VERSION "HNNBNNNYNNNNNNNNNNNNNNNNNNNNNNNNNNNNNNNNNN/4/%%%/4/'%**4NNN///"

NS_ :

BS_:

BU_: BAP_Tester BCM Gateway_Max TSGGen3_BFS TSGGen3_FS TSGGen3_HBFS TSGGen3_HFS WLC_01_CFD

BO_ 2463978735 DoorFunctions_HBFS_01: 32 TSGGen3_BFS
 SG_ DoorFunctions_HBFS_01_CRC : 0|8@1+ (1,0) [0|255] ""  Gateway_Max,TSGGen3_BFS,TSGGen3_FS,TSGGen3_HFS
 SG_ DoorFunctions_HBFS_01_BZ : 8|4@1+ (1,0) [0|15] ""  Gateway_Max,TSGGen3_BFS,TSGGen3_FS,TSGGen3_HFS
 SG_ HBFS_FH_S_HFS_ManHoch : 12|1@1+ (1.0,0.0) [0.0|1] ""  Gateway_Max,TSGGen3_BFS,TSGGen3_FS,TSGGen3_HFS
 SG_ HBFS_FH_S_HFS_ManTief : 13|1@1+ (1.0,0.0) [0.0|1] ""  Gateway_Max,TSGGen3_BFS,TSGGen3_FS,TSGGen3_HFS
 SG_ HBFS_Tuer_Status : 14|2@1+ (1.0,0.0) [0.0|3] ""  Gateway_Max,TSGGen3_FS
 SG_ HBFS_SAD_Schalter : 16|4@1+ (1.0,0.0) [0.0|15] ""  Gateway_Max,TSGGen3_BFS
 SG_ HBFS_FH_S_ManHoch : 20|1@1+ (1.0,0.0) [0.0|1] ""  Gateway_Max
 SG_ HBFS_FH_S_AutoHoch : 21|1@1+ (1.0,0.0) [0.0|1] ""  Gateway_Max,TSGGen3_HFS
 SG_ HBFS_FH_S_ManTief : 22|1@1+ (1.0,0.0) [0.0|1] ""  Gateway_Max
 SG_ HBFS_FH_S_AutoTief : 23|1@1+ (1.0,0.0) [0.0|1] ""  Gateway_Max
 SG_ HBFS_FH_Oeffnung : 24|8@1+ (0.5,0) [0.0|100.0] "Unit_PerCent"  Gateway_Max
 SG_ HBFS_FH_Bew_hoch : 32|1@1+ (1.0,0.0) [0.0|1] ""  Gateway_Max,TSGGen3_BFS,TSGGen3_FS
 SG_ HBFS_FH_Bew_tief : 33|1@1+ (1.0,0.0) [0.0|1] ""  Gateway_Max,TSGGen3_BFS,TSGGen3_FS
 SG_ HBFS_FH_Fang : 34|1@1+ (1.0,0.0) [0.0|1] ""  Gateway_Max
 SG_ HBFS_FH_Block : 35|1@1+ (1.0,0.0) [0.0|1] ""  Gateway_Max
 SG_ HBFS_FH_Thermo : 36|1@1+ (1.0,0.0) [0.0|1] ""  Gateway_Max
 SG_ HBFS_UEKB_aktiviert : 37|1@1+ (1.0,0.0) [0.0|1] ""  Gateway_Max
 SG_ HBFS_Tueroeffnen_Warnung : 38|1@1+ (1.0,0.0) [0.0|1] ""  Gateway_Max
 SG_ HBFS_FH_normiert : 39|1@1+ (1.0,0.0) [0.0|1] ""  Gateway_Max,TSGGen3_FS
 SG_ ASW_Warnung_aktiv_HBFS : 40|1@1+ (1.0,0.0) [0.0|1] ""  Gateway_Max
 SG_ HBFS_Zuziehhilfe_aktiv : 41|1@1+ (1.0,0.0) [0.0|1] ""  Gateway_Max
 SG_ HBFS_Seitenrollo_hoch : 42|1@1+ (1.0,0.0) [0.0|1] ""  Gateway_Max
 SG_ HBFS_Seitenrollo_tief : 43|1@1+ (1.0,0.0) [0.0|1] ""  Gateway_Max
 SG_ HBFS_Status_KiSi : 44|1@1+ (1.0,0.0) [0.0|1] ""  Gateway_Max,TSGGen3_BFS,TSGGen3_FS
 SG_ SSR_HBFS_Pos_Unten : 45|1@1+ (1.0,0.0) [0.0|1] ""  Gateway_Max
 SG_ HBFS_Oben_Block_erw : 46|1@1+ (1.0,0.0) [0.0|1] ""  Gateway_Max,TSGGen3_BFS,TSGGen3_FS,TSGGen3_HFS
 SG_ HBFS_Unten_Block_erw : 47|1@1+ (1.0,0.0) [0.0|1] ""  Gateway_Max,TSGGen3_BFS,TSGGen3_FS,TSGGen3_HFS
 SG_ MTHBFS_M_Taste : 48|1@1+ (1.0,0.0) [0.0|1] ""  Gateway_Max
 SG_ MTHBFS_Pos1 : 49|1@1+ (1.0,0.0) [0.0|1] ""  Gateway_Max
 SG_ MTHBFS_Pos2 : 50|1@1+ (1.0,0.0) [0.0|1] ""  Gateway_Max
 SG_ MTHBFS_Pos3 : 51|1@1+ (1.0,0.0) [0.0|1] ""  Gateway_Max
 SG_ HBFS_MRollo_Schalter : 52|3@1+ (1.0,0.0) [0.0|7] ""  Gateway_Max,TSGGen3_BFS
 SG_ HBFS_Lock_Taster_inv : 55|1@1+ (1.0,0.0) [0.0|1] ""  Gateway_Max
 SG_ HBFS_Status_KiSi_inv : 56|1@1+ (1.0,0.0) [0.0|1] ""  Gateway_Max,TSGGen3_BFS,TSGGen3_FS
 SG_ HBFS_Status_eTAG : 57|2@1+ (1.0,0.0) [0.0|3] ""  Gateway_Max,TSGGen3_FS
 SG_ HBFS_Tuer_Status_QBit : 59|1@1+ (1.0,0.0) [0.0|1] ""  Gateway_Max,TSGGen3_FS
 SG_ HBFS_TIG_betaetigt_schliessen : 60|1@1+ (1.0,0.0) [0.0|1] ""  Gateway_Max
 SG_ HBFS_TIG_betaetigt_oeffnen : 61|1@1+ (1.0,0.0) [0.0|1] ""  Gateway_Max
 SG_ HBFS_Vorraste_betaetigt : 62|1@1+ (1.0,0.0) [0.0|1] ""  Gateway_Max
 SG_ HBFS_SK_betaetigt : 63|1@1+ (1.0,0.0) [0.0|1] ""  Gateway_Max
 SG_ HBFS_KiSi_Fehler : 64|1@1+ (1.0,0.0) [0.0|1] ""  Gateway_Max,TSGGen3_FS
 SG_ HBFS_TCR_Mode_aktiv : 65|1@1+ (1.0,0.0) [0.0|1] ""  Gateway_Max,TSGGen3_BFS,TSGGen3_FS,TSGGen3_HFS
 SG_ SSA_HBFT_FH_Thermoschutz : 66|1@1+ (1.0,0.0) [0.0|1] ""  Gateway_Max
 SG_ SSA_HBFT_ZZH_Status : 67|1@1+ (1.0,0.0) [0.0|1] ""  Gateway_Max
 SG_ SSA_HBFT_SSR_Status : 68|2@1+ (1.0,0.0) [0.0|3] ""  Gateway_Max
 SG_ SSA_HBFT_ASW_Status : 70|2@1+ (1.0,0.0) [0.0|3] ""  Gateway_Max,TSGGen3_BFS
 SG_ TSG_FlHz_HBFS_NTC_A : 72|7@1+ (1,-40) [-40|80] "Unit_DegreCelsi"  Gateway_Max
 SG_ TSG_FlHz_HBFS_FnAbbruchHzKreis_A : 79|1@1+ (1.0,0.0) [0.0|1] ""  Gateway_Max
 SG_ TSG_FlHz_HBFS_NTC_B : 80|7@1+ (1,-40) [-40|80] "Unit_DegreCelsi"  Gateway_Max
 SG_ TSG_FlHz_HBFS_FnAbbruchHzKreis_B : 87|1@1+ (1.0,0.0) [0.0|1] ""  Gateway_Max
 SG_ SSA_HBFT_Tuerverschluss_Status : 88|2@1+ (1.0,0.0) [0.0|3] ""  Gateway_Max
 SG_ SSA_HBFT_el_Tuerantrieb_Status : 90|2@1+ (1.0,0.0) [0.0|3] ""  Gateway_Max
 SG_ SSA_HBFT_Amb_Bel_Status : 92|2@1+ (1.0,0.0) [0.0|3] ""  Gateway_Max
 SG_ SSA_HBFT_FH_Bewegungsrichutng : 94|2@1+ (1.0,0.0) [0.0|3] ""  Gateway_Max
 SG_ BFS_Lehnenkopf_vor : 96|1@1+ (1.0,0.0) [0.0|1] ""  Gateway_Max
 SG_ BFS_Lehnenkopf_zurueck : 97|1@1+ (1.0,0.0) [0.0|1] ""  Gateway_Max
 SG_ BFS_Lehnenneigung_vor : 98|1@1+ (1.0,0.0) [0.0|1] ""  Gateway_Max
 SG_ BFS_Lehnenneigung_zurueck : 99|1@1+ (1.0,0.0) [0.0|1] ""  Gateway_Max
 SG_ BFS_Sitzhoehe_hoch : 100|1@1+ (1.0,0.0) [0.0|1] ""  Gateway_Max
 SG_ BFS_Sitzhoehe_runter : 101|1@1+ (1.0,0.0) [0.0|1] ""  Gateway_Max
 SG_ BFS_Kopfstuetzen_hoch : 102|1@1+ (1.0,0.0) [0.0|1] ""  Gateway_Max
 SG_ BFS_Kopfstuetzen_runter : 103|1@1+ (1.0,0.0) [0.0|1] ""  Gateway_Max
 SG_ BFS_Laengsverst_vor : 104|1@1+ (1.0,0.0) [0.0|1] ""  Gateway_Max
 SG_ BFS_Laengsverst_zurueck : 105|1@1+ (1.0,0.0) [0.0|1] ""  Gateway_Max
 SG_ MTHBF_ein : 106|1@1+ (1.0,0.0) [0.0|1] ""  Gateway_Max
 SG_ SSA_HBFS_eKisi_Status : 107|2@1+ (1.0,0.0) [0.0|3] ""  Gateway_Max
 SG_ SSA_HBFT_Tuerverschluss_Fehler : 109|3@1+ (1.0,0.0) [0.0|7] ""  Gateway_Max
 SG_ SSA_HBFT_FH_Fehler : 112|3@1+ (1.0,0.0) [0.0|7] ""  Gateway_Max
 SG_ SSA_HBFS_eKisi_Fehler : 115|3@1+ (1.0,0.0) [0.0|7] ""  Gateway_Max
 SG_ SSA_HBFT_Amb_Bel_Fehler : 118|3@1+ (1.0,0.0) [0.0|7] ""  Gateway_Max
 SG_ SSA_HBFT_FH_Normierung : 121|1@1+ (1.0,0.0) [0.0|1] ""  Gateway_Max
 SG_ SSA_HBFT_el_Tuerantrieb_Fehler : 122|3@1+ (1.0,0.0) [0.0|7] ""  Gateway_Max
 SG_ SSA_HBFT_ZZH_Fehler : 125|3@1+ (1.0,0.0) [0.0|7] ""  Gateway_Max
 SG_ SSA_HBFT_ZV_Fehler : 128|3@1+ (1.0,0.0) [0.0|7] ""  Gateway_Max
 SG_ SSA_HBFT_ASW_Fehler : 131|3@1+ (1.0,0.0) [0.0|7] ""  Gateway_Max
 SG_ SSA_HBFT_SSR_Fehler : 134|3@1+ (1.0,0.0) [0.0|7] ""  Gateway_Max
 SG_ eTAB_HBFS_Oeffnen_Annaeh : 137|1@1+ (1.0,0.0) [0.0|1] ""  Gateway_Max
 SG_ eTAB_HBFS_Oeffnen_Betaet : 138|1@1+ (1.0,0.0) [0.0|1] ""  Gateway_Max
 SG_ eTAB_HBFS_Schliessen_Annaeh : 139|1@1+ (1.0,0.0) [0.0|1] ""  Gateway_Max
 SG_ HBFS_ASW_Warnung_Aussenlicht : 140|2@1+ (1.0,0.0) [0.0|3] ""  Gateway_Max
 SG_ HBFS_ASW_Warnton : 142|2@1+ (1.0,0.0) [0.0|3] ""  Gateway_Max
 SG_ HBFS_Tuer_geoeffnet : 144|1@1+ (1.0,0.0) [0.0|1] ""  Gateway_Max,TSGGen3_BFS,TSGGen3_FS,TSGGen3_HFS
 SG_ HBFS_verriegelt : 145|1@1+ (1.0,0.0) [0.0|1] ""  Gateway_Max,TSGGen3_FS
 SG_ HBFS_gesafet : 146|1@1+ (1.0,0.0) [0.0|1] ""  Gateway_Max,TSGGen3_FS
 SG_ HBFS_Heckrollotaster_betaetigt : 147|1@1+ (1.0,0.0) [0.0|1] ""  Gateway_Max
 SG_ HBFS_Tuerschloss_defekt : 148|1@1+ (1.0,0.0) [0.0|1] ""  Gateway_Max,TSGGen3_BFS,TSGGen3_FS,TSGGen3_HFS
 SG_ HBFS_Unlock_Taster : 149|1@1+ (1.0,0.0) [0.0|1] ""  Gateway_Max
 SG_ HBFS_Lock_Taster : 150|1@1+ (1.0,0.0) [0.0|1] ""  Gateway_Max
 SG_ HBFS_Sperrklinke : 151|1@1+ (1.0,0.0) [0.0|1] ""  Gateway_Max
 SG_ HBFS_TAG_betaetigt : 152|1@1+ (1.0,0.0) [0.0|1] ""  Gateway_Max
 SG_ HBFS_TIG_betaetigt : 153|1@1+ (1.0,0.0) [0.0|1] ""  Gateway_Max
 SG_ HBFS_FH_S_HFS_AutoHoch : 154|1@1+ (1.0,0.0) [0.0|1] ""  Gateway_Max,TSGGen3_BFS,TSGGen3_FS,TSGGen3_HFS
 SG_ HBFS_FH_S_HFS_AutoTief : 155|1@1+ (1.0,0.0) [0.0|1] ""  Gateway_Max,TSGGen3_BFS,TSGGen3_FS,TSGGen3_HFS
 SG_ SSA_HBFT_FH_Oeffnungsweite : 156|8@1+ (0.5,0) [0.0|100.0] "Unit_PerCent"  Gateway_Max,TSGGen3_FS,TSGGen3_HFS
 SG_ TSG_FlHz_HBFS_Unterbrech_HzK_A : 164|1@1+ (1.0,0.0) [0.0|1] ""  Gateway_Max
 SG_ TSG_FlHz_HBFS_Unterbrech_HzK_B : 165|1@1+ (1.0,0.0) [0.0|1] ""  Gateway_Max
 SG_ HBFS_ASW_HMI_defekt : 176|1@1+ (1.0,0.0) [0.0|1] ""  Gateway_Max,TSGGen3_FS
 SG_ eTAB_HBFS_Schliessen_Betaet : 177|1@1+ (1.0,0.0) [0.0|1] ""  Gateway_Max
 SG_ HBFS_Push_Tuergriff : 179|1@1+ (1.0,0.0) [0.0|1] ""  Gateway_Max
 SG_ HBFS_Status_eTAG_ext : 180|3@1+ (1.0,0.0) [0.0|7] ""  Gateway_Max
 SG_ HBFS_Schloss_Status_OeH_Motor : 184|2@1+ (1.0,0.0) [0.0|3] ""  Gateway_Max
 SG_ HBFS_Schloss_oeffnen_Ansteuerung : 186|2@1+ (1.0,0.0) [0.0|3] ""  Gateway_Max
 SG_ SOK_Doorfunctions_HBFS_01_Sig001 : 224|32@1+ (1.0,0.0) [0.0|4294967295] ""  Gateway_Max

BO_ 2463978736 DoorFunctions_HFS_01: 32 TSGGen3_FS
 SG_ DoorFunctions_HFS_01_CRC : 0|8@1+ (1,0) [0|255] ""  Gateway_Max,TSGGen3_BFS,TSGGen3_FS,TSGGen3_HBFS
 SG_ DoorFunctions_HFS_01_BZ : 8|4@1+ (1,0) [0|15] ""  Gateway_Max,TSGGen3_BFS,TSGGen3_FS,TSGGen3_HBFS
 SG_ HFS_FH_S_HBFS_ManHoch : 12|1@1+ (1.0,0.0) [0.0|1] ""  Gateway_Max,TSGGen3_BFS,TSGGen3_FS,TSGGen3_HBFS
 SG_ HFS_FH_S_HBFS_ManTief : 13|1@1+ (1.0,0.0) [0.0|1] ""  Gateway_Max,TSGGen3_BFS,TSGGen3_FS,TSGGen3_HBFS
 SG_ HFS_Tuer_Status : 14|2@1+ (1.0,0.0) [0.0|3] ""  Gateway_Max,TSGGen3_FS
 SG_ HFS_SAD_Schalter : 16|4@1+ (1.0,0.0) [0.0|15] ""  Gateway_Max
 SG_ HFS_FH_S_ManHoch : 20|1@1+ (1.0,0.0) [0.0|1] ""  Gateway_Max
 SG_ HFS_FH_S_AutoHoch : 21|1@1+ (1.0,0.0) [0.0|1] ""  Gateway_Max
 SG_ HFS_FH_S_ManTief : 22|1@1+ (1.0,0.0) [0.0|1] ""  Gateway_Max
 SG_ HFS_FH_S_AutoTief : 23|1@1+ (1.0,0.0) [0.0|1] ""  Gateway_Max
 SG_ HFS_FH_Oeffnung : 24|8@1+ (0.5,0) [0.0|100.0] "Unit_PerCent"  Gateway_Max
 SG_ HFS_FH_Bew_hoch : 32|1@1+ (1.0,0.0) [0.0|1] ""  Gateway_Max,TSGGen3_BFS,TSGGen3_FS,TSGGen3_HBFS
 SG_ HFS_FH_Bew_tief : 33|1@1+ (1.0,0.0) [0.0|1] ""  Gateway_Max,TSGGen3_BFS,TSGGen3_FS,TSGGen3_HBFS
 SG_ HFS_FH_Fang : 34|1@1+ (1.0,0.0) [0.0|1] ""  Gateway_Max
 SG_ HFS_FH_Block : 35|1@1+ (1.0,0.0) [0.0|1] ""  Gateway_Max
 SG_ HFS_FH_Thermo : 36|1@1+ (1.0,0.0) [0.0|1] ""  Gateway_Max
 SG_ HFS_UEKB_aktiviert : 37|1@1+ (1.0,0.0) [0.0|1] ""  Gateway_Max
 SG_ HFS_Tueroeffnen_Warnung : 38|1@1+ (1.0,0.0) [0.0|1] ""  Gateway_Max
 SG_ HFS_FH_normiert : 39|1@1+ (1.0,0.0) [0.0|1] ""  Gateway_Max,TSGGen3_BFS,TSGGen3_FS,TSGGen3_HBFS
 SG_ ASW_Warnung_aktiv_HFS : 40|1@1+ (1.0,0.0) [0.0|1] ""  Gateway_Max
 SG_ HFS_Zuziehhilfe_aktiv : 41|1@1+ (1.0,0.0) [0.0|1] ""  Gateway_Max
 SG_ HFS_Seitenrollo_hoch : 42|1@1+ (1.0,0.0) [0.0|1] ""  Gateway_Max
 SG_ HFS_Seitenrollo_tief : 43|1@1+ (1.0,0.0) [0.0|1] ""  Gateway_Max
 SG_ HFS_Status_KiSi : 44|1@1+ (1.0,0.0) [0.0|1] ""  Gateway_Max,TSGGen3_BFS,TSGGen3_FS,TSGGen3_HBFS
 SG_ SSR_HFS_Pos_Unten : 45|1@1+ (1.0,0.0) [0.0|1] ""  Gateway_Max,TSGGen3_BFS,TSGGen3_HBFS
 SG_ HFS_Oben_Block_erw : 46|1@1+ (1.0,0.0) [0.0|1] ""  Gateway_Max,TSGGen3_BFS,TSGGen3_FS,TSGGen3_HBFS
 SG_ HFS_Unten_Block_erw : 47|1@1+ (1.0,0.0) [0.0|1] ""  Gateway_Max,TSGGen3_BFS,TSGGen3_FS,TSGGen3_HBFS
 SG_ MTHFS_M_Taste : 48|1@1+ (1.0,0.0) [0.0|1] ""  Gateway_Max
 SG_ MTHFS_Pos1 : 49|1@1+ (1.0,0.0) [0.0|1] ""  Gateway_Max
 SG_ MTHFS_Pos2 : 50|1@1+ (1.0,0.0) [0.0|1] ""  Gateway_Max
 SG_ MTHFS_Pos3 : 51|1@1+ (1.0,0.0) [0.0|1] ""  Gateway_Max
 SG_ HFS_MRollo_Schalter : 52|3@1+ (1.0,0.0) [0.0|7] ""  Gateway_Max
 SG_ HFS_Lock_Taster_inv : 55|1@1+ (1.0,0.0) [0.0|1] ""  Gateway_Max
 SG_ HFS_Status_eTAG : 56|2@1+ (1.0,0.0) [0.0|3] ""  Gateway_Max,TSGGen3_BFS,TSGGen3_HBFS
 SG_ HFS_Tuer_Status_QBit : 58|1@1+ (1.0,0.0) [0.0|1] ""  Gateway_Max,TSGGen3_FS
 SG_ HFS_TCR_Mode_aktiv : 59|1@1+ (1.0,0.0) [0.0|1] ""  Gateway_Max,TSGGen3_BFS,TSGGen3_FS,TSGGen3_HBFS
 SG_ HFS_TIG_betaetigt_schliessen : 60|1@1+ (1.0,0.0) [0.0|1] ""  Gateway_Max
 SG_ HFS_TIG_betaetigt_oeffnen : 61|1@1+ (1.0,0.0) [0.0|1] ""  Gateway_Max
 SG_ HFS_Vorraste_betaetigt : 62|1@1+ (1.0,0.0) [0.0|1] ""  Gateway_Max
 SG_ HFS_SK_betaetigt : 63|1@1+ (1.0,0.0) [0.0|1] ""  Gateway_Max
 SG_ TSG_FlHz_HFS_NTC_A : 64|7@1+ (1,-40) [-40|80] "Unit_DegreCelsi"  Gateway_Max
 SG_ TSG_FlHz_HFS_FnAbbruchHzKreis_A : 71|1@1+ (1.0,0.0) [0.0|1] ""  Gateway_Max
 SG_ TSG_FlHz_HFS_NTC_B : 72|7@1+ (1,-40) [-40|80] "Unit_DegreCelsi"  Gateway_Max
 SG_ TSG_FlHz_HFS_FnAbbruchHzKreis_B : 79|1@1+ (1.0,0.0) [0.0|1] ""  Gateway_Max
 SG_ SSA_HFT_Tuerverschluss_Status : 80|2@1+ (1.0,0.0) [0.0|3] ""  Gateway_Max
 SG_ SSA_HFT_el_Tuerantrieb_Status : 82|2@1+ (1.0,0.0) [0.0|3] ""  Gateway_Max
 SG_ SSA_HFT_ZV_Status : 84|4@1+ (1.0,0.0) [0.0|15] ""  Gateway_Max
 SG_ eTAB_HFS_Oeffnen_Annaeh : 88|1@1+ (1.0,0.0) [0.0|1] ""  Gateway_Max
 SG_ eTAB_HFS_Oeffnen_Betaet : 89|1@1+ (1.0,0.0) [0.0|1] ""  Gateway_Max
 SG_ eTAB_HFS_Schliessen_Annaeh : 90|1@1+ (1.0,0.0) [0.0|1] ""  Gateway_Max
 SG_ eTAB_HFS_Schliessen_Betaet : 91|1@1+ (1.0,0.0) [0.0|1] ""  Gateway_Max
 SG_ SSA_HFT_Amb_Bel_Status : 92|2@1+ (1.0,0.0) [0.0|3] ""  Gateway_Max
 SG_ SSA_HFT_FH_Bewegungsrichutng : 94|2@1+ (1.0,0.0) [0.0|3] ""  Gateway_Max
 SG_ SSA_HFT_SSR_Status : 96|2@1+ (1.0,0.0) [0.0|3] ""  Gateway_Max
 SG_ SSA_HFS_eKisi_Status : 98|2@1+ (1.0,0.0) [0.0|3] ""  Gateway_Max
 SG_ SSA_HFT_ZZH_Status : 100|1@1+ (1.0,0.0) [0.0|1] ""  Gateway_Max
 SG_ SSA_HFT_ASW_Status : 101|2@1+ (1.0,0.0) [0.0|3] ""  Gateway_Max,TSGGen3_FS
 SG_ SSA_HFT_ZV_Ansteuern : 103|8@1+ (1.0,0.0) [0.0|255] ""  Gateway_Max
 SG_ SSA_HFT_FH_Thermoschutz : 111|1@1+ (1.0,0.0) [0.0|1] ""  Gateway_Max
 SG_ SSA_HFT_Tuerverschluss_Fehler : 112|3@1+ (1.0,0.0) [0.0|7] ""  Gateway_Max
 SG_ SSA_HFT_SSR_Fehler : 115|3@1+ (1.0,0.0) [0.0|7] ""  Gateway_Max
 SG_ SSA_HFT_Amb_Bel_Fehler : 118|3@1+ (1.0,0.0) [0.0|7] ""  Gateway_Max
 SG_ SSA_HFT_FH_Fehler : 121|3@1+ (1.0,0.0) [0.0|7] ""  Gateway_Max
 SG_ SSA_HFS_eKisi_Fehler : 124|3@1+ (1.0,0.0) [0.0|7] ""  Gateway_Max
 SG_ SSA_HFT_ZZH_Fehler : 127|3@1+ (1.0,0.0) [0.0|7] ""  Gateway_Max
 SG_ SSA_HFT_ZV_Fehler : 130|3@1+ (1.0,0.0) [0.0|7] ""  Gateway_Max
 SG_ SSA_HFT_el_Tuerantrieb_Fehler : 133|3@1+ (1.0,0.0) [0.0|7] ""  Gateway_Max
 SG_ SSA_HFT_ASW_Fehler : 136|3@1+ (1.0,0.0) [0.0|7] ""  Gateway_Max
 SG_ SSA_HFT_FH_Normierung : 139|1@1+ (1.0,0.0) [0.0|1] ""  Gateway_Max
 SG_ HFS_Schloss_Status_OeH_Motor : 140|2@1+ (1.0,0.0) [0.0|3] ""  Gateway_Max
 SG_ HFS_Tuer_geoeffnet : 144|1@1+ (1.0,0.0) [0.0|1] ""  Gateway_Max,TSGGen3_BFS,TSGGen3_FS,TSGGen3_HBFS
 SG_ HFS_verriegelt : 145|1@1+ (1.0,0.0) [0.0|1] ""  Gateway_Max,TSGGen3_FS
 SG_ HFS_gesafet : 146|1@1+ (1.0,0.0) [0.0|1] ""  Gateway_Max,TSGGen3_BFS,TSGGen3_HBFS
 SG_ HFS_Heckrollotaster_betaetigt : 147|1@1+ (1.0,0.0) [0.0|1] ""  Gateway_Max
 SG_ HFS_Tuerschloss_defekt : 148|1@1+ (1.0,0.0) [0.0|1] ""  Gateway_Max,TSGGen3_BFS,TSGGen3_FS,TSGGen3_HBFS
 SG_ HFS_Unlock_Taster : 149|1@1+ (1.0,0.0) [0.0|1] ""  Gateway_Max
 SG_ HFS_Lock_Taster : 150|1@1+ (1.0,0.0) [0.0|1] ""  Gateway_Max
 SG_ HFS_Sperrklinke : 151|1@1+ (1.0,0.0) [0.0|1] ""  Gateway_Max
 SG_ HFS_TAG_betaetigt : 152|1@1+ (1.0,0.0) [0.0|1] ""  Gateway_Max
 SG_ HFS_TIG_betaetigt : 153|1@1+ (1.0,0.0) [0.0|1] ""  Gateway_Max
 SG_ HFS_FH_S_HBFS_AutoHoch : 154|1@1+ (1.0,0.0) [0.0|1] ""  Gateway_Max,TSGGen3_BFS,TSGGen3_FS,TSGGen3_HBFS
 SG_ HFS_FH_S_HBFS_AutoTief : 155|1@1+ (1.0,0.0) [0.0|1] ""  Gateway_Max,TSGGen3_BFS,TSGGen3_FS,TSGGen3_HBFS
 SG_ TSG_FlHz_HFS_Unterbrech_HzK_A : 156|1@1+ (1.0,0.0) [0.0|1] ""  Gateway_Max
 SG_ HFS_Push_Tuergriff : 159|1@1+ (1.0,0.0) [0.0|1] ""  Gateway_Max
 SG_ HFS_Status_eTAG_ext : 202|3@1+ (1.0,0.0) [0.0|7] ""  Gateway_Max
 SG_ HFS_KiSi_Fehler : 205|1@1+ (1.0,0.0) [0.0|1] ""  Gateway_Max,TSGGen3_FS
 SG_ HFS_ASW_Warnton : 206|2@1+ (1.0,0.0) [0.0|3] ""  Gateway_Max,TSGGen3_BFS,TSGGen3_FS
 SG_ HFS_Schloss_oeffnen_Ansteuerung : 208|2@1+ (1.0,0.0) [0.0|3] ""  Gateway_Max
 SG_ HFS_ASW_HMI_defekt : 212|1@1+ (1.0,0.0) [0.0|1] ""  Gateway_Max,TSGGen3_FS
 SG_ HFS_ASW_Warnung_Aussenlicht : 213|2@1+ (1.0,0.0) [0.0|3] ""  Gateway_Max
 SG_ SOK_Doorfunctions_HFS_01_Sign002 : 224|32@1+ (1.0,0.0) [0.0|4294967295] ""  Gateway_Max

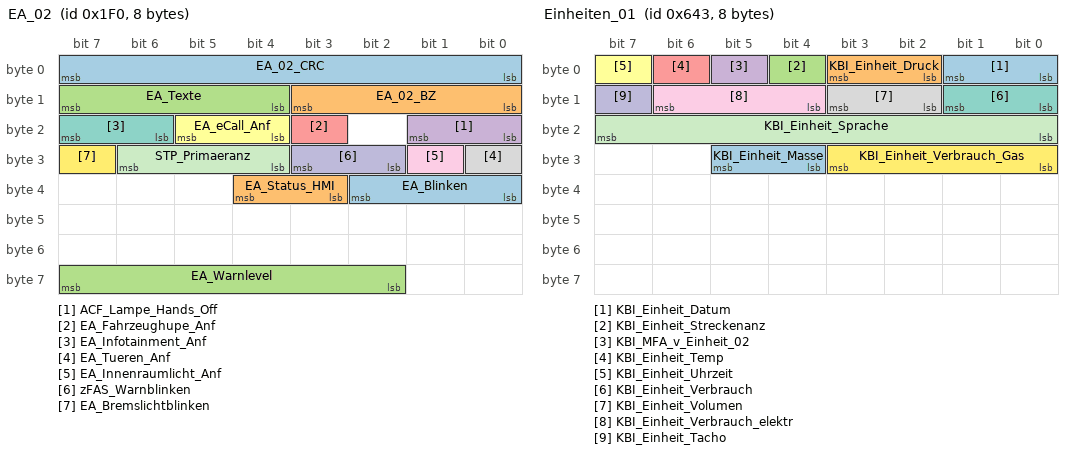
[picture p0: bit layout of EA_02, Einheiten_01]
BO_ 496 EA_02: 8 Gateway_Max
 SG_ EA_02_CRC : 0|8@1+ (1,0) [0|255] ""  BCM
 SG_ EA_02_BZ : 8|4@1+ (1,0) [0|15] ""  BCM
 SG_ EA_Texte : 12|4@1+ (1.0,0.0) [0.0|15] ""  Vector__XXX
 SG_ ACF_Lampe_Hands_Off : 16|2@1+ (1.0,0.0) [0.0|3] ""  Vector__XXX
 SG_ EA_Fahrzeughupe_Anf : 19|1@1+ (1.0,0.0) [0.0|1] ""  BCM
 SG_ EA_eCall_Anf : 20|2@1+ (1.0,0.0) [0.0|3] ""  Vector__XXX
 SG_ EA_Infotainment_Anf : 22|2@1+ (1.0,0.0) [0.0|3] ""  Vector__XXX
 SG_ EA_Tueren_Anf : 24|1@1+ (1.0,0.0) [0.0|1] ""  BCM
 SG_ EA_Innenraumlicht_Anf : 25|1@1+ (1.0,0.0) [0.0|1] ""  BCM
 SG_ zFAS_Warnblinken : 26|2@1+ (1.0,0.0) [0.0|3] ""  Vector__XXX
 SG_ STP_Primaeranz : 28|3@1+ (1.0,0.0) [0.0|7] ""  Vector__XXX
 SG_ EA_Bremslichtblinken : 31|1@1+ (1.0,0.0) [0.0|1] ""  BCM
 SG_ EA_Blinken : 32|3@1+ (1.0,0.0) [0.0|7] ""  BCM
 SG_ EA_Status_HMI : 35|2@1+ (1.0,0.0) [0.0|3] ""  Vector__XXX
 SG_ EA_Warnlevel : 58|6@1+ (1.0,0.0) [0.0|63] ""  Vector__XXX

BO_ 1603 Einheiten_01: 8 Gateway_Max
 SG_ KBI_Einheit_Datum : 0|2@1+ (1.0,0.0) [0.0|3] ""  BCM
 SG_ KBI_Einheit_Druck : 2|2@1+ (1.0,0.0) [0.0|3] ""  BCM
 SG_ KBI_Einheit_Streckenanz : 4|1@1+ (1.0,0.0) [0.0|1] ""  BCM
 SG_ KBI_MFA_v_Einheit_02 : 5|1@1+ (1.0,0.0) [0.0|1] ""  BCM
 SG_ KBI_Einheit_Temp : 6|1@1+ (1.0,0.0) [0.0|1] ""  BCM
 SG_ KBI_Einheit_Uhrzeit : 7|1@1+ (1.0,0.0) [0.0|1] ""  BCM
 SG_ KBI_Einheit_Verbrauch : 8|2@1+ (1.0,0.0) [0.0|3] ""  BCM
 SG_ KBI_Einheit_Volumen : 10|2@1+ (1.0,0.0) [0.0|3] ""  BCM
 SG_ KBI_Einheit_Verbrauch_elektr : 12|3@1+ (1.0,0.0) [0.0|7] ""  BCM
 SG_ KBI_Einheit_Tacho : 15|1@1+ (1.0,0.0) [0.0|1] ""  BCM
 SG_ KBI_Einheit_Sprache : 16|8@1+ (1,0) [0|255] ""  BCM
 SG_ KBI_Einheit_Verbrauch_Gas : 24|4@1+ (1.0,0.0) [0.0|15] ""  BCM
 SG_ KBI_Einheit_Masse : 28|2@1+ (1.0,0.0) [0.0|3] ""  BCM

BO_ 1622 ELV_01: 8 Gateway_Max
 SG_ ELV_01_CRC : 0|8@1+ (1,0) [0|255] ""  BCM
 SG_ ELV_01_BZ : 8|4@1+ (1,0) [0|15] ""  BCM
 SG_ ELV_Anf_Klemme_S : 12|1@1+ (1.0,0.0) [0.0|1] ""  BCM
 SG_ ELV_Anf_Klemme_15 : 13|1@1+ (1.0,0.0) [0.0|1] ""  BCM
 SG_ ELV_Anf_Klemme_50 : 14|1@1+ (1.0,0.0) [0.0|1] ""  BCM
 SG_ ELV_01_Sendestatus : 15|1@1+ (1.0,0.0) [0.0|1] ""  BCM
 SG_ ELV_Verriegelt : 16|1@1+ (1.0,0.0) [0.0|1] ""  BCM
 SG_ ELV_Entriegelt : 17|1@1+ (1.0,0.0) [0.0|1] ""  BCM
 SG_ ELV_ZAT_betaetigt : 18|1@1+ (1.0,0.0) [0.0|1] ""  BCM
 SG_ ELV_Lebenszustand : 19|1@1+ (1.0,0.0) [0.0|1] ""  BCM
 SG_ ELV_Anlernmodus : 20|1@1+ (1.0,0.0) [0.0|1] ""  BCM
 SG_ KST_aut_Abschaltung_Zuendung : 21|1@1+ (1.0,0.0) [0.0|1] ""  BCM
 SG_ ELV_Klemmenfreigabe : 22|1@1+ (1.0,0.0) [0.0|1] ""  BCM
 SG_ ELV_Abbruch_Anf_Klemmenfreigabe : 23|1@1+ (1.0,0.0) [0.0|1] ""  BCM
 SG_ ELV_LED_Rot : 24|1@1+ (1.0,0.0) [0.0|1] ""  BCM
 SG_ ELV_LED_Gelb : 25|1@1+ (1.0,0.0) [0.0|1] ""  BCM
 SG_ ELV_Txt_Panikabschaltung : 27|1@1+ (1.0,0.0) [0.0|1] ""  BCM
 SG_ ELV_Txt_Lkg_Bewegen : 28|1@1+ (1.0,0.0) [0.0|1] ""  BCM
 SG_ ELV_Txt_Werkstatt : 29|1@1+ (1.0,0.0) [0.0|1] ""  BCM
 SG_ ELV_Txt_Defekt : 30|1@1+ (1.0,0.0) [0.0|1] ""  BCM
 SG_ ELV_Txt_P_Gang : 31|1@1+ (1.0,0.0) [0.0|1] ""  BCM
 SG_ ELV_Txt_PN_Gang : 32|1@1+ (1.0,0.0) [0.0|1] ""  BCM
 SG_ ELV_Txt_Kupplung : 33|1@1+ (1.0,0.0) [0.0|1] ""  BCM
 SG_ ELV_Txt_Bremse : 34|1@1+ (1.0,0.0) [0.0|1] ""  BCM
 SG_ ELV_P_verriegelt : 35|1@1+ (1.0,0.0) [0.0|1] ""  BCM
 SG_ KST_Txt_Komfortabschaltung : 36|1@1+ (1.0,0.0) [0.0|1] ""  BCM
 SG_ KST_Anf_ZV_Verriegelung : 37|1@1+ (1.0,0.0) [0.0|1] ""  BCM

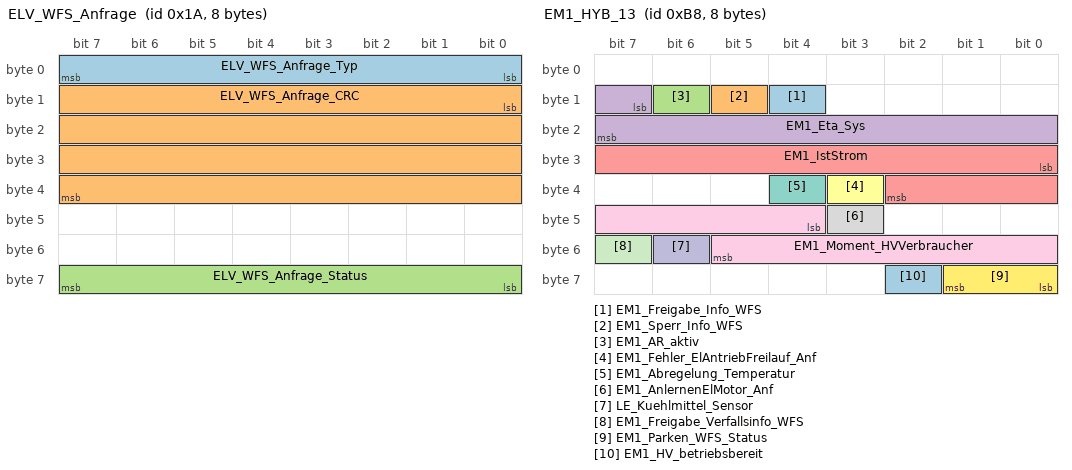
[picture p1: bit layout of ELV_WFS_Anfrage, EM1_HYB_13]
BO_ 26 ELV_WFS_Anfrage: 8 Gateway_Max
 SG_ ELV_WFS_Anfrage_Typ : 0|8@1+ (1.0,0.0) [0.0|255] ""  BCM
 SG_ ELV_WFS_Anfrage_CRC : 8|32@1+ (1.0,0.0) [0.0|4294967295] ""  BCM
 SG_ ELV_WFS_Anfrage_Status : 56|8@1+ (1.0,0.0) [0.0|255] ""  BCM

BO_ 184 EM1_HYB_13: 8 Gateway_Max
 SG_ EM1_Freigabe_Info_WFS : 12|1@1+ (1.0,0.0) [0.0|1] ""  Vector__XXX
 SG_ EM1_Sperr_Info_WFS : 13|1@1+ (1.0,0.0) [0.0|1] ""  BCM
 SG_ EM1_AR_aktiv : 14|1@1+ (1.0,0.0) [0.0|1] ""  Vector__XXX
 SG_ EM1_Eta_Sys : 15|9@1+ (0.2,0) [0.0|101.8] "Unit_PerCent"  Vector__XXX
 SG_ EM1_IstStrom : 24|11@1+ (1,-1023) [-1023|1022] "Unit_Amper"  Vector__XXX
 SG_ EM1_Fehler_ElAntriebFreilauf_Anf : 35|1@1+ (1.0,0.0) [0.0|1] ""  Vector__XXX
 SG_ EM1_Abregelung_Temperatur : 36|1@1+ (1.0,0.0) [0.0|1] ""  Vector__XXX
 SG_ EM1_AnlernenElMotor_Anf : 43|1@1+ (1.0,0.0) [0.0|1] ""  Vector__XXX
 SG_ EM1_Moment_HVVerbraucher : 44|10@1+ (1,-511) [-511|511] "Unit_NewtoMeter"  Vector__XXX
 SG_ LE_Kuehlmittel_Sensor : 54|1@1+ (1.0,0.0) [0.0|1] ""  Vector__XXX
 SG_ EM1_Freigabe_Verfallsinfo_WFS : 55|1@1+ (1.0,0.0) [0.0|1] ""  Vector__XXX
 SG_ EM1_Parken_WFS_Status : 56|2@1+ (1.0,0.0) [0.0|3] ""  Vector__XXX
 SG_ EM1_HV_betriebsbereit : 58|1@1+ (1.0,0.0) [0.0|1] ""  Vector__XXX

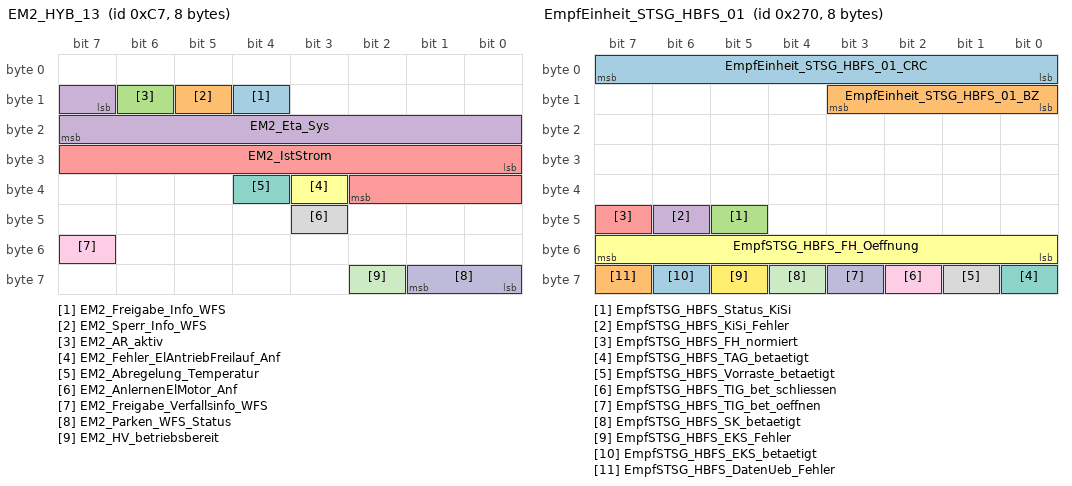
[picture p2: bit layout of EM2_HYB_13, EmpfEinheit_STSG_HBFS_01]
BO_ 199 EM2_HYB_13: 8 Gateway_Max
 SG_ EM2_Freigabe_Info_WFS : 12|1@1+ (1.0,0.0) [0.0|1] ""  Vector__XXX
 SG_ EM2_Sperr_Info_WFS : 13|1@1+ (1.0,0.0) [0.0|1] ""  BCM
 SG_ EM2_AR_aktiv : 14|1@1+ (1.0,0.0) [0.0|1] ""  Vector__XXX
 SG_ EM2_Eta_Sys : 15|9@1+ (0.2,0) [0.0|101.8] "Unit_PerCent"  Vector__XXX
 SG_ EM2_IstStrom : 24|11@1+ (1,-1023) [-1023|1022] "Unit_Amper"  Vector__XXX
 SG_ EM2_Fehler_ElAntriebFreilauf_Anf : 35|1@1+ (1.0,0.0) [0.0|1] ""  Vector__XXX
 SG_ EM2_Abregelung_Temperatur : 36|1@1+ (1.0,0.0) [0.0|1] ""  Vector__XXX
 SG_ EM2_AnlernenElMotor_Anf : 43|1@1+ (1.0,0.0) [0.0|1] ""  Vector__XXX
 SG_ EM2_Freigabe_Verfallsinfo_WFS : 55|1@1+ (1.0,0.0) [0.0|1] ""  Vector__XXX
 SG_ EM2_Parken_WFS_Status : 56|2@1+ (1.0,0.0) [0.0|3] ""  Vector__XXX
 SG_ EM2_HV_betriebsbereit : 58|1@1+ (1.0,0.0) [0.0|1] ""  Vector__XXX

BO_ 624 EmpfEinheit_STSG_HBFS_01: 8 TSGGen3_HBFS
 SG_ EmpfEinheit_STSG_HBFS_01_CRC : 0|8@1+ (1,0) [0|255] ""  Gateway_Max,TSGGen3_BFS,TSGGen3_FS
 SG_ EmpfEinheit_STSG_HBFS_01_BZ : 8|4@1+ (1,0) [0|15] ""  Gateway_Max,TSGGen3_BFS,TSGGen3_FS
 SG_ EmpfSTSG_HBFS_Status_KiSi : 45|1@1+ (1.0,0.0) [0.0|1] ""  Gateway_Max,TSGGen3_BFS,TSGGen3_FS
 SG_ EmpfSTSG_HBFS_KiSi_Fehler : 46|1@1+ (1.0,0.0) [0.0|1] ""  Gateway_Max,TSGGen3_BFS,TSGGen3_FS
 SG_ EmpfSTSG_HBFS_FH_normiert : 47|1@1+ (1.0,0.0) [0.0|1] ""  Gateway_Max
 SG_ EmpfSTSG_HBFS_FH_Oeffnung : 48|8@1+ (0.5,0) [0.0|100.0] "Unit_PerCent"  Gateway_Max
 SG_ EmpfSTSG_HBFS_TAG_betaetigt : 56|1@1+ (1.0,0.0) [0.0|1] ""  Gateway_Max
 SG_ EmpfSTSG_HBFS_Vorraste_betaetigt : 57|1@1+ (1.0,0.0) [0.0|1] ""  Gateway_Max
 SG_ EmpfSTSG_HBFS_TIG_bet_schliessen : 58|1@1+ (1.0,0.0) [0.0|1] ""  Gateway_Max
 SG_ EmpfSTSG_HBFS_TIG_bet_oeffnen : 59|1@1+ (1.0,0.0) [0.0|1] ""  BCM,Gateway_Max
 SG_ EmpfSTSG_HBFS_SK_betaetigt : 60|1@1+ (1.0,0.0) [0.0|1] ""  Gateway_Max
 SG_ EmpfSTSG_HBFS_EKS_Fehler : 61|1@1+ (1.0,0.0) [0.0|1] ""  Gateway_Max
 SG_ EmpfSTSG_HBFS_EKS_betaetigt : 62|1@1+ (1.0,0.0) [0.0|1] ""  Gateway_Max
 SG_ EmpfSTSG_HBFS_DatenUeb_Fehler : 63|1@1+ (1.0,0.0) [0.0|1] ""  Gateway_Max

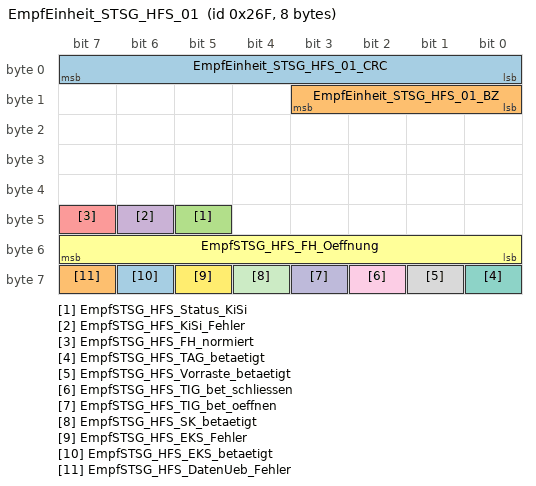
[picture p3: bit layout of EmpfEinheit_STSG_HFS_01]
BO_ 623 EmpfEinheit_STSG_HFS_01: 8 TSGGen3_HFS
 SG_ EmpfEinheit_STSG_HFS_01_CRC : 0|8@1+ (1,0) [0|255] ""  Gateway_Max,TSGGen3_BFS,TSGGen3_FS
 SG_ EmpfEinheit_STSG_HFS_01_BZ : 8|4@1+ (1,0) [0|15] ""  Gateway_Max,TSGGen3_BFS,TSGGen3_FS
 SG_ EmpfSTSG_HFS_Status_KiSi : 45|1@1+ (1.0,0.0) [0.0|1] ""  Gateway_Max,TSGGen3_BFS,TSGGen3_FS
 SG_ EmpfSTSG_HFS_KiSi_Fehler : 46|1@1+ (1.0,0.0) [0.0|1] ""  Gateway_Max,TSGGen3_BFS,TSGGen3_FS
 SG_ EmpfSTSG_HFS_FH_normiert : 47|1@1+ (1.0,0.0) [0.0|1] ""  Gateway_Max
 SG_ EmpfSTSG_HFS_FH_Oeffnung : 48|8@1+ (0.5,0) [0.0|100.0] "Unit_PerCent"  Gateway_Max
 SG_ EmpfSTSG_HFS_TAG_betaetigt : 56|1@1+ (1.0,0.0) [0.0|1] ""  Gateway_Max
 SG_ EmpfSTSG_HFS_Vorraste_betaetigt : 57|1@1+ (1.0,0.0) [0.0|1] ""  Gateway_Max
 SG_ EmpfSTSG_HFS_TIG_bet_schliessen : 58|1@1+ (1.0,0.0) [0.0|1] ""  Gateway_Max
 SG_ EmpfSTSG_HFS_TIG_bet_oeffnen : 59|1@1+ (1.0,0.0) [0.0|1] ""  BCM,Gateway_Max
 SG_ EmpfSTSG_HFS_SK_betaetigt : 60|1@1+ (1.0,0.0) [0.0|1] ""  Gateway_Max
 SG_ EmpfSTSG_HFS_EKS_Fehler : 61|1@1+ (1.0,0.0) [0.0|1] ""  Gateway_Max
 SG_ EmpfSTSG_HFS_EKS_betaetigt : 62|1@1+ (1.0,0.0) [0.0|1] ""  Gateway_Max
 SG_ EmpfSTSG_HFS_DatenUeb_Fehler : 63|1@1+ (1.0,0.0) [0.0|1] ""  Gateway_Max

BO_ 2589283970 Entfernung_02: 16 BCM
 SG_ DIST_DKmtg_Auth : 32|32@1+ (1,0) [0|4294967293] "Unit_Meter"  Gateway_Max
 SG_ SOK_Entfernung_02_Signatur : 64|64@1+ (1,0) [0|18446744073709551615] "Unit_None"  Gateway_Max

BO_ 2331595989 Entfernung_03: 8 BCM
 SG_ DIST_DKmtg : 32|32@1+ (1,0) [0|4294967293] "Unit_Meter"  Gateway_Max

BO_ 2589283751 Entfernungen_01: 8 BCM
 SG_ KBI_Kilometerstand_Extended : 6|24@1+ (1,0) [0|16777213] "Unit_KiloMeter"  Gateway_Max
 SG_ KBI_Kilometerstand_HiRes_meter : 30|34@1+ (1,0) [0|17179869183] "Unit_Meter"  Gateway_Max

BO_ 258 ESC_50: 48 Gateway_Max
 SG_ ESC_50_CRC : 0|8@1+ (1,0) [0|255] ""  BCM
 SG_ ESC_50_BZ : 8|4@1+ (1,0) [0|15] ""  BCM
 SG_ ESP_QBit_Gierrate : 12|1@1+ (1.0,0.0) [0.0|1] ""  Vector__XXX
 SG_ ESP_QBit_Laengsbeschl : 13|1@1+ (1.0,0.0) [0.0|1] ""  BCM
 SG_ ESP_QBit_Querb : 14|1@1+ (1.0,0.0) [0.0|1] ""  Vector__XXX
 SG_ ESP_Querbeschleunigung : 16|8@1+ (0.01,-1.27) [-1.27|1.27] "Unit_ForceOfGravi"  BCM,TSGGen3_BFS,TSGGen3_FS,TSGGen3_HBFS,TSGGen3_HFS
 SG_ ESP_Laengsbeschl : 24|10@1+ (0.03125,-16) [-16.00000|15.90625] "Unit_MeterPerSeconSquar"  BCM,TSGGen3_BFS,TSGGen3_FS,TSGGen3_HBFS,TSGGen3_HFS
 SG_ ESC_Motorstartverzoegerung : 34|1@1+ (1.0,0.0) [0.0|1] ""  Vector__XXX
 SG_ ESC_SeitenwindAssistent_Eingriff : 35|1@1+ (1.0,0.0) [0.0|1] ""  Vector__XXX
 SG_ ESP_Anschleppstart_Freigabe : 36|2@1+ (1.0,0.0) [0.0|3] ""  Vector__XXX
 SG_ ESC_Unterdruckmangel_erkannt : 38|1@1+ (1.0,0.0) [0.0|1] ""  Vector__XXX
 SG_ ESP_Gierrate : 40|14@1+ (0.01,0) [0.00|163.82] "Unit_DegreOfArcPerSecon"  TSGGen3_BFS,TSGGen3_FS,TSGGen3_HBFS,TSGGen3_HFS
 SG_ ESP_VZ_Gierrate : 54|1@1+ (1.0,0.0) [0.0|1] ""  Vector__XXX
 SG_ ESP_Notbremsanzeige : 55|1@1+ (1.0,0.0) [0.0|1] ""  BCM
 SG_ ESP_SpannungsAnf : 56|1@1+ (1.0,0.0) [0.0|1] ""  Vector__XXX
 SG_ ESP_PLA_Abbruch : 57|3@1+ (1.0,0.0) [0.0|7] ""  Vector__XXX
 SG_ ESP_Status_ESP_PLA : 60|4@1+ (1.0,0.0) [0.0|15] ""  Vector__XXX
 SG_ ESP_QBit_Bremsdruck : 76|1@1+ (1.0,0.0) [0.0|1] ""  Vector__XXX
 SG_ ESP_QBit_Fahrer_bremst : 77|1@1+ (1.0,0.0) [0.0|1] ""  BCM
 SG_ ESP_Schwelle_Unterdruck : 78|2@1+ (1.0,0.0) [0.0|3] ""  Vector__XXX
 SG_ ESP_Bremsdruck : 80|10@1+ (0.3,-30) [-30.0|276.6] "Unit_Bar"  Vector__XXX
 SG_ ESP_Fahrer_bremst : 90|1@1+ (1.0,0.0) [0.0|1] ""  BCM
 SG_ ESP_Verz_TSK_aktiv : 91|1@1+ (1.0,0.0) [0.0|1] ""  Vector__XXX
 SG_ ESP_Lenkeingriff_ADS : 92|1@1+ (1.0,0.0) [0.0|1] ""  Vector__XXX
 SG_ ESP_Konsistenz_TSK : 93|1@1+ (1.0,0.0) [0.0|1] ""  Vector__XXX
 SG_ ESP_Bremsruck_AWV2 : 94|1@1+ (1.0,0.0) [0.0|1] ""  Vector__XXX
 SG_ ESP_Konsistenz_AWV2 : 95|1@1+ (1.0,0.0) [0.0|1] ""  Vector__XXX
 SG_ ECD_Fehler : 96|1@1+ (1.0,0.0) [0.0|1] ""  Vector__XXX
 SG_ ECD_nicht_verfuegbar : 97|1@1+ (1.0,0.0) [0.0|1] ""  Vector__XXX
 SG_ ESP_Status_Bremsentemp : 98|1@1+ (1.0,0.0) [0.0|1] ""  Vector__XXX
 SG_ ESP_Autohold_Standby : 99|1@1+ (1.0,0.0) [0.0|1] ""  Vector__XXX
 SG_ ESP_HDC_Standby : 100|1@1+ (1.0,0.0) [0.0|1] ""  Vector__XXX
 SG_ ESP_HBA_aktiv : 101|1@1+ (1.0,0.0) [0.0|1] ""  Vector__XXX
 SG_ ESP_Prefill_ausgeloest : 102|1@1+ (1.0,0.0) [0.0|1] ""  Vector__XXX
 SG_ ESP_Rueckwaertsfahrt_erkannt : 103|1@1+ (1.0,0.0) [0.0|1] ""  Vector__XXX
 SG_ ESP_Status_Anfahrhilfe : 104|1@1+ (1.0,0.0) [0.0|1] ""  Vector__XXX
 SG_ ESP_HDC_aktiv : 105|1@1+ (1.0,0.0) [0.0|1] ""  Vector__XXX
 SG_ ESP_StartStopp_Info : 106|2@1+ (1.0,0.0) [0.0|3] ""  Vector__XXX
 SG_ ESP_Eingr_HL : 108|1@1+ (1.0,0.0) [0.0|1] ""  Vector__XXX
 SG_ ESP_Eingr_HR : 109|1@1+ (1.0,0.0) [0.0|1] ""  Vector__XXX
 SG_ ESP_Eingr_VL : 110|1@1+ (1.0,0.0) [0.0|1] ""  Vector__XXX
 SG_ ESP_Eingr_VR : 111|1@1+ (1.0,0.0) [0.0|1] ""  Vector__XXX
 SG_ ESP_BKV_Unterdruck : 112|8@1+ (4,0) [4|1012] "Unit_MilliBar"  Vector__XXX
 SG_ ESP_Autohold_aktiv : 120|1@1+ (1.0,0.0) [0.0|1] ""  Vector__XXX
 SG_ ESP_FStatus_Anfahrhilfe : 121|1@1+ (1.0,0.0) [0.0|1] ""  Vector__XXX
 SG_ ESP_Verz_EPB_aktiv : 122|1@1+ (1.0,0.0) [0.0|1] ""  Vector__XXX
 SG_ ECD_Bremslicht : 123|1@1+ (1.0,0.0) [0.0|1] ""  BCM
 SG_ ESP_Verzoeg_EPB_verf : 124|1@1+ (1.0,0.0) [0.0|1] ""  Vector__XXX
 SG_ ESP_Status_Bremsdruck : 125|1@1+ (1.0,0.0) [0.0|1] ""  Vector__XXX
 SG_ ESP_Anforderung_EPB : 126|2@1+ (1.0,0.0) [0.0|3] ""  Vector__XXX
 SG_ ESC_Fahrerradbremswunschmoment : 128|12@1+ (6,-2400) [-2400|22158] "Unit_NewtoMeter"  Vector__XXX
 SG_ ESP_ANB_CM_Rueckk_Umsetz : 140|1@1+ (1.0,0.0) [0.0|1] ""  Vector__XXX
 SG_ ESP_Konsistenz_ACC_Botschaft : 141|1@1+ (1.0,0.0) [0.0|1] ""  Vector__XXX
 SG_ ESP_Stillstandsphase_erschoepft : 142|1@1+ (1.0,0.0) [0.0|1] ""  Vector__XXX
 SG_ ESP_ZT_Rueckk_Umsetz : 143|1@1+ (1.0,0.0) [0.0|1] ""  Vector__XXX
 SG_ ESP_Tuerkontakt_Fahrertuer : 144|1@1+ (1.0,0.0) [0.0|1] ""  Vector__XXX
 SG_ ESP_Abrutschen_Stillstand : 146|1@1+ (1.0,0.0) [0.0|1] ""  Vector__XXX
 SG_ ESP_Fahrer_tritt_ZBR_Schw : 147|1@1+ (1.0,0.0) [0.0|1] ""  Vector__XXX
 SG_ ESP_Systemstatus_03 : 148|2@1+ (1.0,0.0) [0.0|3] ""  Vector__XXX
 SG_ ASR_Systemstatus : 150|2@1+ (1.0,0.0) [0.0|3] ""  Vector__XXX
 SG_ ESP_QBit_v_ref : 169|1@1+ (1.0,0.0) [0.0|1] ""  Vector__XXX
 SG_ ESP_v_ref_Fahrtrichtung : 170|2@1+ (1.0,0.0) [0.0|3] ""  Vector__XXX
 SG_ ESC_Bremsdruckgradient : 172|8@1+ (10,0) [0|2500] "Unit_BarPerSecon"  Vector__XXX
 SG_ ESP_v_ref : 180|12@1+ (0.125,0) [0.000|511.500] "Unit_KiloMeterPerHour"  Vector__XXX
 SG_ ESP_HBA_Empfindlichkeit : 220|3@1+ (1.0,0.0) [0.0|7] ""  Vector__XXX
 SG_ ESC_Hydr_Fkt_aktiv : 223|2@1+ (1.0,0.0) [0.0|3] ""  Vector__XXX
 SG_ ESC_QBit_Fahrerbremswunsch : 225|1@1+ (1.0,0.0) [0.0|1] ""  Vector__XXX
 SG_ ESC_Fahrerbremswunsch : 226|10@1+ (0.3,-30) [-30.0|276.6] "Unit_Bar"  Vector__XXX
 SG_ ESCGeneratorSollMoment : 236|12@1+ (3,-12279) [-12279|0] ""  Vector__XXX
 SG_ ESC_Raddruck_max : 248|8@1+ (1,0) [0|250] "Unit_Bar"  Vector__XXX
 SG_ EPB_QBit_Pedalweg_Kuppl : 269|1@1+ (1.0,0.0) [0.0|1] ""  Vector__XXX
 SG_ EPB_Freig_Verzoeg_Anf : 271|1@1+ (1.0,0.0) [0.0|1] ""  Vector__XXX
 SG_ EPB_Verzoeg_Anf : 272|8@1+ (0.048,-7.968) [-7.968|4.224] "Unit_MeterPerSeconSquar"  Vector__XXX
 SG_ EPB_Pedalweg_Kuppl : 288|8@1+ (0.4,0) [8.0|92.0] "Unit_PerCent"  Vector__XXX
 SG_ EPB_DAA_Randbed_erf : 305|1@1+ (1.0,0.0) [0.0|1] ""  Vector__XXX
 SG_ EPB_Fehlerstatus_02 : 306|2@1+ (1.0,0.0) [0.0|3] ""  Vector__XXX
 SG_ EPB_Schalterposition : 308|2@1+ (1.0,0.0) [0.0|3] ""  BCM
 SG_ EPB_QBit_Schalterpos : 310|1@1+ (1.0,0.0) [0.0|1] ""  BCM
 SG_ EPB_Spannkraft : 312|5@1+ (1,0) [0|29] "Unit_KiloNewto"  Vector__XXX
 SG_ EPB_Status_02 : 317|3@1+ (1.0,0.0) [0.0|7] ""  BCM
 SG_ EPB_Status : 320|2@1+ (1.0,0.0) [0.0|3] ""  BCM
 SG_ ESP_Status_Bremsentemp_02 : 322|2@1+ (1.0,0.0) [0.0|3] ""  Vector__XXX
 SG_ SOK_ESC_50_Signatur : 352|32@1+ (1,0) [0|4294967295] ""  Vector__XXX

BO_TX_BU_ 2463978735 :TSGGen3_BFS,TSGGen3_HBFS;
BO_TX_BU_ 2463978736 :TSGGen3_FS,TSGGen3_HFS;
CM_ BO_ 1603 "ab MQB mit 8 Byte";

CM_ SG_ 2463978735 ASW_Warnung_aktiv_HBFS "Abschaltung der Ambientefunktion Tür hinten der Beifahrerseite bei aktiver ASW Warnung an der Fahrertür";
CM_ SG_ 2463978735 BFS_Kopfstuetzen_hoch "Kopfstützen hoch (Wird bei Rechtslenker vom TSG HL gesendet)";
CM_ SG_ 2463978735 BFS_Kopfstuetzen_runter "Kopfstützen runter (Wird bei Rechtslenker vom TSG HL gesendet)";
CM_ SG_ 2463978735 BFS_Laengsverst_vor "Längsverstellung vor (Wird bei Rechtslenker vom TSG HL gesendet)";
CM_ SG_ 2463978735 BFS_Laengsverst_zurueck "Längsverstellung zurück (Wird bei Rechtslenker vom TSG HL gesendet)";
CM_ SG_ 2463978735 BFS_Lehnenkopf_vor "Lehnenkopf vor (Wird bei Rechtslenker vom TSG HL gesendet)";
CM_ SG_ 2463978735 BFS_Lehnenkopf_zurueck "Lehnenkopf zurück (Wird bei Rechtslenker vom TSG HL gesendet)";
CM_ SG_ 2463978735 BFS_Lehnenneigung_vor "Lehnenneigung vor (Wird bei Rechtslenker vom TSG HL gesendet)";
CM_ SG_ 2463978735 BFS_Lehnenneigung_zurueck "Lehnenneigung zurück (Wird bei Rechtslenker vom TSG HL gesendet)";
CM_ SG_ 2463978735 BFS_Sitzhoehe_hoch "Dient der Sitzhoehenverstellung des Beifahrersitzes aus dem Fond";
CM_ SG_ 2463978735 BFS_Sitzhoehe_runter "Dient der Sitzhoehenverstellung des Beifahrersitzes aus dem Fond";
CM_ SG_ 2463978735 DoorFunctions_HBFS_01_BZ "4bit Botschaftszähler, wird mit jeder Sendebotschaft inkrementiert";
CM_ SG_ 2463978735 DoorFunctions_HBFS_01_CRC "Für MLB:
Berechnung siehe Lastenheft 'Kommunikationsabsicherung für FlexRay und CAN'
Ab MQB und MLBevo:
Berechnung siehe Lastenheft 'End-to-End Kommunikationsabsicherung'

Endwerte siehe Begleitdokument 'S-PDU Kennungsfolgen'";
CM_ SG_ 2463978735 eTAB_HBFS_Oeffnen_Annaeh "Der Türgriffsensor hat eine Annaeherung zum Oeffnen erkannt.";
CM_ SG_ 2463978735 eTAB_HBFS_Oeffnen_Betaet "Der Türgriffsensor hat eine Betaetigung zum Oeffnen erkannt.";
CM_ SG_ 2463978735 eTAB_HBFS_Schliessen_Annaeh "Der Türgriffsensor hat eine Annaeherung zum Schliessen erkannt.";
CM_ SG_ 2463978735 eTAB_HBFS_Schliessen_Betaet "Der Türgriffsensor hat eine Betaetigung zum Schliessen erkannt.";
CM_ SG_ 2463978735 HBFS_ASW_HMI_defekt "HMI Status der Funktion AusstiegsWarnung (ASW), HMI wird durch das TSG angesteuert.";
CM_ SG_ 2463978735 HBFS_ASW_Warnton "erzeugt ein Warnton bei AS Warnung";
CM_ SG_ 2463978735 HBFS_ASW_Warnung_Aussenlicht "zeigt in den Heckleuchte ein Symbol an";
CM_ SG_ 2463978735 HBFS_FH_Bew_hoch "HBFS Fenster bewegt sich in Richtung hoch";
CM_ SG_ 2463978735 HBFS_FH_Bew_tief "HBFS Fenster bewegt sich in Richtung tief";
CM_ SG_ 2463978735 HBFS_FH_Block "Fensterscheibe befindet sich im mechanischen Block (oben oder unten)";
CM_ SG_ 2463978735 HBFS_FH_Fang "Fangbereich ist 4mm von oberer Lippendichtung";
CM_ SG_ 2463978735 HBFS_FH_normiert "Die Position der Fensterheberscheibe ist bekannt.";
CM_ SG_ 2463978735 HBFS_FH_Oeffnung "Gibt den Fensteröffnungswert in % an.";
CM_ SG_ 2463978735 HBFS_FH_S_AutoHoch "Betaetigung FH Schalter auto tief ";
CM_ SG_ 2463978735 HBFS_FH_S_AutoTief "Betaetigung FH Schalter auto hoch";
CM_ SG_ 2463978735 HBFS_FH_S_HFS_AutoHoch "Automatisches Hochfahren der Seitenscheibe HFS";
CM_ SG_ 2463978735 HBFS_FH_S_HFS_AutoTief "Automatisches Absenken der Seitenscheibe HFS";
CM_ SG_ 2463978735 HBFS_FH_S_HFS_ManHoch "Manuelles Hochfahren der Seitenscheibe HFS";
CM_ SG_ 2463978735 HBFS_FH_S_HFS_ManTief "Manuelles Absenken der Seitenscheibe HFS";
CM_ SG_ 2463978735 HBFS_FH_S_ManHoch "Betaetigung FH Schalter man hoch ";
CM_ SG_ 2463978735 HBFS_FH_S_ManTief "Betaetigung FH Schalter man tief";
CM_ SG_ 2463978735 HBFS_FH_Thermo "gibt an ob Fensterheber im Thermoschutz ist";
CM_ SG_ 2463978735 HBFS_gesafet "HBFS Tuer gesafet.
Im Zustand Safe wird auch das Signal HBFS_verriegelt = 1 gesendet.";
CM_ SG_ 2463978735 HBFS_Heckrollotaster_betaetigt "Verfahren des Heckrollos in Richtung Hoch

Bei Einfachtaster wird Bit als Togglebit verwendet (Heckrollo hoch, tief)";
CM_ SG_ 2463978735 HBFS_KiSi_Fehler "Status der Kindersicherung unplausibel";
CM_ SG_ 2463978735 HBFS_Lock_Taster "Betaetigung Lock-Taster";
CM_ SG_ 2463978735 HBFS_Lock_Taster_inv "Lock Taster nicht betätigt";
CM_ SG_ 2463978735 HBFS_MRollo_Schalter "  | MRollo2
-----------------------------
0 | nicht_betaetigt
1 | (m) Zu
2 | (a) Zu
3 | (m) Auf
4 | (a) Auf
5 | Schalter nicht verfuegbar
6 | Init
7 | Fehlerfall";
CM_ SG_ 2463978735 HBFS_Oben_Block_erw "Fensterheber in Blockerwartung oben";
CM_ SG_ 2463978735 HBFS_Push_Tuergriff "Push zum Ausfahren der Flush-Tuergriffe";
CM_ SG_ 2463978735 HBFS_SAD_Schalter "  |   Ausstelldach MD3
-----------------------------
0 | nicht_betaetigt
1 |
2 |
3 |
4 |
5 | (m) Auf
6 | (a) Auf
7 | (m) Zu
8 | (a) Zu
13| Schalter nicht verfuegbar
14| Init
15| Fehlerfall";
CM_ SG_ 2463978735 HBFS_Schloss_oeffnen_Ansteuerung "Hier wird die Ansteuerung der  Schlossoeffnung angezeigt. Bei mechanischen Schloessern wird Init gesendet.";
CM_ SG_ 2463978735 HBFS_Schloss_Status_OeH_Motor "Schossstatus 
Bei Schloss mit frueherem Stand als eSchloss2.0 wird init geschickt";
CM_ SG_ 2463978735 HBFS_Seitenrollo_tief "Seitenrollo in Bewegung Richtung tief";
CM_ SG_ 2463978735 HBFS_SK_betaetigt "Status der Sperrklinke";
CM_ SG_ 2463978735 HBFS_Sperrklinke "Vorraste für Schloß

zwischen Vor- und Hauptraste Signal kurz auf 1, danach wieder auf 0 wenn Tür in Hauptraste (Tür ist sicher zu wenn Sperrklinke und Türkontakt auf 0 sind)";
CM_ SG_ 2463978735 HBFS_Status_eTAG "Status des elektrischen Tueraussengriffes Tuer Beifahrerseite hinten";
CM_ SG_ 2463978735 HBFS_Status_eTAG_ext "HBFS Status eTAG erweitert um den Wert 'Griff verfaehrt'";
CM_ SG_ 2463978735 HBFS_Status_KiSi "Status Kindersicherung HBFS
";
CM_ SG_ 2463978735 HBFS_Status_KiSi_inv "Inverser Status der elektrischen Kindersicherung Beifahrerseite hinten";
CM_ SG_ 2463978735 HBFS_TAG_betaetigt "Betaetigung Türaussengriff";
CM_ SG_ 2463978735 HBFS_TCR_Mode_aktiv "Signal zeigt eine aktive mechanische Redundanz am Türschloss an.";
CM_ SG_ 2463978735 HBFS_TIG_betaetigt "Betaetigung Tuerinnengriff";
CM_ SG_ 2463978735 HBFS_TIG_betaetigt_oeffnen "Türinnenbetätigung, Taster Tür öffnen.";
CM_ SG_ 2463978735 HBFS_TIG_betaetigt_schliessen "Türinnenbetätigung, Taster Tür schließen.";
CM_ SG_ 2463978735 HBFS_Tuer_geoeffnet "HBFS Tuer geoeffnet";
CM_ SG_ 2463978735 HBFS_Tuer_Status "Türstatus mit Fehler und Initwert";
CM_ SG_ 2463978735 HBFS_Tuer_Status_QBit "Dieses Bit gibt die Zuverlässigkeit des Türkontakts an. Ein auf dieses Bit folgender Fehlereintrag ist mit dem Sender des Bits abzustimmen (gültig ab PPE).";
CM_ SG_ 2463978735 HBFS_Tueroeffnen_Warnung "Bit wird gesetzt, wenn Tür während der Fahrt geoeffnet werden soll.";
CM_ SG_ 2463978735 HBFS_Tuerschloss_defekt "Das hintere Tuerschloss auf der Beifahrerseite ist nicht mehr funktionsfähig.";
CM_ SG_ 2463978735 HBFS_UEKB_aktiviert "Überschutzbegrenzungskraft bei Reversieren";
CM_ SG_ 2463978735 HBFS_Unlock_Taster "Betaetigung Unlock Taster";
CM_ SG_ 2463978735 HBFS_Unten_Block_erw "Fensterheber in Blockerwartung unten";
CM_ SG_ 2463978735 HBFS_verriegelt "Verriegelungsstatus Tür";
CM_ SG_ 2463978735 HBFS_Vorraste_betaetigt "Status der Vorraste";
CM_ SG_ 2463978735 HBFS_Zuziehhilfe_aktiv "Zuziehhilfe aktiv";
CM_ SG_ 2463978735 MTHBF_ein "Wird bei Rechtslenker vom TSG HL gesendet";
CM_ SG_ 2463978735 MTHBFS_M_Taste "Betätigung M-Taste HBFS";
CM_ SG_ 2463978735 MTHBFS_Pos1 "Betätigung Postionstaste 1 HBFS";
CM_ SG_ 2463978735 MTHBFS_Pos2 "Betätigung Postionstaste 2 HBFS
";
CM_ SG_ 2463978735 MTHBFS_Pos3 "Betätigung Postionstaste 3 HBFS";
CM_ SG_ 2463978735 SOK_Doorfunctions_HBFS_01_Sig001 "Signatur im Rahmen des SOK.

Geschützte Funktion:	Türfunktionen Hinten Beifahrerseite
Geschützte Signale:  	";
CM_ SG_ 2463978735 SSA_HBFS_eKisi_Fehler "SmartSensorActor:
Rückmeldung des Fehlerzustandes der elektrischen Kindersicherung auf der Beifahrerseite hinten";
CM_ SG_ 2463978735 SSA_HBFS_eKisi_Status "SmartSensorActor:
Rückmeldung des Status der elektrischen Kindersicherung auf der Beifahrerseite hinten";
CM_ SG_ 2463978735 SSA_HBFT_Amb_Bel_Fehler "SmartSensorActor:
Rückmeldung des Fehlerzustand der Ambiente Beleuchtung";
CM_ SG_ 2463978735 SSA_HBFT_Amb_Bel_Status "SmartSensorActor:
Rückmeldung des Status der Ambiente Beleuchtung";
CM_ SG_ 2463978735 SSA_HBFT_ASW_Fehler "SmartSensorActor:
Rückmeldung des Fehlerzustand des Ausstiegswarners";
CM_ SG_ 2463978735 SSA_HBFT_ASW_Status "SmartSensorActor:
Rückmeldung des Status der ASW Anzyeige.";
CM_ SG_ 2463978735 SSA_HBFT_el_Tuerantrieb_Fehler "SmartSensorActor:
Rückmeldung des Fehlerzustand des el. Tuerantriebs";
CM_ SG_ 2463978735 SSA_HBFT_el_Tuerantrieb_Status "SmartSensorActor:
Rückmeldung des Status des el. Tuerantriebes";
CM_ SG_ 2463978735 SSA_HBFT_FH_Bewegungsrichutng "SmartSensorActor:
Rückmeldung der Bewegungsrichtung der Seitenscheibe";
CM_ SG_ 2463978735 SSA_HBFT_FH_Fehler "SmartSensorActor:
Rückmeldung des Fehlerzustandes der Fensterheberfunktion";
CM_ SG_ 2463978735 SSA_HBFT_FH_Normierung "SmartSensorActor:
Rückmeldung des Normierungszustandes des Fensterhebers";
CM_ SG_ 2463978735 SSA_HBFT_FH_Oeffnungsweite "SmartSensorActor:
Rückmeldung der Öffnungsweite des Fensterhebers (0% geschlossen, 100% geöffnet)
Angabe gilt nur bei normierten Fensterheber";
CM_ SG_ 2463978735 SSA_HBFT_FH_Thermoschutz "SmartSensorActor:
Rückmeldung Status Thermoschutz";
CM_ SG_ 2463978735 SSA_HBFT_SSR_Fehler "SmartSensorActor:
Rückmeldung des Fehlerzustand des Seitenscheibenrollos";
CM_ SG_ 2463978735 SSA_HBFT_SSR_Status "SmartSensorActor:
Rueckmeldung des Status des Seitenscheibenrollos";
CM_ SG_ 2463978735 SSA_HBFT_Tuerverschluss_Fehler "SmartSensorActor:
Fehlerzustand der hinteren Beifahrertür";
CM_ SG_ 2463978735 SSA_HBFT_Tuerverschluss_Status "SmartSensorActor:
Türstatus der hinteren Beifahrertür (geschlossen, geöffnet)";
CM_ SG_ 2463978735 SSA_HBFT_ZV_Fehler "SmartSensorActor:
Rückmeldung des Fehlerzustandes des Türschlosses der hinteren Beifahrertür";
CM_ SG_ 2463978735 SSA_HBFT_ZZH_Fehler "SmartSensorActor:
Rückmeldung des Fehlerzustandes des ZZH Systems";
CM_ SG_ 2463978735 SSA_HBFT_ZZH_Status "SmartSensorActor:
Status des ZZH Motors";
CM_ SG_ 2463978735 SSR_HBFS_Pos_Unten "Signal für die 'Global Close'. Über dieses Bit wissen die anderen TSGs, ob der SSR oder der FH verfahren werden darf.";
CM_ SG_ 2463978735 TSG_FlHz_HBFS_FnAbbruchHzKreis_A "Flächenheizung: Status";
CM_ SG_ 2463978735 TSG_FlHz_HBFS_FnAbbruchHzKreis_B "Flächenheizung: Status";
CM_ SG_ 2463978735 TSG_FlHz_HBFS_NTC_A "Flächenheizung: Temperatur und Fehlerwert des Heizaktors";
CM_ SG_ 2463978735 TSG_FlHz_HBFS_NTC_B "Flächenheizung: Temperatur und Fehlerwert des Heizaktors";
CM_ SG_ 2463978735 TSG_FlHz_HBFS_Unterbrech_HzK_A "Flächenheizung: Unterbrechungsstatus Heizkreis";
CM_ SG_ 2463978735 TSG_FlHz_HBFS_Unterbrech_HzK_B "Flächenheizung: Unterbrechungsstatus Heizkreis";

CM_ SG_ 2463978736 ASW_Warnung_aktiv_HFS "Abschaltung der Ambientefunktion Tür hinten der Fahrerseite bei aktiver ASW Warnung an der Fahrertür";
CM_ SG_ 2463978736 DoorFunctions_HFS_01_BZ "4bit Botschaftszähler, wird mit jeder Sendebotschaft inkrementiert";
CM_ SG_ 2463978736 DoorFunctions_HFS_01_CRC "Für MLB:
Berechnung siehe Lastenheft 'Kommunikationsabsicherung für FlexRay und CAN'
Ab MQB und MLBevo:
Berechnung siehe Lastenheft 'End-to-End Kommunikationsabsicherung'

Endwerte siehe Begleitdokument 'S-PDU Kennungsfolgen'";
CM_ SG_ 2463978736 eTAB_HFS_Oeffnen_Annaeh "Der Türgriffsensor hat eine Annaeherung zum Oeffnen erkannt.";
CM_ SG_ 2463978736 eTAB_HFS_Oeffnen_Betaet "Der Türgriffsensor hat eine Betaetigung zum Oeffnen erkannt.";
CM_ SG_ 2463978736 eTAB_HFS_Schliessen_Annaeh "Der Türgriffsensor hat eine Annaeherung zum Schliessen erkannt.";
CM_ SG_ 2463978736 eTAB_HFS_Schliessen_Betaet "Der Türgriffsensor hat eine Betaetigung zum Schliessen erkannt.";
CM_ SG_ 2463978736 HFS_ASW_HMI_defekt "HMI Status der Funktion AusstiegsWarnung (ASW), HMI wird durch das TSG angesteuert.";
CM_ SG_ 2463978736 HFS_ASW_Warnton "erzeugt ein Warnton bei AS Warnung";
CM_ SG_ 2463978736 HFS_ASW_Warnung_Aussenlicht "zeigt in den Heckleuchte ein Symbol an";
CM_ SG_ 2463978736 HFS_FH_Bew_hoch "HFS Fenster bewegt sich in Richtung hoch";
CM_ SG_ 2463978736 HFS_FH_Bew_tief "HFS Fenster bewegt sich in Richtung tief";
CM_ SG_ 2463978736 HFS_FH_Block "Fensterscheibe befindet sich im mechanischen Block (oben oder unten)";
CM_ SG_ 2463978736 HFS_FH_Fang "Fangbereich ist 4mm von oberer Lippendichtung";
CM_ SG_ 2463978736 HFS_FH_normiert "Die Position der Fensterheberscheibe ist bekannt.";
CM_ SG_ 2463978736 HFS_FH_Oeffnung "Gibt den Fensteröffnungswert in % an.";
CM_ SG_ 2463978736 HFS_FH_S_AutoHoch "Betaetigung FH Schalter auto hoch";
CM_ SG_ 2463978736 HFS_FH_S_AutoTief "Betaetigung FH Schalter auto tief ";
CM_ SG_ 2463978736 HFS_FH_S_HBFS_AutoHoch "Automatisches Hochfahren der Seitenscheibe HBFS";
CM_ SG_ 2463978736 HFS_FH_S_HBFS_AutoTief "Automatisches Absenken der Seitenscheibe HBFS";
CM_ SG_ 2463978736 HFS_FH_S_HBFS_ManHoch "Manuelles Hochfahren der Seitenscheibe HBFS";
CM_ SG_ 2463978736 HFS_FH_S_HBFS_ManTief "Manuelles Absenken der Seitenscheibe HBFS";
CM_ SG_ 2463978736 HFS_FH_S_ManHoch "Betaetigung FH Schalter man hoch ";
CM_ SG_ 2463978736 HFS_FH_S_ManTief "Betaetigung FH Schalter man tief";
CM_ SG_ 2463978736 HFS_FH_Thermo "gibt an ob Fensterheber im Thermoschutz ist";
CM_ SG_ 2463978736 HFS_gesafet "HFS Tuer gesafet.
Im Zustand Safe wird auch das Signal HFS_verriegelt = 1 gesendet.";
CM_ SG_ 2463978736 HFS_Heckrollotaster_betaetigt "Verfahren des Heckrollos in Richtung Hoch

Bei Einfachtaster wird Bit als Togglebit verwendet (Heckrollo hoch, tief)";
CM_ SG_ 2463978736 HFS_KiSi_Fehler "Status der Kindersicherung unplausibel";
CM_ SG_ 2463978736 HFS_Lock_Taster "Betätigung Lock-Taster";
CM_ SG_ 2463978736 HFS_Lock_Taster_inv "Lock Taster nicht betätigt";
CM_ SG_ 2463978736 HFS_MRollo_Schalter "  | MRollo2
-----------------------------
0 | nicht_betaetigt
1 | (m) Zu
2 | (a) Zu
3 | (m) Auf
4 | (a) Auf
5 | Schalter nicht verfuegbar
6 | Init
7 | Fehlerfall";
CM_ SG_ 2463978736 HFS_Oben_Block_erw "Fensterheber in Blockerwartung oben";
CM_ SG_ 2463978736 HFS_Push_Tuergriff "Push zum Ausfahren der Flush-Tuergriffe";
CM_ SG_ 2463978736 HFS_SAD_Schalter "  |   Ausstelldach MD3
-----------------------------
0 | nicht_betaetigt
1 |
2 |
3 |
4 |
5 | (m) Auf
6 | (a) Auf
7 | (m) Zu
8 | (a) Zu
13| Schalter nicht verfuegbar
14| Init
15| Fehlerfall";
CM_ SG_ 2463978736 HFS_Schloss_oeffnen_Ansteuerung "Hier wird die Ansteuerung der  Schlossoeffnung angezeigt. Bei mechanischen Schloessern wird Init gesendet.";
CM_ SG_ 2463978736 HFS_Schloss_Status_OeH_Motor "Schossstatus 
Bei Schloss mit frueherem Stand als eSchloss2.0 wird init geschickt";
CM_ SG_ 2463978736 HFS_Seitenrollo_hoch "Seitenrollo in Bewegung Richtung hoch";
CM_ SG_ 2463978736 HFS_Seitenrollo_tief "Seitenrollo in Bewegung Richtung tief";
CM_ SG_ 2463978736 HFS_SK_betaetigt "Status der Sperrklinke";
CM_ SG_ 2463978736 HFS_Sperrklinke "Vorraste für Schloß

zwischen Vor- und Hauptraste Signal kurz auf 1, danach wieder auf 0 wenn Tür in Hauptraste (Tür ist sicher zu wenn Sperrklinke und Türkontakt auf 0 sind)";
CM_ SG_ 2463978736 HFS_Status_eTAG "Status des elektrischen Tueraussengriffes Tuer Fahrerseite hinten";
CM_ SG_ 2463978736 HFS_Status_eTAG_ext "HFS Status eTAG erweitert um den Wert 'Griff verfaehrt'";
CM_ SG_ 2463978736 HFS_Status_KiSi "Status Kindersicherung hinten Fahrerseite";
CM_ SG_ 2463978736 HFS_TAG_betaetigt "Betaetigung Türaussengriff";
CM_ SG_ 2463978736 HFS_TCR_Mode_aktiv "Signal zeigt eine aktive mechanische Redundanz am Türschloss an.";
CM_ SG_ 2463978736 HFS_TIG_betaetigt "Betaetigung Türinnengriff";
CM_ SG_ 2463978736 HFS_TIG_betaetigt_oeffnen "Türinnenbetätigung, Taster Tür öffnen.";
CM_ SG_ 2463978736 HFS_TIG_betaetigt_schliessen "Türinnenbetätigung, Taster Tür schließen.";
CM_ SG_ 2463978736 HFS_Tuer_geoeffnet "HFS Tuer geoeffnet";
CM_ SG_ 2463978736 HFS_Tuer_Status "Türstatus mit Fehler und Initwert";
CM_ SG_ 2463978736 HFS_Tuer_Status_QBit "Dieses Bit gibt die Zuverlässigkeit des Türkontakts an. Ein auf dieses Bit folgender Fehlereintrag ist mit dem Sender des Bits abzustimmen (gültig ab PPE).";
CM_ SG_ 2463978736 HFS_Tueroeffnen_Warnung "Bit wird gesetzt, wenn Tür während der Fahrt geoeffnet werden soll.";
CM_ SG_ 2463978736 HFS_Tuerschloss_defekt "Das hintere Tuerschloss auf der Fahrerseite ist nicht mehr funktionsfähig.";
CM_ SG_ 2463978736 HFS_UEKB_aktiviert "Überschutzbegrenzungskraft bei Reversieren";
CM_ SG_ 2463978736 HFS_Unlock_Taster "Betaetigung Unlock Taster";
CM_ SG_ 2463978736 HFS_Unten_Block_erw "Fensterheber in Blockerwartung unten";
CM_ SG_ 2463978736 HFS_verriegelt "HFS Tuer verriegelt";
CM_ SG_ 2463978736 HFS_Vorraste_betaetigt "Status der Vorraste";
CM_ SG_ 2463978736 HFS_Zuziehhilfe_aktiv "Zuziehhilfe aktiv";
CM_ SG_ 2463978736 MTHFS_M_Taste "Betätigung M-Taste HFS";
CM_ SG_ 2463978736 MTHFS_Pos1 "Betätigung Postionstaste 1 HFS";
CM_ SG_ 2463978736 MTHFS_Pos2 "Betätigung Postionstaste 2 HFS
";
CM_ SG_ 2463978736 MTHFS_Pos3 "Betätigung Postionstaste 3 HFS";
CM_ SG_ 2463978736 SOK_Doorfunctions_HFS_01_Sign002 "Signatur im Rahmen des SOK.

Geschützte Funktion:	Türfunktionen Hinten Fahrerseite
Geschützte Signale:  	";
CM_ SG_ 2463978736 SSA_HFS_eKisi_Fehler "SmartSensorActor:
Rückmeldung des Fehlerzustandes der elektrischen Kindersicherung auf der Fahrerseite hinten";
CM_ SG_ 2463978736 SSA_HFS_eKisi_Status "SmartSensorActor:
Rückmeldung des Status der elektrischen Kindersicherung auf der Fahrerseite hinten";
CM_ SG_ 2463978736 SSA_HFT_Amb_Bel_Fehler "SmartSensorActor:
Rückmeldung des Fehlerzustand der Ambiente Beleuchtung";
CM_ SG_ 2463978736 SSA_HFT_Amb_Bel_Status "SmartSensorActor:
Rückmeldung des Status der Ambiente Beleuchtung";
CM_ SG_ 2463978736 SSA_HFT_ASW_Fehler "SmartSensorActor:
Rückmeldung des Fehlerzustand des Ausstiegswarners";
CM_ SG_ 2463978736 SSA_HFT_ASW_Status "SmartSensorActor:
Rückmeldung des Status der ASW Anzyeige.";
CM_ SG_ 2463978736 SSA_HFT_el_Tuerantrieb_Fehler "SmartSensorActor:
Rückmeldung des Fehlerzustand des el. Tuerantriebs";
CM_ SG_ 2463978736 SSA_HFT_el_Tuerantrieb_Status "SmartSensorActor:
Rückmeldung des Status des el. Tuerantriebes";
CM_ SG_ 2463978736 SSA_HFT_FH_Bewegungsrichutng "SmartSensorActor:
Rückmeldung der Bewegungsrichtung der Seitenscheibe";
CM_ SG_ 2463978736 SSA_HFT_FH_Fehler "SmartSensorActor:
Rückmeldung des Fehlerzustandes der Fensterheberfunktion";
CM_ SG_ 2463978736 SSA_HFT_FH_Normierung "SmartSensorActor:
Rückmeldung des Normierungszustandes des Fensterhebers";
CM_ SG_ 2463978736 SSA_HFT_FH_Thermoschutz "SmartSensorActor:
Rückmeldung Status Thermoschutz";
CM_ SG_ 2463978736 SSA_HFT_SSR_Fehler "SmartSensorActor:
Rückmeldung des Fehlerzustand des Seitenscheibenrollos";
CM_ SG_ 2463978736 SSA_HFT_SSR_Status "SmartSensorActor:
Rueckmeldung des Status des Seitenscheibenrollos";
CM_ SG_ 2463978736 SSA_HFT_Tuerverschluss_Fehler "SmartSensorActor:
Fehlerzustand der hinteren Fahrertür";
CM_ SG_ 2463978736 SSA_HFT_Tuerverschluss_Status "SmartSensorActor:
Türstatus der hinteren Fahrertür (geschlossen, geöffnet)";
CM_ SG_ 2463978736 SSA_HFT_ZV_Ansteuern "SmartSensorActor:
Kommando zur Ansteuerung des Türschlosses der hinteren Fahrertür";
CM_ SG_ 2463978736 SSA_HFT_ZV_Fehler "SmartSensorActor:
Rückmeldung des Fehlerzustandes des Türschlosses der hinteren Fahrertür";
CM_ SG_ 2463978736 SSA_HFT_ZV_Status "SmartSensorActor:
Zustand des Türschlosses der  hinteren Fahrertür";
CM_ SG_ 2463978736 SSA_HFT_ZZH_Fehler "SmartSensorActor:
Rückmeldung des Fehlerzustandes des ZZH Systems";
CM_ SG_ 2463978736 SSA_HFT_ZZH_Status "SmartSensorActor:
Status des ZZH Motors";
CM_ SG_ 2463978736 SSR_HFS_Pos_Unten "Signal für die 'Global Close'. Über dieses Bit wissen die anderen TSGs, ob der SSR oder der FH verfahren werden darf.";
CM_ SG_ 2463978736 TSG_FlHz_HFS_FnAbbruchHzKreis_A "Flächenheizung: Status";
CM_ SG_ 2463978736 TSG_FlHz_HFS_FnAbbruchHzKreis_B "Flächenheizung: Status";
CM_ SG_ 2463978736 TSG_FlHz_HFS_NTC_A "Flächenheizung: Temperatur und Fehlerwert des Heizaktors";
CM_ SG_ 2463978736 TSG_FlHz_HFS_NTC_B "Flächenheizung: Temperatur und Fehlerwert des Heizaktors";
CM_ SG_ 2463978736 TSG_FlHz_HFS_Unterbrech_HzK_A "Flächenheizung: Unterbrechungsstatus Heizkreis";

CM_ SG_ 496 ACF_Lampe_Hands_Off "Anzeige, ob der Fahrer die Hände am Lenkrad hat.";
CM_ SG_ 496 EA_02_BZ "Botschaftszähler";
CM_ SG_ 496 EA_02_CRC "Für MLB:
'Berechnung siehe Lastenheft 'Kommunikationsabsicherung für Flexray und CAN''

Ab MQB und MLBevo:
'Berechnung siehe Lastenheft 'End-to-End Kommunikationsabsicherung'

Endwerte siehe Begleitdokument 'S-PDU Kennungsfolge'";
CM_ SG_ 496 EA_Blinken "Emergency Assist Anforderung Blinker";
CM_ SG_ 496 EA_Bremslichtblinken "Die Funktion Emergency Alert fordert ein Blinken der Bremsleuchten an.";
CM_ SG_ 496 EA_eCall_Anf "Emergency Assist Anforderung eCall";
CM_ SG_ 496 EA_Fahrzeughupe_Anf "Emergency Assist Anforderung Fahrzeughupe";
CM_ SG_ 496 EA_Infotainment_Anf "Emergency Assist Anforderung Absenkung Infotainment-Funktionen";
CM_ SG_ 496 EA_Innenraumlicht_Anf "Anforderung Innenraumbeleuchtung durch den Emergency Assist";
CM_ SG_ 496 EA_Status_HMI "Anzeige Emergency Assist-Statusleuchte im Fahrerinformationsdisplay";
CM_ SG_ 496 EA_Texte "Anzeige der EA Texte";
CM_ SG_ 496 EA_Tueren_Anf "Emergency Assist Anforderung Türen entriegeln";
CM_ SG_ 496 EA_Warnlevel "Kritikalität der Funktion Emergency Assist";
CM_ SG_ 496 STP_Primaeranz "Primäranzeige des Staupiloten";
CM_ SG_ 496 zFAS_Warnblinken "Anforderung Warnblinken durch zFAS Funktionen.";

CM_ SG_ 1603 KBI_Einheit_Datum "Anzeigevariante des Datums";
CM_ SG_ 1603 KBI_Einheit_Druck "Einheit des Druckes";
CM_ SG_ 1603 KBI_Einheit_Masse "Einheit der Masse (Verwendung z.B. ASTA)";
CM_ SG_ 1603 KBI_Einheit_Sprache "Siehe BAP-Datenfestlegung UnitMaster";
CM_ SG_ 1603 KBI_Einheit_Streckenanz "Einheit der Streckenanzeige";
CM_ SG_ 1603 KBI_Einheit_Tacho "Information, ob es sich um Meilen- oder Kmh-Kombi handelt, Einheit des Tachos entspricht dem Zifferblatt, Grösse ist nicht veränderlich";
CM_ SG_ 1603 KBI_Einheit_Temp "Einheit der Temperatur";
CM_ SG_ 1603 KBI_Einheit_Uhrzeit "Anzeigevariante der Uhrzeit";
CM_ SG_ 1603 KBI_Einheit_Verbrauch "Einheit der Verbrauchs";
CM_ SG_ 1603 KBI_Einheit_Verbrauch_elektr "Einheit elektrischer Verbrauch";
CM_ SG_ 1603 KBI_Einheit_Verbrauch_Gas "Unterscheidung zwischen M3/h und kg/h für Komfortverbrauchsberechnung.";
CM_ SG_ 1603 KBI_Einheit_Volumen "Einheit des Volumens";
CM_ SG_ 1603 KBI_MFA_v_Einheit_02 "Einheit der Geschwindigkeit, die vom Fahrer im Car-Menü gewählt wurde. Veränderliche Grösse, im Gegensatz zur Einheit des Tachokranzes.

Redundant in der Einheiten_01 Botschaft definiert, um Konsistenz zur BAP-Festlegung zu haben.";

CM_ SG_ 1622 ELV_01_BZ "4bit Botschaftszaehler, wird mit jeder Sendebotschaft inkrementiert";
CM_ SG_ 1622 ELV_01_CRC "Ab MQB und MLBevo:
'Berechnung siehe Lastenheft 'End-to-End Kommunikationsabsicherung''

Endwerte siehe Begleitdokument 'S-PDU Kennungsfolgen'";
CM_ SG_ 1622 ELV_01_Sendestatus "Zeigt an, ob die ELV für einen begrenzten Zeitraum mit verkürzter Zykluszeit (50ms) sendet. Das ist bis zur KL15ein notwendig, um eine Motorstartverzögerung zu vermeiden.";
CM_ SG_ 1622 ELV_Abbruch_Anf_Klemmenfreigabe "Klemmenanforderung des Kessy-SG wird von der ELV verworfen und muss vom Kessy zurückgenommen werden.";
CM_ SG_ 1622 ELV_Anf_Klemme_15 "Signal wird zur Plausibilisierung parrallel zum Klemmensignal auf dem CAN übertragen
Anforderung Klemme_15";
CM_ SG_ 1622 ELV_Anf_Klemme_50 "Signal wird zur Plausibilisierung parrallel zum Klemmensignal auf dem CAN übertragen
Anforderung Klemme_50";
CM_ SG_ 1622 ELV_Anf_Klemme_S "Signal wird zur Plausibilisierung parallel zum Klemmensignal auf dem CAN übertragen
Anforderung Klemme_S";
CM_ SG_ 1622 ELV_Anlernmodus "Im Anlernmodus (1) ist zum Einschalten der KLS u.KL15 keine Authentifizierung der WFS notwendig. KL50 ist nicht einschaltbar.
Auslieferungszustand ist (1)";
CM_ SG_ 1622 ELV_Entriegelt "ELV im Zustand entriegelt
";
CM_ SG_ 1622 ELV_Klemmenfreigabe "Freigabe/Quittierung der ELV für das Einschalten der Klemme 15 und Klemme S";
CM_ SG_ 1622 ELV_Lebenszustand "Auslieferungszustand ist (0)
Lebenszustand";
CM_ SG_ 1622 ELV_LED_Gelb "Warnlampe Gelb";
CM_ SG_ 1622 ELV_LED_Rot "Warnlampe Rot";
CM_ SG_ 1622 ELV_P_verriegelt "Position P-verriegelt vom Gangwahlhebel";
CM_ SG_ 1622 ELV_Txt_Bremse "Text: 'Bremspedal betätigen!'";
CM_ SG_ 1622 ELV_Txt_Defekt "Text: 'Lenkungsverriegelung defekt!'";
CM_ SG_ 1622 ELV_Txt_Kupplung "Text: 'Kupplungspedal betätigen!'";
CM_ SG_ 1622 ELV_Txt_Lkg_Bewegen "Text: 'Lenkrad bewegen!'";
CM_ SG_ 1622 ELV_Txt_P_Gang "Text: 'Wählhebel in Position P bringen!'";
CM_ SG_ 1622 ELV_Txt_Panikabschaltung "Text: 'Notabschaltung''";
CM_ SG_ 1622 ELV_Txt_PN_Gang "Text: 'Wählhebel in Position P/N bringen!'";
CM_ SG_ 1622 ELV_Txt_Werkstatt "Text: 'Lenkungsverriegelung! Werkstatt!'";
CM_ SG_ 1622 ELV_Verriegelt "ELV im Zustand verriegelt
";
CM_ SG_ 1622 ELV_ZAT_betaetigt "Zündanlass-Taster (ZAT) betätigt";
CM_ SG_ 1622 KST_Anf_ZV_Verriegelung "Neuer Verriegelungstrigger für die ZV nach der automatischen Klemmenabschaltung.

Wird bei Kessyfahrzeugen mit StartStop ein aktiver Stop-Mode und Fahrerverlassen erkannt, startet ein 30 Sekunden-Timer. Innerhalb dieser 30 Sekunden hat der Fahrer die Mö";
CM_ SG_ 1622 KST_aut_Abschaltung_Zuendung "Falls bei eingeschalteter Zündung das Abblendlicht aktiv war, muss nach der automatischen Abschaltung der Kl_15 & Kl_S, dass Standlicht aktiv bleiben. Das Signal sendet die Information, dass eine automatische Abschaltung der Kl_15 und Kl_S erfogt.";
CM_ SG_ 1622 KST_Txt_Komfortabschaltung "Dieses Signal fordert im Kombi die Meldung an, die den Fahrer über die ausgeführte automatische Zündungsabschaltung informiert. Signal wird für10s gesendet.";

CM_ SG_ 26 ELV_WFS_Anfrage_CRC "ELV_WFS_Anfrage_CRC";
CM_ SG_ 26 ELV_WFS_Anfrage_Status "ELV_WFS_Anfrage_Status";
CM_ SG_ 26 ELV_WFS_Anfrage_Typ "ELV_WFS_Anfrage_Typ";

CM_ SG_ 184 EM1_Abregelung_Temperatur "Leistungsbegrenzung aufgrund Übertemperatur der E-Maschine / des PWR";
CM_ SG_ 184 EM1_AnlernenElMotor_Anf "Diagnoseanforderung von E-Maschine/PWR: Hybrid-Controller schaltet über MO_EM_Sollmodus=6 bzw. MY3_EM_modeReq=6 E-Maschine/PWR aktiv in den Kalibriermodus (Strategie muss sicherstellen, dass kein Moment bei der EM angefordert wird.)";
CM_ SG_ 184 EM1_AR_aktiv "Ruckeldämpfer aktiv";
CM_ SG_ 184 EM1_Eta_Sys "Instantaneous efficiency of electrical drive EM1 / Momentaner Wirkungsgrad elektrischer Antrieb EM1";
CM_ SG_ 184 EM1_Fehler_ElAntriebFreilauf_Anf "Wird gesetzt um den zwingenden Bedarf einer Umschaltung in den Freilauf anzuzeigen. Vergleiche Signal EM1_MaxZul_Drehzahl.";
CM_ SG_ 184 EM1_Freigabe_Info_WFS "WFS-Freigabeinformation";
CM_ SG_ 184 EM1_Freigabe_Verfallsinfo_WFS "WFS";
CM_ SG_ 184 EM1_HV_betriebsbereit "1: Ready_HV / 1: HV-Netz Spannung im Betriebsbereich";
CM_ SG_ 184 EM1_IstStrom "Momentanwert: Strom über PWR";
CM_ SG_ 184 EM1_Moment_HVVerbraucher "rechnerisch benötigtes Generator-Moment, um den Bedarf der el. Nebenverbraucher incl. Batterieladung abzudecken";
CM_ SG_ 184 EM1_Parken_WFS_Status "Status der Limitierung";
CM_ SG_ 184 EM1_Sperr_Info_WFS "WFS-Sperrinformation
";
CM_ SG_ 184 LE_Kuehlmittel_Sensor "Signal der Sensorelektroden für den Kühlmittelfüllstand aktuell, entstört, bewertet (OK/Mangel)";

CM_ SG_ 199 EM2_Abregelung_Temperatur "Leistungsbegrenzung aufgrund Übertemperatur der E-Maschine / des PWR";
CM_ SG_ 199 EM2_AnlernenElMotor_Anf "Diagnoseanforderung von E-Maschine/PWR: Hybrid-Controller schaltet über MO_EM_Sollmodus=6 bzw. MY3_EM_modeReq=6 E-Maschine/PWR aktiv in den Kalibriermodus (Strategie muss sicherstellen, dass kein Moment bei der EM angefordert wird.)";
CM_ SG_ 199 EM2_AR_aktiv "Ruckeldämpfer aktiv";
CM_ SG_ 199 EM2_Eta_Sys "Instantaneous efficiency of electrical drive EM2 / Momentaner Wirkungsgrad elektrischer Antrieb EM2";
CM_ SG_ 199 EM2_Fehler_ElAntriebFreilauf_Anf "Wird gesetzt um den zwingenden Bedarf einer Umschaltung in den Freilauf anzuzeigen. Vergleiche Signal EM1_MaxZul_Drehzahl.";
CM_ SG_ 199 EM2_Freigabe_Info_WFS "WFS-Freigabeinformation

";
CM_ SG_ 199 EM2_Freigabe_Verfallsinfo_WFS "WFS";
CM_ SG_ 199 EM2_HV_betriebsbereit "1: Ready_HV / 1: HV-Netz Spannung im Betriebsbereich";
CM_ SG_ 199 EM2_IstStrom "Momentanwert: Strom über PWR";
CM_ SG_ 199 EM2_Parken_WFS_Status "Status der Limitierung";
CM_ SG_ 199 EM2_Sperr_Info_WFS "WFS-Sperrinformation
";

CM_ SG_ 624 EmpfEinheit_STSG_HBFS_01_BZ "4bit Botschaftszähler, wird mit jeder Sendebotschaft inkrementiert";
CM_ SG_ 624 EmpfEinheit_STSG_HBFS_01_CRC "Für MLB:
Berechnung siehe Lastenheft 'Kommunikationsabsicherung für FlexRay und CAN'
Ab MQB und MLBevo:
Berechnung siehe Lastenheft 'End-to-End Kommunikationsabsicherung'

Endwerte siehe Begleitdokument 'S-PDU Kennungsfolgen'";
CM_ SG_ 624 EmpfSTSG_HBFS_DatenUeb_Fehler "Fehler bei der Datenübertragung";
CM_ SG_ 624 EmpfSTSG_HBFS_EKS_betaetigt "Status Einklemmschutz";
CM_ SG_ 624 EmpfSTSG_HBFS_EKS_Fehler "Fehler im Einklemmschutz";
CM_ SG_ 624 EmpfSTSG_HBFS_FH_normiert "Fehlende Beschreibung (Import)";
CM_ SG_ 624 EmpfSTSG_HBFS_FH_Oeffnung "Gibt den Fensteröffnungswert in % an.";
CM_ SG_ 624 EmpfSTSG_HBFS_KiSi_Fehler "Status der Kindersicherung unplausibel.";
CM_ SG_ 624 EmpfSTSG_HBFS_SK_betaetigt "Status der Sperrklinke";
CM_ SG_ 624 EmpfSTSG_HBFS_Status_KiSi "Status der elektrischen Kindersicherung in abgesicherter Botschaft.";
CM_ SG_ 624 EmpfSTSG_HBFS_TAG_betaetigt "Betaetigung Türaussengriff";
CM_ SG_ 624 EmpfSTSG_HBFS_TIG_bet_oeffnen "Türinnenbetätigung, Taster Tür öffnen.";
CM_ SG_ 624 EmpfSTSG_HBFS_TIG_bet_schliessen "Türinnenbetätigung, Taster Tür schließen.";
CM_ SG_ 624 EmpfSTSG_HBFS_Vorraste_betaetigt "Status der Vorraste";

CM_ SG_ 623 EmpfEinheit_STSG_HFS_01_BZ "4bit Botschaftszähler, wird mit jeder Sendebotschaft inkrementiert";
CM_ SG_ 623 EmpfEinheit_STSG_HFS_01_CRC "Für MLB:
Berechnung siehe Lastenheft 'Kommunikationsabsicherung für FlexRay und CAN'
Ab MQB und MLBevo:
Berechnung siehe Lastenheft 'End-to-End Kommunikationsabsicherung'

Endwerte siehe Begleitdokument 'S-PDU Kennungsfolgen'";
CM_ SG_ 623 EmpfSTSG_HFS_DatenUeb_Fehler "Fehler bei der Datenübertragung";
CM_ SG_ 623 EmpfSTSG_HFS_EKS_betaetigt "Status Einklemmschutz";
CM_ SG_ 623 EmpfSTSG_HFS_EKS_Fehler "Fehler im Einklemmschutz";
CM_ SG_ 623 EmpfSTSG_HFS_FH_normiert "Fehlende Beschreibung (Import)";
CM_ SG_ 623 EmpfSTSG_HFS_FH_Oeffnung "Gibt den Fensteröffnungswert in % an.";
CM_ SG_ 623 EmpfSTSG_HFS_KiSi_Fehler "Status der Kindersicherung unplausibel.";
CM_ SG_ 623 EmpfSTSG_HFS_SK_betaetigt "Status der Sperrklinke";
CM_ SG_ 623 EmpfSTSG_HFS_Status_KiSi "Status der elektrischen Kindersicherung in abgesicherter Botschaft.";
CM_ SG_ 623 EmpfSTSG_HFS_TAG_betaetigt "Betaetigung Türaussengriff";
CM_ SG_ 623 EmpfSTSG_HFS_TIG_bet_oeffnen "Türinnenbetätigung, Taster Tür öffnen.";
CM_ SG_ 623 EmpfSTSG_HFS_TIG_bet_schliessen "Türinnenbetätigung, Taster Tür schließen.";
CM_ SG_ 623 EmpfSTSG_HFS_Vorraste_betaetigt "Status der Vorraste";

CM_ SG_ 2589283970 DIST_DKmtg_Auth "Vehicle lifetime traveled distance authentic";
CM_ SG_ 2589283970 SOK_Entfernung_02_Signatur "Signatur im Rahmen der durch SOK geschützten Broadcast-Kommunikation

Geschützte Funktion: Wegstreckensicherheit
Geschützte Signale: DIST_DKmtg_Auth";

CM_ SG_ 2331595989 DIST_DKmtg "Vehicle lifetime traveled distance";

CM_ SG_ 2589283751 KBI_Kilometerstand_Extended "Erweiterter Kilometerstand in km (über 999.999 km)";
CM_ SG_ 2589283751 KBI_Kilometerstand_HiRes_meter "Höchauflösenderes Signal als KBI_Kilometerstand_HiRes um Umrechnung zu vermindern und eine höhere Auflösung als 0,1km zu erhalten.
Auflösung 1m / Bit";

CM_ SG_ 258 ASR_Systemstatus "ASR-Systemstatus für Datenablage im EDR";
CM_ SG_ 258 ECD_Bremslicht "Bremslichtansteuerung durch ECD-Funktion";
CM_ SG_ 258 ECD_Fehler "ESP kann die Verzögerungsregelung/Bremsenregelung aufgrund eines internen Fehlers nicht ausführen, mit Fehlereintrag im ESP.
";
CM_ SG_ 258 ECD_nicht_verfuegbar "ESP kann die Verzögerungsregelung/Bremsenregelung temporär nicht ausführen (z.B. Netzwerkmanagement-Betriebe - KL15 Aus; v<18km/h; ESP in Diagnose, ...), ohne Fehlereintrag im ESP.

";
CM_ SG_ 258 EPB_DAA_Randbed_erf "Die Randbedingungen zum automatischen Öffnen der EPB (Funktion DAA) sind erfüllt und ein Betätigen des Fahrpedals führt zum Öffnen der EPB.";
CM_ SG_ 258 EPB_Fehlerstatus_02 "Anpassung der Texte an die  aktuellen Zustände für weitergehende Funktionen (Stillstandsmanager)";
CM_ SG_ 258 EPB_Freig_Verzoeg_Anf "Verzögerungsanforderung	";
CM_ SG_ 258 EPB_Pedalweg_Kuppl "Signal entspricht Tastverhältnis des PWM. Gesamtweg Kupplungspedal 10% bis 90%, damit zu erwartende Werte 25 bis 225. 25 bei Kupplungspedal nicht getreten, 225 bei Kupplungspedal voll durchgetreten.
2% Toleranz wird im Wertebereich ermöglicht (8%-92%).
";
CM_ SG_ 258 EPB_Schalterposition "Spiegelt die Schalterstellung wieder.

0x3 = Schalterfehler ";
CM_ SG_ 258 EPB_Spannkraft "Erzeugte Spannkraft. Bezieht sich auf die Aktuatoren.

MQB: Spannkraftwerte entsprechen nicht den tatsächlichen Spannkräften. Genauere Informationen bitte in der Fachabteilung erfragen! ";
CM_ SG_ 258 EPB_Status "Gibt den Zustand der EPB-Aktuatoren an.

Nur VW526/PAG E2: Wert 0x3 bedeutet 'unbekannt'

";
CM_ SG_ 258 EPB_Status_02 "Erweiterung der Zustände um ein genaueres Bild des aktuellen Zustandes zu erhalten für weitergehende Funktionen ( Stillstandsmanager)
";
CM_ SG_ 258 EPB_Verzoeg_Anf "Steuerungsanforderung an andere Systeme (z.B. ESP), um während der Fahrt, durch den Handbremsschalter ausgelöst, zu bremsen (ECD-Funktion)";
CM_ SG_ 258 ESC_50_BZ "4bit Botschaftszähler, wird mit jeder Sendebotschaft inkrementiert";
CM_ SG_ 258 ESC_50_CRC "Für MLB:
Berechnung siehe Lastenheft 'Kommunikationsabsicherung für FlexRay und CAN'
Ab MQB und MLBevo:
Berechnung siehe Lastenheft 'End-to-End Kommunikationsabsicherung'

Endwerte siehe Begleitdokument 'S-PDU Kennungsfolgen'";
CM_ SG_ 258 ESC_Bremsdruckgradient "Das Signal zeigt den vom Fahrer gedruckten Bremsdruckgradienten";
CM_ SG_ 258 ESC_Fahrerbremswunsch "PHEV: Berechneter Druck anhand des eBKV-Ausgangsstangenwegs sowie ESP-pMC. Reku nicht aktiv--> vergleichbar mit ESP_Bremsdruck; Reku aktiv --> virtueller Bremsdruck
Konv.: entspricht ESP_Bremsdruck";
CM_ SG_ 258 ESC_Fahrerradbremswunschmoment "Berechnetes Moment anhand des eBKV-Ausgangsstangenwegs, THZ-Druck, cp-Faktoren der Bremsen und Bremspedalbetätigung.
Reku nicht aktiv--> entspricht dem berechneten Moment auf Basis THZ-Druck; 
Reku aktiv --> entspricht dem berechneten Moment auf Basis v";
CM_ SG_ 258 ESC_Hydr_Fkt_aktiv "Info über die Aktivität von Druckaufbaufunktionen im ESC und Uebermittlung des Warnlevel an EBKV.";
CM_ SG_ 258 ESC_Motorstartverzoegerung "Mit dem Signal 'Motorstartverzögerung' wird den aktiven Teilnehmern ermöglicht, einen Motorstart durch die Start-Stop-Funktion zu verzögern.";
CM_ SG_ 258 ESC_QBit_Fahrerbremswunsch "Gesetzt bei Ersatzwert, Init oder Fehler.";
CM_ SG_ 258 ESC_Raddruck_max "Stellt den zahlenmäßig höchsten Druckwert der vier modellierten Raddrücke dar.";
CM_ SG_ 258 ESC_SeitenwindAssistent_Eingriff "Mit diesem Statusbit wird eine aktive Regelung durch den Seitenwindassistenten signalisiert.";
CM_ SG_ 258 ESC_Unterdruckmangel_erkannt "ESC hat einen Unterdruckmangel im Bremskraftverstärker festgestellt";
CM_ SG_ 258 ESCGeneratorSollMoment "In MLBevo Faktor in TS_Faktor_Radmomente beachten!

Verzögernd wirkender Antriebsstrangsollmomentenanteil aus Bremspedalbetätigung auf Summenradebene.";
CM_ SG_ 258 ESP_Abrutschen_Stillstand "Das ESP teilt über dieses Bit mit, dass ein Abrutschen im Stillstand erkannt wurde.

Im MQB wird das Signal nicht unterstützt!";
CM_ SG_ 258 ESP_ANB_CM_Rueckk_Umsetz "Das Signal dient als Rückmeldung zum ACC, dass eine angeforderte ANB-CM durchgeführt wird. Die positive Rückmeldung löst u.a. eine entsprechende Fahrerinformation im Kombiinstrument aus";
CM_ SG_ 258 ESP_Anforderung_EPB "ESP fordert von der EPB Öffnen bzw. Schliessen an. Notwendig wegen Autohold-Funktion.";
CM_ SG_ 258 ESP_Anschleppstart_Freigabe "Bilden einer Schleppstartfreigabe aus Fahrdynamiksicht. Schleppstartabbruch bei kritischer Fahrzeugstabilität";
CM_ SG_ 258 ESP_Autohold_aktiv "Rückmeldung an EPB, dass Autohold aktiv ist.";
CM_ SG_ 258 ESP_Autohold_Standby "Rückmeldung an EPB, dass der Fahrer die Funktion Autohold mindestens einmal angefordert hat. Im Fall eines ESP-Ausfalles oder einer Übernahmeaufforderung erfolgt die EPB-Zuschaltung nur nach Setzen dieses Bits. Bit wird gesetzt nach Betätigung des Autohol";
CM_ SG_ 258 ESP_BKV_Unterdruck "Der maximale Wert wird auf 1012 mbar begrenzt.
Dieses Signal wird im AU64x nicht unterstützt.

Hinweis: Auch bei nicht verbautem BKV-Unterdrucksensor könnte während der Initialisierung der Initialisierungswert gesendet werden.";
CM_ SG_ 258 ESP_Bremsdruck "Rohwert des Bremsdrucks
Für Fahrzeuge mit elektrischem Bremskraftverstärker gilt: Aus dem Signal ESP_Bremsdruck lässt sich kein Fahrerbremswunsch ableiten. Das Signal bildet lediglich den hydraulischen Anteil der Fahrzeugverzögerung ab. Der Rohwert des S";
CM_ SG_ 258 ESP_Bremsruck_AWV2 "Das Signal dient als Rückmeldung zum ACC, dass ein angeforderter AWV2-Bremsruck durchgeführt wird. Die positive Rückmeldung löst u.a. eine entsprechende Fahrerinformation im Kombiinstrument aus";
CM_ SG_ 258 ESP_Eingr_HL "wird von QSP und Neigungsanzeige verwendet

Flag wird vom ESP gesetzt, sobald aufgrund eines ESP-Eingriffs am Rad aktiv Druck aufgebaut wird.
Frühestens mit öffnen des Ventils und spätestens bei einem Bremsmoment von 100Nm. Flag bleibt solange gesetzt ";
CM_ SG_ 258 ESP_Eingr_HR "wird von QSP und Neigungsanzeige verwendet

Flag wird vom ESP gesetzt, sobald aufgrund eines ESP-Eingriffs am Rad aktiv Druck aufgebaut wird.
Frühestens mit öffnen des Ventils und spätestens bei einem Bremsmoment von 100Nm. Flag bleibt solange gesetzt ";
CM_ SG_ 258 ESP_Eingr_VL "wird von QSP und Neigungsanzeige verwendet

Flag wird vom ESP gesetzt, sobald aufgrund eines ESP-Eingriffs am Rad aktiv Druck aufgebaut wird.
Frühestens mit öffnen des Ventils und spätestens bei einem Bremsmoment von 100Nm. Flag bleibt solange gesetzt ";
CM_ SG_ 258 ESP_Eingr_VR "wird von QSP und Neigungsanzeige verwendet

Flag wird vom ESP gesetzt, sobald aufgrund eines ESP-Eingriffs am Rad aktiv Druck aufgebaut wird.
Frühestens mit öffnen des Ventils und spätestens bei einem Bremsmoment von 100Nm. Flag bleibt solange gesetzt ";
CM_ SG_ 258 ESP_Fahrer_bremst "Bit wird gesetzt beim Überschreiten der Bremsdruckschwelle

Weiterführende Informationen im Lastenheft spezifiziert und in der entsprechenden Fachabteilung zu erfragen.
";
CM_ SG_ 258 ESP_Fahrer_tritt_ZBR_Schw "Rückmeldung des ESP an AWV, ob der Fahrer die aktuell gültige ZBR-Schwelle übertritt";
CM_ SG_ 258 ESP_FStatus_Anfahrhilfe "Bei gesetztem Bit steht die Funktion Berganfahrassistent (Hillhold) nicht zur Verfügung";
CM_ SG_ 258 ESP_Gierrate "Winkelgeschwindigkeit um die z-Achse, ESP_VZ_Gierrate & ESP_QBit_Gierrate beachten !!!

MLB: gemessener Wert
tatsächliche Auflösung Bosch ESP: 0,27 Grad/s

Ab AU64x Auflösung wie die tatsächliche Skalierung 0,01. Im AU64x und AU57x wird bei ESP-Absch";
CM_ SG_ 258 ESP_HBA_aktiv "Verwendung/Bedienung ab D4
Signal gibt an, ob der hydraulische Bremsassistent im Regler aktiviert wurde

Im MQB wird das Signal nicht unterstützt!

";
CM_ SG_ 258 ESP_HBA_Empfindlichkeit "Signal gibt die aktuell gültige Auslöseempfindlichkeit des Hydraulischen Bremsassistenten an";
CM_ SG_ 258 ESP_HDC_aktiv "MQB und AU57x Allroad: Mit diesem Statusbit wird eine gerade aktive Regelung des Bergabfahrassistenten (Hill Descent Control) signalisiert.";
CM_ SG_ 258 ESP_HDC_Standby "Verwendung/Bedienung im MQB und AU57x Allroad:
Flag wird vom ESP gesetzt, wenn über den HDC-Taster die HDC-Funktion eingeschalten wurde";
CM_ SG_ 258 ESP_Konsistenz_ACC_Botschaft "Rückmeldung zum Sender der Verzögerungsanforderung ACC bezüglich Prüfung CHK/CRC, BZ und langer Timeout. Wird auch gesetzt bei einer Verzögerungsanforderung größer als eine applizierbare Schwelle.

Im D4/C7: Botschaft ACC_05
Im MQB: Botschaft ACC_07";
CM_ SG_ 258 ESP_Konsistenz_AWV2 "Rückmeldung zum Sender einer AWV-Anforderung (ACC-Steuergerät) bezüglich Prüfung der Checksumme, des Botschaftszählers, des langen Timeout und DLC.
";
CM_ SG_ 258 ESP_Konsistenz_TSK "Rückmeldung zum Sender einer Verzögerungsanforderung (Triebstrangskoordinator) bezüglich Prüfung der Checksumme, des Botschaftszählers, des langen Timeout und DLC. Wird auch gesetzt bei Verzögerungsanforderung größer einer applizierbaren Schwelle.
";
CM_ SG_ 258 ESP_Laengsbeschl "Beschleunigungswert in x-Achse

MLB: Im AU64x und AU57x erfolgt die Bereitstellung der Sensorwerte durch SARA-SG! Im AU64x und AU57x wird bei ESP-Abschaltung durch modellgestützte Überwachung das Signal weiterhin ausgegeben.

MQB: reines ABS schickt 0";
CM_ SG_ 258 ESP_Lenkeingriff_ADS "Im Falle eines fahrzeugstabilisierenden Lenkeingriffs des ADS-Systems soll ACC/GRA deaktiviert werden.

Im MQB wird dieses Signal nicht unterstützt!";
CM_ SG_ 258 ESP_Notbremsanzeige "ABS/ASR oder ESP hat Notbremssituation erkannt.
Weiterführende Informationen im Lastenheft spezifiziert und in der entsprechenden Fachabteilung zu erfragen.

";
CM_ SG_ 258 ESP_PLA_Abbruch "Wenn der Bremseingriff abgebrochen wurde, wird in diesem Signal der Grund des Abbruchs dargestellt.
Dies ist nur gültig, wenn der Status ESP_Status_ESP_PLA = '0xA' ist.";
CM_ SG_ 258 ESP_Prefill_ausgeloest "MLB: Verwendung/Bedienung ab D4
zeigt, ob die Funktion Prefill (aufgrund Fahrpedalgradient) ausgelöst wird; zeigt keinen Funktionszustand bezüglich Fehlerstilllegung

MQB: Wird gesetzt bei jeder Art von aktivem Prefill";
CM_ SG_ 258 ESP_QBit_Bremsdruck "QBit des Bremsdrucks. Gesetzt bei Ersatzwert, Init oder Fehler.";
CM_ SG_ 258 ESP_QBit_Fahrer_bremst "Gültigkeit der Bremsdruckschwelleninformation des Signals ESP_Fahrer_bremst vom ESP SG
0x1 = Druckschwelleninformation kann noch nicht oder aufgrund eines Fehlers nicht ausgegeben werden
";
CM_ SG_ 258 ESP_QBit_Gierrate "QBit der Gierrate. Gesetzt bei Ersatzwert, Init oder Fehler. 
";
CM_ SG_ 258 ESP_QBit_Laengsbeschl "QBit der Längsbeschleunigung. Gesetzt bei Ersatzwert, Init oder Fehler. 
";
CM_ SG_ 258 ESP_QBit_Querb "QBit der Querbeschleunigung. Gesetzt bei Ersatzwert, Init oder Fehler. ";
CM_ SG_ 258 ESP_QBit_v_ref "QBit der Referenzgeschwindigkeit ESP_v_ref. Gesetzt bei Ersatzwert, Init oder Fehler.
Detailinformationen zu dem Signal sind dem Lastenheft 'Signalexport - Funktionale Anforderungen an ESP' zu entnehmen - Signal ESP_St_v_fzg_ref";
CM_ SG_ 258 ESP_Querbeschleunigung "Beschleunigungswert in y-Achse

MLB: Gemessener Wert
0xFF = Fehler (wie bereits im Wertebereich spezifizert)
Bei ESP-Abschaltung durch modellgestützte Überwachung wird das Signal weiterhin ausgegeben.
Im AU64x und AU57x erfolgt die Bereitstellung der";
CM_ SG_ 258 ESP_Rueckwaertsfahrt_erkannt "nur bei AU57x und AU416 sowie Audi B8PA
Info, ob Rückwärtsfahrt über internen Algorithmus sicher erkannt

Im MQB wird das Signal nicht unterstützt!";
CM_ SG_ 258 ESP_Schwelle_Unterdruck "Verwendung im MQB für HBV-Projekte oder wenn für St/St ein Unterdrucksensor verbaut ist";
CM_ SG_ 258 ESP_SpannungsAnf "Die Rekuperation kann mit der Anforderung einer höheren Spannung eingeschränkt werden.";
CM_ SG_ 258 ESP_StartStopp_Info "Stopp-Freigabe und Start-Anforderung an den Start-Stopp-Koordinator";
CM_ SG_ 258 ESP_Status_Anfahrhilfe "Funktionsstatus des Berganfahrassistenten
MQB: Auswertung im Getriebe zwecks Standabkopplung";
CM_ SG_ 258 ESP_Status_Bremsdruck "MLB: Bei gesetztem Bit liegt p > ca. 2 bar an, hervorgerufen durch Fahrer, ASR, FZR, ECD, Bremsregler ... bei Abfall des Bits ist p < X bar, bei aktivem ECD-Eingriff Ende des Eingriffs 

Weiterführende Informationen im Lastenheft spezifiziert und in der";
CM_ SG_ 258 ESP_Status_Bremsentemp "ECD-Bremsscheibentemperaturmodell. Rückmeldung für Sender einer ECD Verzögerungsanforderung, ohne Fehlereintrag im ESP";
CM_ SG_ 258 ESP_Status_Bremsentemp_02 "Bremsscheibentemperaturmodell. Rückmeldung für Sender einer Verzögerungsanforderung";
CM_ SG_ 258 ESP_Status_ESP_PLA "Zustand der Statusmaschine der Bremse für die korrespondierende Statusmaschine in dem PLA-SG";
CM_ SG_ 258 ESP_Stillstandsphase_erschoepft "Rückmeldung vom ESP, dass eine angefordertes sicheres Halten im Stillstand nicht mehr länger möglich ist.";
CM_ SG_ 258 ESP_Systemstatus_03 "ESC-Status für Datenablage im EDR";
CM_ SG_ 258 ESP_Tuerkontakt_Fahrertuer "Logischer Pegel der HW-Leitung zum Türkontaktschalter im ESP-SG.
0 > Schalter geschlossen
1 > Schalter offen

Ungefilterter und unplausibilisierter Status der HW-Leitung vom Fahrertür-Türkontaktschalter zum ESP.
Redundanz für Systemsicherheit notwend";
CM_ SG_ 258 ESP_v_ref "MLBevo:
Signal wird nur von einem BOSCH ESP System zur Verfügung gestellt. Exklusives Signal vom BOSCH ESP zum BOSCH Airbag für ROSEII Funktion und für Fahrwerkregelsysteme. 
Verwendung nur nach vorheriger Abstimmung mit den verantwortlichen EF Fachbere";
CM_ SG_ 258 ESP_v_ref_Fahrtrichtung "Signal stellt die Informationen über die Fahrtrichtung des Fahrzeuges dar. Sie wird als Vorzeichen der Referenzgeschwindigkeit ESP_v_ref interpretiert und basiert auf den Drehrichtungen der Räder.
Detailinformationen zu dem Signal sind dem Lastenheft 'Si";
CM_ SG_ 258 ESP_Verz_EPB_aktiv "Bei gesetztem Bit wird die Verzögerungsanforderung von EPB umgesetzt.";
CM_ SG_ 258 ESP_Verz_TSK_aktiv "Rückmeldeinformation an den Triebsstrangkoordinator/ACC, dass die ECD-Verzögerungsanforderung aktuell umgesetzt wird";
CM_ SG_ 258 ESP_Verzoeg_EPB_verf "Bei gesetztem Bit ist der Verzögerungsregeler für EPB verfügbar.";
CM_ SG_ 258 ESP_VZ_Gierrate "Vorzeichen der Gierrate";
CM_ SG_ 258 ESP_ZT_Rueckk_Umsetz "Das Signal dient als Rückmeldung zum ACC, dass eine angeforderte Zielbremsung/Teilbremsung durchgeführt wird. Die positive Rückmeldung löst u.a. eine entsprechende Fahrerinformation im Kombiinstrument aus";
CM_ SG_ 258 SOK_ESC_50_Signatur "Signatur im Rahmen der durch SOK geschützten Broadcast-Kommunikation
Geschützte Funktionen: Airbag-Funktionen, EML, versch. Bremsfunktionen
Geschützte Botschaft: ESC_50";
BA_DEF_REL_ BU_SG_REL_  "GenSigTimeoutTime" INT 0 65535;
BA_DEF_ BO_  "DiagRequest" ENUM "No", "Yes";
BA_DEF_ BO_  "DiagResponse" ENUM "No", "Yes";
BA_DEF_ BO_  "DiagState" ENUM "No", "Yes";
BA_DEF_ BO_  "GenMsgChkConstant" HEX 0 4095;
BA_DEF_ BO_  "GenMsgCycleTime" INT 0 65535;
BA_DEF_ BO_  "GenMsgCycleTimeFast" INT 0 65535;
BA_DEF_ BO_  "GenMsgDelayTime" INT 0 100000;
BA_DEF_ BO_  "GenMsgILSupport" ENUM "No", "Yes";
BA_DEF_ BO_  "GenMsgNrOfRepetition" INT 0 100;
BA_DEF_ BO_  "GenMsgPDUConstants" STRING;
BA_DEF_ BO_  "GenMsgSendType" ENUM "Cyclic", "not_used", "not_used", "not_used", "not_used", "not_used", "not_used", "IfActive", "NoMsgSendType";
BA_DEF_ BO_  "GenMsgStartDelayTime" INT 0 100000;
BA_DEF_ BO_  "NmMessage" ENUM "No", "Yes";
BA_DEF_ BO_  "NmhMessage" ENUM "No", "Yes";
BA_DEF_ BO_  "MsgType" ENUM "Application", "NM ", "NMH", "TP2.0", "ISO-TP ", "BAP", "EID", "KS", "XCP_PRE_CONFIGURED", "XCP_RUNTIME_CONFIGURED";
BA_DEF_ BO_  "VAGTP20_API" HEX 0 255;
BA_DEF_ BO_  "VAGTP20_DynConnection" ENUM "No", "Yes";
BA_DEF_ BO_  "VAGTP20_DynSetup" ENUM "No", "Yes";
BA_DEF_ BO_  "VAGTP20_StatConnection" ENUM "No", "Yes";
BA_DEF_ BO_  "CANFD_BRS" ENUM "0", "1";
BA_DEF_ BO_  "VFrameFormat" ENUM "StandardCAN", "ExtendedCAN", "reserved", "reserved", "reserved", "reserved", "reserved", "reserved", "reserved", "reserved", "reserved", "reserved", "reserved", "reserved", "StandardCAN_FD", "ExtendedCAN_FD";
BA_DEF_ SG_  "GenSigActiveRepetitions" INT -2147483648 2147483647;
BA_DEF_ SG_  "GenSigInactiveValue" INT -2147483648 2147483647;
BA_DEF_ SG_  "GenSigSendType" ENUM "Cyclic", "OnWrite", "OnWriteWithRepetition", "OnChange", "OnChangeWithRepetition", "IfActive", "IfActiveWithRepetition", "NoSigSendType", "OnChangeAndIfActive", "OnChangeAndIfActiveWithRepetition";
BA_DEF_ SG_  "GenSigStartValue" INT -2147483648 2147483647;
BA_DEF_ SG_  "NWM-WakeupAllowed" ENUM "No", "Yes";
BA_DEF_ SG_  "GenSigFuncType" ENUM "NoFunction", "MsgCounter", "CRC-8", "XOR", "XOR-2", "DatedBit", "SW-Kl15", "CHK", "Constant", "Protocol", "CRC-8-SAE_J1850", "CRC-32", "DataLength", "DataID", "MsgCounter16", "SOK-Signatur", "Cluster";
BA_DEF_ SG_  "GenSigSwitchedByIgnition" ENUM "No", "Yes";
BA_DEF_ SG_  "Fehlerwert" HEX 0 2147483647;
BA_DEF_ SG_  "GenSigMissingSourceValue" HEX 0 2147483647;
BA_DEF_DEF_REL_  "GenSigTimeoutTime" 0;
BA_DEF_DEF_  "DiagRequest" "No";
BA_DEF_DEF_  "DiagResponse" "No";
BA_DEF_DEF_  "DiagState" "No";
BA_DEF_DEF_  "GenMsgChkConstant" 0;
BA_DEF_DEF_  "GenMsgCycleTime" 0;
BA_DEF_DEF_  "GenMsgCycleTimeFast" 0;
BA_DEF_DEF_  "GenMsgDelayTime" 0;
BA_DEF_DEF_  "GenMsgILSupport" "No";
BA_DEF_DEF_  "GenMsgNrOfRepetition" 0;
BA_DEF_DEF_  "GenMsgPDUConstants" "";
BA_DEF_DEF_  "GenMsgSendType" "NoMsgSendType";
BA_DEF_DEF_  "GenMsgStartDelayTime" 0;
BA_DEF_DEF_  "NmMessage" "No";
BA_DEF_DEF_  "NmhMessage" "No";
BA_DEF_DEF_  "MsgType" "Application";
BA_DEF_DEF_  "VAGTP20_API" 0;
BA_DEF_DEF_  "VAGTP20_DynConnection" "No";
BA_DEF_DEF_  "VAGTP20_DynSetup" "No";
BA_DEF_DEF_  "VAGTP20_StatConnection" "No";
BA_DEF_DEF_  "CANFD_BRS" "1";
BA_DEF_DEF_  "VFrameFormat" "StandardCAN";
BA_DEF_DEF_  "GenSigActiveRepetitions" 0;
BA_DEF_DEF_  "GenSigInactiveValue" 0;
BA_DEF_DEF_  "GenSigSendType" "NoSigSendType";
BA_DEF_DEF_  "GenSigStartValue" 0;
BA_DEF_DEF_  "NWM-WakeupAllowed" "No";
BA_DEF_DEF_  "GenSigFuncType" "NoFunction";
BA_DEF_DEF_  "GenSigSwitchedByIgnition" "Yes";
BA_DEF_DEF_  "Fehlerwert" 0;
BA_DEF_DEF_  "GenSigMissingSourceValue" 0;
BA_ "GenMsgCycleTime" BO_ 2463978735 100;
BA_ "GenMsgCycleTimeFast" BO_ 2463978735 20;
BA_ "GenMsgDelayTime" BO_ 2463978735 20;
BA_ "GenMsgILSupport" BO_ 2463978735 1;
BA_ "GenMsgNrOfRepetition" BO_ 2463978735 10;
BA_ "GenMsgPDUConstants" BO_ 2463978735 "0x10,0xaa,0xac,0x0c,0x85,0xb3,0xe8,0x3a,0xab,0x34,0x5c,0xeb,0x70,0xa1,0x7a,0x08";
BA_ "GenMsgSendType" BO_ 2463978735 0;
BA_ "CANFD_BRS" BO_ 2463978735 0;
BA_ "VFrameFormat" BO_ 2463978735 15;
BA_ "GenMsgCycleTime" BO_ 2463978736 100;
BA_ "GenMsgCycleTimeFast" BO_ 2463978736 20;
BA_ "GenMsgDelayTime" BO_ 2463978736 20;
BA_ "GenMsgILSupport" BO_ 2463978736 1;
BA_ "GenMsgNrOfRepetition" BO_ 2463978736 10;
BA_ "GenMsgPDUConstants" BO_ 2463978736 "0x41,0x87,0x40,0x5d,0x39,0xbe,0x1b,0x88,0x76,0xf9,0xb3,0x17,0xb6,0x0a,0xd8,0x84";
BA_ "GenMsgSendType" BO_ 2463978736 0;
BA_ "CANFD_BRS" BO_ 2463978736 0;
BA_ "VFrameFormat" BO_ 2463978736 15;
BA_ "GenMsgCycleTime" BO_ 496 500;
BA_ "GenMsgDelayTime" BO_ 496 20;
BA_ "GenMsgILSupport" BO_ 496 1;
BA_ "GenMsgPDUConstants" BO_ 496 "0x2f,0x3c,0x22,0x60,0x18,0xeb,0x63,0x76,0xc5,0x91,0x0f,0x27,0x34,0x04,0x7f,0x02";
BA_ "GenMsgSendType" BO_ 496 0;
BA_ "CANFD_BRS" BO_ 496 0;
BA_ "VFrameFormat" BO_ 496 14;
BA_ "GenMsgCycleTime" BO_ 1603 1000;
BA_ "GenMsgDelayTime" BO_ 1603 100;
BA_ "GenMsgILSupport" BO_ 1603 1;
BA_ "GenMsgSendType" BO_ 1603 0;
BA_ "CANFD_BRS" BO_ 1603 0;
BA_ "VFrameFormat" BO_ 1603 14;
BA_ "GenMsgCycleTime" BO_ 1622 1000;
BA_ "GenMsgCycleTimeFast" BO_ 1622 50;
BA_ "GenMsgDelayTime" BO_ 1622 50;
BA_ "GenMsgILSupport" BO_ 1622 1;
BA_ "GenMsgNrOfRepetition" BO_ 1622 5;
BA_ "GenMsgPDUConstants" BO_ 1622 "0xab,0x2f,0xd3,0x39,0x6f,0x37,0xfa,0x59,0xa4,0x70,0xce,0x11,0x54,0x82,0x62,0x56";
BA_ "GenMsgSendType" BO_ 1622 0;
BA_ "CANFD_BRS" BO_ 1622 0;
BA_ "VFrameFormat" BO_ 1622 14;
BA_ "CANFD_BRS" BO_ 26 0;
BA_ "VFrameFormat" BO_ 26 14;
BA_ "GenMsgCycleTime" BO_ 184 500;
BA_ "GenMsgDelayTime" BO_ 184 20;
BA_ "GenMsgILSupport" BO_ 184 1;
BA_ "GenMsgSendType" BO_ 184 0;
BA_ "CANFD_BRS" BO_ 184 0;
BA_ "VFrameFormat" BO_ 184 14;
BA_ "GenMsgCycleTime" BO_ 199 500;
BA_ "GenMsgDelayTime" BO_ 199 20;
BA_ "GenMsgILSupport" BO_ 199 1;
BA_ "GenMsgSendType" BO_ 199 0;
BA_ "CANFD_BRS" BO_ 199 0;
BA_ "VFrameFormat" BO_ 199 14;
BA_ "GenMsgCycleTime" BO_ 624 100;
BA_ "GenMsgCycleTimeFast" BO_ 624 10;
BA_ "GenMsgDelayTime" BO_ 624 10;
BA_ "GenMsgILSupport" BO_ 624 1;
BA_ "GenMsgNrOfRepetition" BO_ 624 5;
BA_ "GenMsgPDUConstants" BO_ 624 "0x12,0xcd,0x45,0xcb,0x39,0x7c,0x29,0x47,0x3d,0x59,0x69,0xd7,0x98,0xc5,0x11,0xd2";
BA_ "GenMsgSendType" BO_ 624 0;
BA_ "CANFD_BRS" BO_ 624 0;
BA_ "VFrameFormat" BO_ 624 14;
BA_ "GenMsgCycleTime" BO_ 623 100;
BA_ "GenMsgCycleTimeFast" BO_ 623 10;
BA_ "GenMsgDelayTime" BO_ 623 10;
BA_ "GenMsgILSupport" BO_ 623 1;
BA_ "GenMsgNrOfRepetition" BO_ 623 5;
BA_ "GenMsgPDUConstants" BO_ 623 "0x11,0xba,0x23,0xe5,0x47,0x6f,0xd1,0x93,0x12,0x77,0x1f,0xb5,0xeb,0x9f,0x84,0xb6";
BA_ "GenMsgSendType" BO_ 623 0;
BA_ "CANFD_BRS" BO_ 623 0;
BA_ "VFrameFormat" BO_ 623 14;
BA_ "GenMsgCycleTime" BO_ 2589283970 1000;
BA_ "GenMsgILSupport" BO_ 2589283970 1;
BA_ "GenMsgSendType" BO_ 2589283970 0;
BA_ "CANFD_BRS" BO_ 2589283970 0;
BA_ "VFrameFormat" BO_ 2589283970 15;
BA_ "GenMsgCycleTime" BO_ 2331595989 50;
BA_ "GenMsgILSupport" BO_ 2331595989 1;
BA_ "GenMsgSendType" BO_ 2331595989 0;
BA_ "CANFD_BRS" BO_ 2331595989 0;
BA_ "VFrameFormat" BO_ 2331595989 15;
BA_ "GenMsgCycleTime" BO_ 2589283751 500;
BA_ "GenMsgILSupport" BO_ 2589283751 1;
BA_ "GenMsgSendType" BO_ 2589283751 0;
BA_ "CANFD_BRS" BO_ 2589283751 0;
BA_ "VFrameFormat" BO_ 2589283751 15;
BA_ "GenMsgCycleTime" BO_ 258 20;
BA_ "GenMsgILSupport" BO_ 258 1;
BA_ "GenMsgPDUConstants" BO_ 258 "0xd7,0x12,0x85,0x7e,0x0b,0x34,0xfa,0x16,0x7a,0x25,0x2d,0x8f,0x04,0x8e,0x5d,0x35";
BA_ "GenMsgSendType" BO_ 258 0;
BA_ "CANFD_BRS" BO_ 258 0;
BA_ "VFrameFormat" BO_ 258 14;
BA_ "GenSigSendType" SG_ 2463978735 ASW_Warnung_aktiv_HBFS 3;
BA_ "GenSigSwitchedByIgnition" SG_ 2463978735 ASW_Warnung_aktiv_HBFS 0;
BA_ "GenSigSendType" SG_ 2463978735 BFS_Kopfstuetzen_hoch 3;
BA_ "GenSigSwitchedByIgnition" SG_ 2463978735 BFS_Kopfstuetzen_hoch 0;
BA_ "GenSigSendType" SG_ 2463978735 BFS_Kopfstuetzen_runter 3;
BA_ "GenSigSwitchedByIgnition" SG_ 2463978735 BFS_Kopfstuetzen_runter 0;
BA_ "GenSigSendType" SG_ 2463978735 BFS_Laengsverst_vor 3;
BA_ "GenSigSwitchedByIgnition" SG_ 2463978735 BFS_Laengsverst_vor 0;
BA_ "GenSigSendType" SG_ 2463978735 BFS_Laengsverst_zurueck 3;
BA_ "GenSigSwitchedByIgnition" SG_ 2463978735 BFS_Laengsverst_zurueck 0;
BA_ "GenSigSendType" SG_ 2463978735 BFS_Lehnenkopf_vor 3;
BA_ "GenSigSwitchedByIgnition" SG_ 2463978735 BFS_Lehnenkopf_vor 0;
BA_ "GenSigSendType" SG_ 2463978735 BFS_Lehnenkopf_zurueck 3;
BA_ "GenSigSwitchedByIgnition" SG_ 2463978735 BFS_Lehnenkopf_zurueck 0;
BA_ "GenSigSendType" SG_ 2463978735 BFS_Lehnenneigung_vor 3;
BA_ "GenSigSwitchedByIgnition" SG_ 2463978735 BFS_Lehnenneigung_vor 0;
BA_ "GenSigSendType" SG_ 2463978735 BFS_Lehnenneigung_zurueck 3;
BA_ "GenSigSwitchedByIgnition" SG_ 2463978735 BFS_Lehnenneigung_zurueck 0;
BA_ "GenSigSendType" SG_ 2463978735 BFS_Sitzhoehe_hoch 3;
BA_ "GenSigSwitchedByIgnition" SG_ 2463978735 BFS_Sitzhoehe_hoch 0;
BA_ "GenSigSendType" SG_ 2463978735 BFS_Sitzhoehe_runter 3;
BA_ "GenSigSwitchedByIgnition" SG_ 2463978735 BFS_Sitzhoehe_runter 0;
BA_ "GenSigSendType" SG_ 2463978735 DoorFunctions_HBFS_01_BZ 0;
BA_ "GenSigFuncType" SG_ 2463978735 DoorFunctions_HBFS_01_BZ 1;
BA_ "GenSigSwitchedByIgnition" SG_ 2463978735 DoorFunctions_HBFS_01_BZ 0;
BA_ "GenSigSendType" SG_ 2463978735 DoorFunctions_HBFS_01_CRC 0;
BA_ "GenSigFuncType" SG_ 2463978735 DoorFunctions_HBFS_01_CRC 2;
BA_ "GenSigSwitchedByIgnition" SG_ 2463978735 DoorFunctions_HBFS_01_CRC 0;
BA_ "GenSigSendType" SG_ 2463978735 eTAB_HBFS_Oeffnen_Annaeh 0;
BA_ "GenSigSwitchedByIgnition" SG_ 2463978735 eTAB_HBFS_Oeffnen_Annaeh 0;
BA_ "GenSigSendType" SG_ 2463978735 eTAB_HBFS_Oeffnen_Betaet 0;
BA_ "GenSigSwitchedByIgnition" SG_ 2463978735 eTAB_HBFS_Oeffnen_Betaet 0;
BA_ "GenSigSendType" SG_ 2463978735 eTAB_HBFS_Schliessen_Annaeh 0;
BA_ "GenSigSwitchedByIgnition" SG_ 2463978735 eTAB_HBFS_Schliessen_Annaeh 0;
BA_ "GenSigSendType" SG_ 2463978735 eTAB_HBFS_Schliessen_Betaet 0;
BA_ "GenSigSwitchedByIgnition" SG_ 2463978735 eTAB_HBFS_Schliessen_Betaet 0;
BA_ "GenSigSendType" SG_ 2463978735 HBFS_ASW_HMI_defekt 0;
BA_ "GenSigSwitchedByIgnition" SG_ 2463978735 HBFS_ASW_HMI_defekt 0;
BA_ "GenSigSendType" SG_ 2463978735 HBFS_ASW_Warnton 3;
BA_ "GenSigSwitchedByIgnition" SG_ 2463978735 HBFS_ASW_Warnton 0;
BA_ "Fehlerwert" SG_ 2463978735 HBFS_ASW_Warnton 3;
BA_ "GenSigSendType" SG_ 2463978735 HBFS_ASW_Warnung_Aussenlicht 3;
BA_ "GenSigSwitchedByIgnition" SG_ 2463978735 HBFS_ASW_Warnung_Aussenlicht 0;
BA_ "Fehlerwert" SG_ 2463978735 HBFS_ASW_Warnung_Aussenlicht 3;
BA_ "GenSigSendType" SG_ 2463978735 HBFS_FH_Bew_hoch 3;
BA_ "GenSigSwitchedByIgnition" SG_ 2463978735 HBFS_FH_Bew_hoch 0;
BA_ "GenSigSendType" SG_ 2463978735 HBFS_FH_Bew_tief 3;
BA_ "GenSigSwitchedByIgnition" SG_ 2463978735 HBFS_FH_Bew_tief 0;
BA_ "GenSigSendType" SG_ 2463978735 HBFS_FH_Block 3;
BA_ "GenSigSwitchedByIgnition" SG_ 2463978735 HBFS_FH_Block 0;
BA_ "GenSigSendType" SG_ 2463978735 HBFS_FH_Fang 3;
BA_ "GenSigSwitchedByIgnition" SG_ 2463978735 HBFS_FH_Fang 0;
BA_ "GenSigSendType" SG_ 2463978735 HBFS_FH_normiert 3;
BA_ "GenSigSwitchedByIgnition" SG_ 2463978735 HBFS_FH_normiert 0;
BA_ "GenSigSendType" SG_ 2463978735 HBFS_FH_Oeffnung 3;
BA_ "GenSigSwitchedByIgnition" SG_ 2463978735 HBFS_FH_Oeffnung 0;
BA_ "GenSigSendType" SG_ 2463978735 HBFS_FH_S_AutoHoch 3;
BA_ "GenSigSwitchedByIgnition" SG_ 2463978735 HBFS_FH_S_AutoHoch 0;
BA_ "GenSigSendType" SG_ 2463978735 HBFS_FH_S_AutoTief 3;
BA_ "GenSigSwitchedByIgnition" SG_ 2463978735 HBFS_FH_S_AutoTief 0;
BA_ "GenSigSendType" SG_ 2463978735 HBFS_FH_S_HFS_AutoHoch 3;
BA_ "GenSigSwitchedByIgnition" SG_ 2463978735 HBFS_FH_S_HFS_AutoHoch 0;
BA_ "GenSigSendType" SG_ 2463978735 HBFS_FH_S_HFS_AutoTief 3;
BA_ "GenSigSwitchedByIgnition" SG_ 2463978735 HBFS_FH_S_HFS_AutoTief 0;
BA_ "GenSigSendType" SG_ 2463978735 HBFS_FH_S_HFS_ManHoch 3;
BA_ "GenSigSwitchedByIgnition" SG_ 2463978735 HBFS_FH_S_HFS_ManHoch 0;
BA_ "GenSigSendType" SG_ 2463978735 HBFS_FH_S_HFS_ManTief 3;
BA_ "GenSigSwitchedByIgnition" SG_ 2463978735 HBFS_FH_S_HFS_ManTief 0;
BA_ "GenSigSendType" SG_ 2463978735 HBFS_FH_S_ManHoch 3;
BA_ "GenSigSwitchedByIgnition" SG_ 2463978735 HBFS_FH_S_ManHoch 0;
BA_ "GenSigSendType" SG_ 2463978735 HBFS_FH_S_ManTief 3;
BA_ "GenSigSwitchedByIgnition" SG_ 2463978735 HBFS_FH_S_ManTief 0;
BA_ "GenSigSendType" SG_ 2463978735 HBFS_FH_Thermo 3;
BA_ "GenSigSwitchedByIgnition" SG_ 2463978735 HBFS_FH_Thermo 0;
BA_ "GenSigSendType" SG_ 2463978735 HBFS_gesafet 3;
BA_ "GenSigSwitchedByIgnition" SG_ 2463978735 HBFS_gesafet 0;
BA_ "GenSigSendType" SG_ 2463978735 HBFS_Heckrollotaster_betaetigt 3;
BA_ "GenSigSwitchedByIgnition" SG_ 2463978735 HBFS_Heckrollotaster_betaetigt 0;
BA_ "GenSigSendType" SG_ 2463978735 HBFS_KiSi_Fehler 0;
BA_ "GenSigSwitchedByIgnition" SG_ 2463978735 HBFS_KiSi_Fehler 0;
BA_ "GenSigSendType" SG_ 2463978735 HBFS_Lock_Taster 3;
BA_ "GenSigSwitchedByIgnition" SG_ 2463978735 HBFS_Lock_Taster 0;
BA_ "GenSigSendType" SG_ 2463978735 HBFS_Lock_Taster_inv 3;
BA_ "GenSigStartValue" SG_ 2463978735 HBFS_Lock_Taster_inv 1;
BA_ "GenSigSwitchedByIgnition" SG_ 2463978735 HBFS_Lock_Taster_inv 0;
BA_ "GenSigSendType" SG_ 2463978735 HBFS_MRollo_Schalter 3;
BA_ "GenSigStartValue" SG_ 2463978735 HBFS_MRollo_Schalter 6;
BA_ "GenSigSwitchedByIgnition" SG_ 2463978735 HBFS_MRollo_Schalter 0;
BA_ "Fehlerwert" SG_ 2463978735 HBFS_MRollo_Schalter 7;
BA_ "GenSigSendType" SG_ 2463978735 HBFS_Oben_Block_erw 3;
BA_ "GenSigSwitchedByIgnition" SG_ 2463978735 HBFS_Oben_Block_erw 0;
BA_ "GenSigSendType" SG_ 2463978735 HBFS_Push_Tuergriff 3;
BA_ "GenSigSwitchedByIgnition" SG_ 2463978735 HBFS_Push_Tuergriff 0;
BA_ "GenSigSendType" SG_ 2463978735 HBFS_SAD_Schalter 3;
BA_ "GenSigSwitchedByIgnition" SG_ 2463978735 HBFS_SAD_Schalter 0;
BA_ "Fehlerwert" SG_ 2463978735 HBFS_SAD_Schalter 15;
BA_ "GenSigSendType" SG_ 2463978735 HBFS_Schloss_oeffnen_Ansteuerung 3;
BA_ "GenSigSwitchedByIgnition" SG_ 2463978735 HBFS_Schloss_oeffnen_Ansteuerung 0;
BA_ "Fehlerwert" SG_ 2463978735 HBFS_Schloss_oeffnen_Ansteuerung 3;
BA_ "GenSigSendType" SG_ 2463978735 HBFS_Schloss_Status_OeH_Motor 3;
BA_ "GenSigSwitchedByIgnition" SG_ 2463978735 HBFS_Schloss_Status_OeH_Motor 0;
BA_ "Fehlerwert" SG_ 2463978735 HBFS_Schloss_Status_OeH_Motor 3;
BA_ "GenSigSendType" SG_ 2463978735 HBFS_Seitenrollo_hoch 3;
BA_ "GenSigSwitchedByIgnition" SG_ 2463978735 HBFS_Seitenrollo_hoch 0;
BA_ "GenSigSendType" SG_ 2463978735 HBFS_Seitenrollo_tief 3;
BA_ "GenSigSwitchedByIgnition" SG_ 2463978735 HBFS_Seitenrollo_tief 0;
BA_ "GenSigSendType" SG_ 2463978735 HBFS_SK_betaetigt 3;
BA_ "GenSigSwitchedByIgnition" SG_ 2463978735 HBFS_SK_betaetigt 0;
BA_ "GenSigSendType" SG_ 2463978735 HBFS_Sperrklinke 3;
BA_ "GenSigSwitchedByIgnition" SG_ 2463978735 HBFS_Sperrklinke 0;
BA_ "GenSigSendType" SG_ 2463978735 HBFS_Status_eTAG 3;
BA_ "GenSigSwitchedByIgnition" SG_ 2463978735 HBFS_Status_eTAG 0;
BA_ "Fehlerwert" SG_ 2463978735 HBFS_Status_eTAG 3;
BA_ "GenSigSendType" SG_ 2463978735 HBFS_Status_eTAG_ext 3;
BA_ "GenSigStartValue" SG_ 2463978735 HBFS_Status_eTAG_ext 3;
BA_ "GenSigSwitchedByIgnition" SG_ 2463978735 HBFS_Status_eTAG_ext 0;
BA_ "Fehlerwert" SG_ 2463978735 HBFS_Status_eTAG_ext 4;
BA_ "GenSigSendType" SG_ 2463978735 HBFS_Status_KiSi 3;
BA_ "GenSigSwitchedByIgnition" SG_ 2463978735 HBFS_Status_KiSi 0;
BA_ "GenSigSendType" SG_ 2463978735 HBFS_Status_KiSi_inv 3;
BA_ "GenSigStartValue" SG_ 2463978735 HBFS_Status_KiSi_inv 1;
BA_ "GenSigSwitchedByIgnition" SG_ 2463978735 HBFS_Status_KiSi_inv 0;
BA_ "GenSigSendType" SG_ 2463978735 HBFS_TAG_betaetigt 3;
BA_ "GenSigSwitchedByIgnition" SG_ 2463978735 HBFS_TAG_betaetigt 0;
BA_ "GenSigSendType" SG_ 2463978735 HBFS_TCR_Mode_aktiv 3;
BA_ "GenSigSwitchedByIgnition" SG_ 2463978735 HBFS_TCR_Mode_aktiv 0;
BA_ "GenSigSendType" SG_ 2463978735 HBFS_TIG_betaetigt 3;
BA_ "GenSigSwitchedByIgnition" SG_ 2463978735 HBFS_TIG_betaetigt 0;
BA_ "GenSigSendType" SG_ 2463978735 HBFS_TIG_betaetigt_oeffnen 3;
BA_ "GenSigSwitchedByIgnition" SG_ 2463978735 HBFS_TIG_betaetigt_oeffnen 0;
BA_ "GenSigSendType" SG_ 2463978735 HBFS_TIG_betaetigt_schliessen 3;
BA_ "GenSigSwitchedByIgnition" SG_ 2463978735 HBFS_TIG_betaetigt_schliessen 0;
BA_ "GenSigSendType" SG_ 2463978735 HBFS_Tuer_geoeffnet 3;
BA_ "GenSigSwitchedByIgnition" SG_ 2463978735 HBFS_Tuer_geoeffnet 0;
BA_ "GenSigSendType" SG_ 2463978735 HBFS_Tuer_Status 3;
BA_ "GenSigSwitchedByIgnition" SG_ 2463978735 HBFS_Tuer_Status 0;
BA_ "Fehlerwert" SG_ 2463978735 HBFS_Tuer_Status 3;
BA_ "GenSigSendType" SG_ 2463978735 HBFS_Tuer_Status_QBit 3;
BA_ "GenSigSwitchedByIgnition" SG_ 2463978735 HBFS_Tuer_Status_QBit 0;
BA_ "GenSigSendType" SG_ 2463978735 HBFS_Tueroeffnen_Warnung 3;
BA_ "GenSigSwitchedByIgnition" SG_ 2463978735 HBFS_Tueroeffnen_Warnung 0;
BA_ "GenSigSendType" SG_ 2463978735 HBFS_Tuerschloss_defekt 3;
BA_ "GenSigSwitchedByIgnition" SG_ 2463978735 HBFS_Tuerschloss_defekt 0;
BA_ "GenSigSendType" SG_ 2463978735 HBFS_UEKB_aktiviert 3;
BA_ "GenSigSwitchedByIgnition" SG_ 2463978735 HBFS_UEKB_aktiviert 0;
BA_ "GenSigSendType" SG_ 2463978735 HBFS_Unlock_Taster 3;
BA_ "GenSigSwitchedByIgnition" SG_ 2463978735 HBFS_Unlock_Taster 0;
BA_ "GenSigSendType" SG_ 2463978735 HBFS_Unten_Block_erw 3;
BA_ "GenSigSwitchedByIgnition" SG_ 2463978735 HBFS_Unten_Block_erw 0;
BA_ "GenSigSendType" SG_ 2463978735 HBFS_verriegelt 3;
BA_ "GenSigSwitchedByIgnition" SG_ 2463978735 HBFS_verriegelt 0;
BA_ "GenSigSendType" SG_ 2463978735 HBFS_Vorraste_betaetigt 3;
BA_ "GenSigSwitchedByIgnition" SG_ 2463978735 HBFS_Vorraste_betaetigt 0;
BA_ "GenSigSendType" SG_ 2463978735 HBFS_Zuziehhilfe_aktiv 3;
BA_ "GenSigSwitchedByIgnition" SG_ 2463978735 HBFS_Zuziehhilfe_aktiv 0;
BA_ "GenSigSendType" SG_ 2463978735 MTHBF_ein 3;
BA_ "GenSigSwitchedByIgnition" SG_ 2463978735 MTHBF_ein 0;
BA_ "GenSigSendType" SG_ 2463978735 MTHBFS_M_Taste 3;
BA_ "GenSigSwitchedByIgnition" SG_ 2463978735 MTHBFS_M_Taste 0;
BA_ "GenSigSendType" SG_ 2463978735 MTHBFS_Pos1 3;
BA_ "GenSigSwitchedByIgnition" SG_ 2463978735 MTHBFS_Pos1 0;
BA_ "GenSigSendType" SG_ 2463978735 MTHBFS_Pos2 3;
BA_ "GenSigSwitchedByIgnition" SG_ 2463978735 MTHBFS_Pos2 0;
BA_ "GenSigSendType" SG_ 2463978735 MTHBFS_Pos3 3;
BA_ "GenSigSwitchedByIgnition" SG_ 2463978735 MTHBFS_Pos3 0;
BA_ "GenSigSendType" SG_ 2463978735 SOK_Doorfunctions_HBFS_01_Sig001 0;
BA_ "GenSigFuncType" SG_ 2463978735 SOK_Doorfunctions_HBFS_01_Sig001 15;
BA_ "GenSigSwitchedByIgnition" SG_ 2463978735 SOK_Doorfunctions_HBFS_01_Sig001 0;
BA_ "GenSigSendType" SG_ 2463978735 SSA_HBFS_eKisi_Fehler 0;
BA_ "GenSigSwitchedByIgnition" SG_ 2463978735 SSA_HBFS_eKisi_Fehler 0;
BA_ "GenSigSendType" SG_ 2463978735 SSA_HBFS_eKisi_Status 4;
BA_ "GenSigSwitchedByIgnition" SG_ 2463978735 SSA_HBFS_eKisi_Status 0;
BA_ "GenSigSendType" SG_ 2463978735 SSA_HBFT_Amb_Bel_Fehler 0;
BA_ "GenSigSwitchedByIgnition" SG_ 2463978735 SSA_HBFT_Amb_Bel_Fehler 0;
BA_ "GenSigSendType" SG_ 2463978735 SSA_HBFT_Amb_Bel_Status 4;
BA_ "GenSigSwitchedByIgnition" SG_ 2463978735 SSA_HBFT_Amb_Bel_Status 0;
BA_ "GenSigSendType" SG_ 2463978735 SSA_HBFT_ASW_Fehler 0;
BA_ "GenSigSwitchedByIgnition" SG_ 2463978735 SSA_HBFT_ASW_Fehler 0;
BA_ "GenSigSendType" SG_ 2463978735 SSA_HBFT_ASW_Status 4;
BA_ "GenSigSwitchedByIgnition" SG_ 2463978735 SSA_HBFT_ASW_Status 0;
BA_ "GenSigSendType" SG_ 2463978735 SSA_HBFT_el_Tuerantrieb_Fehler 0;
BA_ "GenSigSwitchedByIgnition" SG_ 2463978735 SSA_HBFT_el_Tuerantrieb_Fehler 0;
BA_ "GenSigSendType" SG_ 2463978735 SSA_HBFT_el_Tuerantrieb_Status 4;
BA_ "GenSigSwitchedByIgnition" SG_ 2463978735 SSA_HBFT_el_Tuerantrieb_Status 0;
BA_ "GenSigSendType" SG_ 2463978735 SSA_HBFT_FH_Bewegungsrichutng 4;
BA_ "GenSigSwitchedByIgnition" SG_ 2463978735 SSA_HBFT_FH_Bewegungsrichutng 0;
BA_ "GenSigSendType" SG_ 2463978735 SSA_HBFT_FH_Fehler 0;
BA_ "GenSigSwitchedByIgnition" SG_ 2463978735 SSA_HBFT_FH_Fehler 0;
BA_ "GenSigSendType" SG_ 2463978735 SSA_HBFT_FH_Normierung 4;
BA_ "GenSigSwitchedByIgnition" SG_ 2463978735 SSA_HBFT_FH_Normierung 0;
BA_ "GenSigSendType" SG_ 2463978735 SSA_HBFT_FH_Oeffnungsweite 3;
BA_ "GenSigSwitchedByIgnition" SG_ 2463978735 SSA_HBFT_FH_Oeffnungsweite 0;
BA_ "GenSigSendType" SG_ 2463978735 SSA_HBFT_FH_Thermoschutz 4;
BA_ "GenSigSwitchedByIgnition" SG_ 2463978735 SSA_HBFT_FH_Thermoschutz 0;
BA_ "GenSigSendType" SG_ 2463978735 SSA_HBFT_SSR_Fehler 0;
BA_ "GenSigSwitchedByIgnition" SG_ 2463978735 SSA_HBFT_SSR_Fehler 0;
BA_ "GenSigSendType" SG_ 2463978735 SSA_HBFT_SSR_Status 4;
BA_ "GenSigSwitchedByIgnition" SG_ 2463978735 SSA_HBFT_SSR_Status 0;
BA_ "GenSigSendType" SG_ 2463978735 SSA_HBFT_Tuerverschluss_Fehler 0;
BA_ "GenSigSwitchedByIgnition" SG_ 2463978735 SSA_HBFT_Tuerverschluss_Fehler 0;
BA_ "GenSigSendType" SG_ 2463978735 SSA_HBFT_Tuerverschluss_Status 4;
BA_ "GenSigSwitchedByIgnition" SG_ 2463978735 SSA_HBFT_Tuerverschluss_Status 0;
BA_ "GenSigSendType" SG_ 2463978735 SSA_HBFT_ZV_Fehler 0;
BA_ "GenSigSwitchedByIgnition" SG_ 2463978735 SSA_HBFT_ZV_Fehler 0;
BA_ "GenSigSendType" SG_ 2463978735 SSA_HBFT_ZZH_Fehler 0;
BA_ "GenSigSwitchedByIgnition" SG_ 2463978735 SSA_HBFT_ZZH_Fehler 0;
BA_ "GenSigSendType" SG_ 2463978735 SSA_HBFT_ZZH_Status 4;
BA_ "GenSigSwitchedByIgnition" SG_ 2463978735 SSA_HBFT_ZZH_Status 0;
BA_ "GenSigSendType" SG_ 2463978735 SSR_HBFS_Pos_Unten 0;
BA_ "GenSigSwitchedByIgnition" SG_ 2463978735 SSR_HBFS_Pos_Unten 0;
BA_ "GenSigSendType" SG_ 2463978735 TSG_FlHz_HBFS_FnAbbruchHzKreis_A 0;
BA_ "GenSigSwitchedByIgnition" SG_ 2463978735 TSG_FlHz_HBFS_FnAbbruchHzKreis_A 0;
BA_ "GenSigSendType" SG_ 2463978735 TSG_FlHz_HBFS_FnAbbruchHzKreis_B 0;
BA_ "GenSigSwitchedByIgnition" SG_ 2463978735 TSG_FlHz_HBFS_FnAbbruchHzKreis_B 0;
BA_ "GenSigSendType" SG_ 2463978735 TSG_FlHz_HBFS_NTC_A 0;
BA_ "GenSigStartValue" SG_ 2463978735 TSG_FlHz_HBFS_NTC_A 127;
BA_ "GenSigSwitchedByIgnition" SG_ 2463978735 TSG_FlHz_HBFS_NTC_A 0;
BA_ "GenSigSendType" SG_ 2463978735 TSG_FlHz_HBFS_NTC_B 0;
BA_ "GenSigStartValue" SG_ 2463978735 TSG_FlHz_HBFS_NTC_B 127;
BA_ "GenSigSwitchedByIgnition" SG_ 2463978735 TSG_FlHz_HBFS_NTC_B 0;
BA_ "GenSigSendType" SG_ 2463978735 TSG_FlHz_HBFS_Unterbrech_HzK_A 3;
BA_ "GenSigSwitchedByIgnition" SG_ 2463978735 TSG_FlHz_HBFS_Unterbrech_HzK_A 0;
BA_ "GenSigSendType" SG_ 2463978735 TSG_FlHz_HBFS_Unterbrech_HzK_B 3;
BA_ "GenSigSwitchedByIgnition" SG_ 2463978735 TSG_FlHz_HBFS_Unterbrech_HzK_B 0;
BA_ "GenSigSendType" SG_ 2463978736 ASW_Warnung_aktiv_HFS 3;
BA_ "GenSigSwitchedByIgnition" SG_ 2463978736 ASW_Warnung_aktiv_HFS 0;
BA_ "GenSigSendType" SG_ 2463978736 DoorFunctions_HFS_01_BZ 0;
BA_ "GenSigFuncType" SG_ 2463978736 DoorFunctions_HFS_01_BZ 1;
BA_ "GenSigSwitchedByIgnition" SG_ 2463978736 DoorFunctions_HFS_01_BZ 0;
BA_ "GenSigSendType" SG_ 2463978736 DoorFunctions_HFS_01_CRC 0;
BA_ "GenSigFuncType" SG_ 2463978736 DoorFunctions_HFS_01_CRC 2;
BA_ "GenSigSwitchedByIgnition" SG_ 2463978736 DoorFunctions_HFS_01_CRC 0;
BA_ "GenSigSendType" SG_ 2463978736 eTAB_HFS_Oeffnen_Annaeh 0;
BA_ "GenSigSwitchedByIgnition" SG_ 2463978736 eTAB_HFS_Oeffnen_Annaeh 0;
BA_ "GenSigSendType" SG_ 2463978736 eTAB_HFS_Oeffnen_Betaet 0;
BA_ "GenSigSwitchedByIgnition" SG_ 2463978736 eTAB_HFS_Oeffnen_Betaet 0;
BA_ "GenSigSendType" SG_ 2463978736 eTAB_HFS_Schliessen_Annaeh 0;
BA_ "GenSigSwitchedByIgnition" SG_ 2463978736 eTAB_HFS_Schliessen_Annaeh 0;
BA_ "GenSigSendType" SG_ 2463978736 eTAB_HFS_Schliessen_Betaet 0;
BA_ "GenSigSwitchedByIgnition" SG_ 2463978736 eTAB_HFS_Schliessen_Betaet 0;
BA_ "GenSigSendType" SG_ 2463978736 HFS_ASW_HMI_defekt 0;
BA_ "GenSigSwitchedByIgnition" SG_ 2463978736 HFS_ASW_HMI_defekt 0;
BA_ "GenSigSendType" SG_ 2463978736 HFS_ASW_Warnton 3;
BA_ "GenSigSwitchedByIgnition" SG_ 2463978736 HFS_ASW_Warnton 0;
BA_ "Fehlerwert" SG_ 2463978736 HFS_ASW_Warnton 3;
BA_ "GenSigSendType" SG_ 2463978736 HFS_ASW_Warnung_Aussenlicht 3;
BA_ "GenSigSwitchedByIgnition" SG_ 2463978736 HFS_ASW_Warnung_Aussenlicht 0;
BA_ "Fehlerwert" SG_ 2463978736 HFS_ASW_Warnung_Aussenlicht 3;
BA_ "GenSigSendType" SG_ 2463978736 HFS_FH_Bew_hoch 3;
BA_ "GenSigSwitchedByIgnition" SG_ 2463978736 HFS_FH_Bew_hoch 0;
BA_ "GenSigSendType" SG_ 2463978736 HFS_FH_Bew_tief 3;
BA_ "GenSigSwitchedByIgnition" SG_ 2463978736 HFS_FH_Bew_tief 0;
BA_ "GenSigSendType" SG_ 2463978736 HFS_FH_Block 3;
BA_ "GenSigSwitchedByIgnition" SG_ 2463978736 HFS_FH_Block 0;
BA_ "GenSigSendType" SG_ 2463978736 HFS_FH_Fang 3;
BA_ "GenSigSwitchedByIgnition" SG_ 2463978736 HFS_FH_Fang 0;
BA_ "GenSigSendType" SG_ 2463978736 HFS_FH_normiert 3;
BA_ "GenSigSwitchedByIgnition" SG_ 2463978736 HFS_FH_normiert 0;
BA_ "GenSigSendType" SG_ 2463978736 HFS_FH_Oeffnung 3;
BA_ "GenSigSwitchedByIgnition" SG_ 2463978736 HFS_FH_Oeffnung 0;
BA_ "GenSigSendType" SG_ 2463978736 HFS_FH_S_AutoHoch 3;
BA_ "GenSigSwitchedByIgnition" SG_ 2463978736 HFS_FH_S_AutoHoch 0;
BA_ "GenSigSendType" SG_ 2463978736 HFS_FH_S_AutoTief 3;
BA_ "GenSigSwitchedByIgnition" SG_ 2463978736 HFS_FH_S_AutoTief 0;
BA_ "GenSigSendType" SG_ 2463978736 HFS_FH_S_HBFS_AutoHoch 3;
BA_ "GenSigSwitchedByIgnition" SG_ 2463978736 HFS_FH_S_HBFS_AutoHoch 0;
BA_ "GenSigSendType" SG_ 2463978736 HFS_FH_S_HBFS_AutoTief 3;
BA_ "GenSigSwitchedByIgnition" SG_ 2463978736 HFS_FH_S_HBFS_AutoTief 0;
BA_ "GenSigSendType" SG_ 2463978736 HFS_FH_S_HBFS_ManHoch 3;
BA_ "GenSigSwitchedByIgnition" SG_ 2463978736 HFS_FH_S_HBFS_ManHoch 0;
BA_ "GenSigSendType" SG_ 2463978736 HFS_FH_S_HBFS_ManTief 3;
BA_ "GenSigSwitchedByIgnition" SG_ 2463978736 HFS_FH_S_HBFS_ManTief 0;
BA_ "GenSigSendType" SG_ 2463978736 HFS_FH_S_ManHoch 3;
BA_ "GenSigSwitchedByIgnition" SG_ 2463978736 HFS_FH_S_ManHoch 0;
BA_ "GenSigSendType" SG_ 2463978736 HFS_FH_S_ManTief 3;
BA_ "GenSigSwitchedByIgnition" SG_ 2463978736 HFS_FH_S_ManTief 0;
BA_ "GenSigSendType" SG_ 2463978736 HFS_FH_Thermo 3;
BA_ "GenSigSwitchedByIgnition" SG_ 2463978736 HFS_FH_Thermo 0;
BA_ "GenSigSendType" SG_ 2463978736 HFS_gesafet 3;
BA_ "GenSigSwitchedByIgnition" SG_ 2463978736 HFS_gesafet 0;
BA_ "GenSigSendType" SG_ 2463978736 HFS_Heckrollotaster_betaetigt 3;
BA_ "GenSigSwitchedByIgnition" SG_ 2463978736 HFS_Heckrollotaster_betaetigt 0;
BA_ "GenSigSendType" SG_ 2463978736 HFS_KiSi_Fehler 3;
BA_ "GenSigSwitchedByIgnition" SG_ 2463978736 HFS_KiSi_Fehler 0;
BA_ "GenSigSendType" SG_ 2463978736 HFS_Lock_Taster 3;
BA_ "GenSigSwitchedByIgnition" SG_ 2463978736 HFS_Lock_Taster 0;
BA_ "GenSigSendType" SG_ 2463978736 HFS_Lock_Taster_inv 3;
BA_ "GenSigSwitchedByIgnition" SG_ 2463978736 HFS_Lock_Taster_inv 0;
BA_ "GenSigSendType" SG_ 2463978736 HFS_MRollo_Schalter 3;
BA_ "GenSigStartValue" SG_ 2463978736 HFS_MRollo_Schalter 6;
BA_ "GenSigSwitchedByIgnition" SG_ 2463978736 HFS_MRollo_Schalter 0;
BA_ "Fehlerwert" SG_ 2463978736 HFS_MRollo_Schalter 7;
BA_ "GenSigSendType" SG_ 2463978736 HFS_Oben_Block_erw 3;
BA_ "GenSigSwitchedByIgnition" SG_ 2463978736 HFS_Oben_Block_erw 0;
BA_ "GenSigSendType" SG_ 2463978736 HFS_Push_Tuergriff 3;
BA_ "GenSigSwitchedByIgnition" SG_ 2463978736 HFS_Push_Tuergriff 0;
BA_ "GenSigSendType" SG_ 2463978736 HFS_SAD_Schalter 3;
BA_ "GenSigStartValue" SG_ 2463978736 HFS_SAD_Schalter 14;
BA_ "GenSigSwitchedByIgnition" SG_ 2463978736 HFS_SAD_Schalter 0;
BA_ "Fehlerwert" SG_ 2463978736 HFS_SAD_Schalter 15;
BA_ "GenSigSendType" SG_ 2463978736 HFS_Schloss_oeffnen_Ansteuerung 3;
BA_ "GenSigSwitchedByIgnition" SG_ 2463978736 HFS_Schloss_oeffnen_Ansteuerung 0;
BA_ "Fehlerwert" SG_ 2463978736 HFS_Schloss_oeffnen_Ansteuerung 3;
BA_ "GenSigSendType" SG_ 2463978736 HFS_Schloss_Status_OeH_Motor 3;
BA_ "GenSigSwitchedByIgnition" SG_ 2463978736 HFS_Schloss_Status_OeH_Motor 0;
BA_ "Fehlerwert" SG_ 2463978736 HFS_Schloss_Status_OeH_Motor 3;
BA_ "GenSigSendType" SG_ 2463978736 HFS_Seitenrollo_hoch 3;
BA_ "GenSigSwitchedByIgnition" SG_ 2463978736 HFS_Seitenrollo_hoch 0;
BA_ "GenSigSendType" SG_ 2463978736 HFS_Seitenrollo_tief 3;
BA_ "GenSigSwitchedByIgnition" SG_ 2463978736 HFS_Seitenrollo_tief 0;
BA_ "GenSigSendType" SG_ 2463978736 HFS_SK_betaetigt 3;
BA_ "GenSigSwitchedByIgnition" SG_ 2463978736 HFS_SK_betaetigt 0;
BA_ "GenSigSendType" SG_ 2463978736 HFS_Sperrklinke 3;
BA_ "GenSigSwitchedByIgnition" SG_ 2463978736 HFS_Sperrklinke 0;
BA_ "GenSigSendType" SG_ 2463978736 HFS_Status_eTAG 3;
BA_ "GenSigSwitchedByIgnition" SG_ 2463978736 HFS_Status_eTAG 0;
BA_ "Fehlerwert" SG_ 2463978736 HFS_Status_eTAG 3;
BA_ "GenSigSendType" SG_ 2463978736 HFS_Status_eTAG_ext 3;
BA_ "GenSigStartValue" SG_ 2463978736 HFS_Status_eTAG_ext 3;
BA_ "GenSigSwitchedByIgnition" SG_ 2463978736 HFS_Status_eTAG_ext 0;
BA_ "Fehlerwert" SG_ 2463978736 HFS_Status_eTAG_ext 4;
BA_ "GenSigSendType" SG_ 2463978736 HFS_Status_KiSi 3;
BA_ "GenSigSwitchedByIgnition" SG_ 2463978736 HFS_Status_KiSi 0;
BA_ "GenSigSendType" SG_ 2463978736 HFS_TAG_betaetigt 3;
BA_ "GenSigSwitchedByIgnition" SG_ 2463978736 HFS_TAG_betaetigt 0;
BA_ "GenSigSendType" SG_ 2463978736 HFS_TCR_Mode_aktiv 3;
BA_ "GenSigSwitchedByIgnition" SG_ 2463978736 HFS_TCR_Mode_aktiv 0;
BA_ "GenSigSendType" SG_ 2463978736 HFS_TIG_betaetigt 3;
BA_ "GenSigSwitchedByIgnition" SG_ 2463978736 HFS_TIG_betaetigt 0;
BA_ "GenSigSendType" SG_ 2463978736 HFS_TIG_betaetigt_oeffnen 3;
BA_ "GenSigSwitchedByIgnition" SG_ 2463978736 HFS_TIG_betaetigt_oeffnen 0;
BA_ "GenSigSendType" SG_ 2463978736 HFS_TIG_betaetigt_schliessen 3;
BA_ "GenSigSwitchedByIgnition" SG_ 2463978736 HFS_TIG_betaetigt_schliessen 0;
BA_ "GenSigSendType" SG_ 2463978736 HFS_Tuer_geoeffnet 3;
BA_ "GenSigSwitchedByIgnition" SG_ 2463978736 HFS_Tuer_geoeffnet 0;
BA_ "GenSigSendType" SG_ 2463978736 HFS_Tuer_Status 3;
BA_ "GenSigSwitchedByIgnition" SG_ 2463978736 HFS_Tuer_Status 0;
BA_ "Fehlerwert" SG_ 2463978736 HFS_Tuer_Status 3;
BA_ "GenSigSendType" SG_ 2463978736 HFS_Tuer_Status_QBit 3;
BA_ "GenSigSwitchedByIgnition" SG_ 2463978736 HFS_Tuer_Status_QBit 0;
BA_ "GenSigSendType" SG_ 2463978736 HFS_Tueroeffnen_Warnung 3;
BA_ "GenSigSwitchedByIgnition" SG_ 2463978736 HFS_Tueroeffnen_Warnung 0;
BA_ "GenSigSendType" SG_ 2463978736 HFS_Tuerschloss_defekt 0;
BA_ "GenSigSwitchedByIgnition" SG_ 2463978736 HFS_Tuerschloss_defekt 0;
BA_ "GenSigSendType" SG_ 2463978736 HFS_UEKB_aktiviert 3;
BA_ "GenSigSwitchedByIgnition" SG_ 2463978736 HFS_UEKB_aktiviert 0;
BA_ "GenSigSendType" SG_ 2463978736 HFS_Unlock_Taster 3;
BA_ "GenSigSwitchedByIgnition" SG_ 2463978736 HFS_Unlock_Taster 0;
BA_ "GenSigSendType" SG_ 2463978736 HFS_Unten_Block_erw 3;
BA_ "GenSigSwitchedByIgnition" SG_ 2463978736 HFS_Unten_Block_erw 0;
BA_ "GenSigSendType" SG_ 2463978736 HFS_verriegelt 3;
BA_ "GenSigSwitchedByIgnition" SG_ 2463978736 HFS_verriegelt 0;
BA_ "GenSigSendType" SG_ 2463978736 HFS_Vorraste_betaetigt 3;
BA_ "GenSigSwitchedByIgnition" SG_ 2463978736 HFS_Vorraste_betaetigt 0;
BA_ "GenSigSendType" SG_ 2463978736 HFS_Zuziehhilfe_aktiv 3;
BA_ "GenSigSwitchedByIgnition" SG_ 2463978736 HFS_Zuziehhilfe_aktiv 0;
BA_ "GenSigSendType" SG_ 2463978736 MTHFS_M_Taste 3;
BA_ "GenSigSwitchedByIgnition" SG_ 2463978736 MTHFS_M_Taste 0;
BA_ "GenSigSendType" SG_ 2463978736 MTHFS_Pos1 3;
BA_ "GenSigSwitchedByIgnition" SG_ 2463978736 MTHFS_Pos1 0;
BA_ "GenSigSendType" SG_ 2463978736 MTHFS_Pos2 3;
BA_ "GenSigSwitchedByIgnition" SG_ 2463978736 MTHFS_Pos2 0;
BA_ "GenSigSendType" SG_ 2463978736 MTHFS_Pos3 3;
BA_ "GenSigSwitchedByIgnition" SG_ 2463978736 MTHFS_Pos3 0;
BA_ "GenSigSendType" SG_ 2463978736 SOK_Doorfunctions_HFS_01_Sign002 0;
BA_ "GenSigFuncType" SG_ 2463978736 SOK_Doorfunctions_HFS_01_Sign002 15;
BA_ "GenSigSwitchedByIgnition" SG_ 2463978736 SOK_Doorfunctions_HFS_01_Sign002 0;
BA_ "GenSigSendType" SG_ 2463978736 SSA_HFS_eKisi_Fehler 0;
BA_ "GenSigSwitchedByIgnition" SG_ 2463978736 SSA_HFS_eKisi_Fehler 0;
BA_ "GenSigSendType" SG_ 2463978736 SSA_HFS_eKisi_Status 4;
BA_ "GenSigSwitchedByIgnition" SG_ 2463978736 SSA_HFS_eKisi_Status 0;
BA_ "GenSigSendType" SG_ 2463978736 SSA_HFT_Amb_Bel_Fehler 0;
BA_ "GenSigSwitchedByIgnition" SG_ 2463978736 SSA_HFT_Amb_Bel_Fehler 0;
BA_ "GenSigSendType" SG_ 2463978736 SSA_HFT_Amb_Bel_Status 4;
BA_ "GenSigSwitchedByIgnition" SG_ 2463978736 SSA_HFT_Amb_Bel_Status 0;
BA_ "GenSigSendType" SG_ 2463978736 SSA_HFT_ASW_Fehler 0;
BA_ "GenSigSwitchedByIgnition" SG_ 2463978736 SSA_HFT_ASW_Fehler 0;
BA_ "GenSigSendType" SG_ 2463978736 SSA_HFT_ASW_Status 4;
BA_ "GenSigSwitchedByIgnition" SG_ 2463978736 SSA_HFT_ASW_Status 0;
BA_ "GenSigSendType" SG_ 2463978736 SSA_HFT_el_Tuerantrieb_Fehler 0;
BA_ "GenSigSwitchedByIgnition" SG_ 2463978736 SSA_HFT_el_Tuerantrieb_Fehler 0;
BA_ "GenSigSendType" SG_ 2463978736 SSA_HFT_el_Tuerantrieb_Status 4;
BA_ "GenSigSwitchedByIgnition" SG_ 2463978736 SSA_HFT_el_Tuerantrieb_Status 0;
BA_ "GenSigSendType" SG_ 2463978736 SSA_HFT_FH_Bewegungsrichutng 4;
BA_ "GenSigSwitchedByIgnition" SG_ 2463978736 SSA_HFT_FH_Bewegungsrichutng 0;
BA_ "GenSigSendType" SG_ 2463978736 SSA_HFT_FH_Fehler 0;
BA_ "GenSigSwitchedByIgnition" SG_ 2463978736 SSA_HFT_FH_Fehler 0;
BA_ "GenSigSendType" SG_ 2463978736 SSA_HFT_FH_Normierung 4;
BA_ "GenSigSwitchedByIgnition" SG_ 2463978736 SSA_HFT_FH_Normierung 0;
BA_ "GenSigSendType" SG_ 2463978736 SSA_HFT_FH_Thermoschutz 4;
BA_ "GenSigSwitchedByIgnition" SG_ 2463978736 SSA_HFT_FH_Thermoschutz 0;
BA_ "GenSigSendType" SG_ 2463978736 SSA_HFT_SSR_Fehler 0;
BA_ "GenSigSwitchedByIgnition" SG_ 2463978736 SSA_HFT_SSR_Fehler 0;
BA_ "GenSigSendType" SG_ 2463978736 SSA_HFT_SSR_Status 4;
BA_ "GenSigSwitchedByIgnition" SG_ 2463978736 SSA_HFT_SSR_Status 0;
BA_ "GenSigSendType" SG_ 2463978736 SSA_HFT_Tuerverschluss_Fehler 0;
BA_ "GenSigSwitchedByIgnition" SG_ 2463978736 SSA_HFT_Tuerverschluss_Fehler 0;
BA_ "GenSigSendType" SG_ 2463978736 SSA_HFT_Tuerverschluss_Status 4;
BA_ "GenSigSwitchedByIgnition" SG_ 2463978736 SSA_HFT_Tuerverschluss_Status 0;
BA_ "GenSigSendType" SG_ 2463978736 SSA_HFT_ZV_Ansteuern 4;
BA_ "GenSigSwitchedByIgnition" SG_ 2463978736 SSA_HFT_ZV_Ansteuern 0;
BA_ "Fehlerwert" SG_ 2463978736 SSA_HFT_ZV_Ansteuern 255;
BA_ "GenSigSendType" SG_ 2463978736 SSA_HFT_ZV_Fehler 0;
BA_ "GenSigSwitchedByIgnition" SG_ 2463978736 SSA_HFT_ZV_Fehler 0;
BA_ "GenSigSendType" SG_ 2463978736 SSA_HFT_ZV_Status 4;
BA_ "GenSigSwitchedByIgnition" SG_ 2463978736 SSA_HFT_ZV_Status 0;
BA_ "Fehlerwert" SG_ 2463978736 SSA_HFT_ZV_Status 15;
BA_ "GenSigSendType" SG_ 2463978736 SSA_HFT_ZZH_Fehler 0;
BA_ "GenSigSwitchedByIgnition" SG_ 2463978736 SSA_HFT_ZZH_Fehler 0;
BA_ "GenSigSendType" SG_ 2463978736 SSA_HFT_ZZH_Status 4;
BA_ "GenSigSwitchedByIgnition" SG_ 2463978736 SSA_HFT_ZZH_Status 0;
BA_ "GenSigSendType" SG_ 2463978736 SSR_HFS_Pos_Unten 0;
BA_ "GenSigSwitchedByIgnition" SG_ 2463978736 SSR_HFS_Pos_Unten 0;
BA_ "GenSigSendType" SG_ 2463978736 TSG_FlHz_HFS_FnAbbruchHzKreis_A 0;
BA_ "GenSigSwitchedByIgnition" SG_ 2463978736 TSG_FlHz_HFS_FnAbbruchHzKreis_A 0;
BA_ "GenSigSendType" SG_ 2463978736 TSG_FlHz_HFS_FnAbbruchHzKreis_B 0;
BA_ "GenSigSwitchedByIgnition" SG_ 2463978736 TSG_FlHz_HFS_FnAbbruchHzKreis_B 0;
BA_ "GenSigSendType" SG_ 2463978736 TSG_FlHz_HFS_NTC_A 0;
BA_ "GenSigStartValue" SG_ 2463978736 TSG_FlHz_HFS_NTC_A 127;
BA_ "GenSigSwitchedByIgnition" SG_ 2463978736 TSG_FlHz_HFS_NTC_A 0;
BA_ "GenSigSendType" SG_ 2463978736 TSG_FlHz_HFS_NTC_B 0;
BA_ "GenSigStartValue" SG_ 2463978736 TSG_FlHz_HFS_NTC_B 127;
BA_ "GenSigSwitchedByIgnition" SG_ 2463978736 TSG_FlHz_HFS_NTC_B 0;
BA_ "GenSigSendType" SG_ 2463978736 TSG_FlHz_HFS_Unterbrech_HzK_A 3;
BA_ "GenSigSwitchedByIgnition" SG_ 2463978736 TSG_FlHz_HFS_Unterbrech_HzK_A 0;
BA_ "GenSigSendType" SG_ 496 ACF_Lampe_Hands_Off 3;
BA_ "GenSigSendType" SG_ 496 EA_02_BZ 0;
BA_ "GenSigFuncType" SG_ 496 EA_02_BZ 1;
BA_ "GenSigSendType" SG_ 496 EA_02_CRC 0;
BA_ "GenSigFuncType" SG_ 496 EA_02_CRC 2;
BA_ "GenSigSendType" SG_ 496 EA_Blinken 3;
BA_ "GenSigSendType" SG_ 496 EA_Bremslichtblinken 3;
BA_ "GenSigSendType" SG_ 496 EA_eCall_Anf 3;
BA_ "GenSigSendType" SG_ 496 EA_Fahrzeughupe_Anf 3;
BA_ "GenSigSendType" SG_ 496 EA_Infotainment_Anf 3;
BA_ "GenSigSendType" SG_ 496 EA_Innenraumlicht_Anf 3;
BA_ "GenSigSendType" SG_ 496 EA_Status_HMI 3;
BA_ "GenSigSendType" SG_ 496 EA_Texte 3;
BA_ "GenSigSendType" SG_ 496 EA_Tueren_Anf 3;
BA_ "GenSigSendType" SG_ 496 EA_Warnlevel 3;
BA_ "GenSigSendType" SG_ 496 STP_Primaeranz 3;
BA_ "GenSigSendType" SG_ 496 zFAS_Warnblinken 3;
BA_ "GenSigSendType" SG_ 1603 KBI_Einheit_Datum 3;
BA_ "GenSigSwitchedByIgnition" SG_ 1603 KBI_Einheit_Datum 0;
BA_ "GenSigSendType" SG_ 1603 KBI_Einheit_Druck 3;
BA_ "GenSigSwitchedByIgnition" SG_ 1603 KBI_Einheit_Druck 0;
BA_ "GenSigSendType" SG_ 1603 KBI_Einheit_Masse 3;
BA_ "GenSigSwitchedByIgnition" SG_ 1603 KBI_Einheit_Masse 0;
BA_ "GenSigSendType" SG_ 1603 KBI_Einheit_Sprache 3;
BA_ "GenSigSwitchedByIgnition" SG_ 1603 KBI_Einheit_Sprache 0;
BA_ "GenSigSendType" SG_ 1603 KBI_Einheit_Streckenanz 3;
BA_ "GenSigSwitchedByIgnition" SG_ 1603 KBI_Einheit_Streckenanz 0;
BA_ "GenSigSendType" SG_ 1603 KBI_Einheit_Tacho 3;
BA_ "GenSigSwitchedByIgnition" SG_ 1603 KBI_Einheit_Tacho 0;
BA_ "GenSigSendType" SG_ 1603 KBI_Einheit_Temp 3;
BA_ "GenSigSwitchedByIgnition" SG_ 1603 KBI_Einheit_Temp 0;
BA_ "GenSigSendType" SG_ 1603 KBI_Einheit_Uhrzeit 3;
BA_ "GenSigSwitchedByIgnition" SG_ 1603 KBI_Einheit_Uhrzeit 0;
BA_ "GenSigSendType" SG_ 1603 KBI_Einheit_Verbrauch 3;
BA_ "GenSigSwitchedByIgnition" SG_ 1603 KBI_Einheit_Verbrauch 0;
BA_ "GenSigSendType" SG_ 1603 KBI_Einheit_Verbrauch_elektr 3;
BA_ "GenSigSwitchedByIgnition" SG_ 1603 KBI_Einheit_Verbrauch_elektr 0;
BA_ "GenSigSendType" SG_ 1603 KBI_Einheit_Verbrauch_Gas 3;
BA_ "GenSigSwitchedByIgnition" SG_ 1603 KBI_Einheit_Verbrauch_Gas 0;
BA_ "GenSigSendType" SG_ 1603 KBI_Einheit_Volumen 3;
BA_ "GenSigSwitchedByIgnition" SG_ 1603 KBI_Einheit_Volumen 0;
BA_ "GenSigSendType" SG_ 1603 KBI_MFA_v_Einheit_02 3;
BA_ "GenSigSwitchedByIgnition" SG_ 1603 KBI_MFA_v_Einheit_02 0;
BA_ "GenSigSendType" SG_ 1622 ELV_01_BZ 0;
BA_ "GenSigFuncType" SG_ 1622 ELV_01_BZ 1;
BA_ "GenSigSwitchedByIgnition" SG_ 1622 ELV_01_BZ 0;
BA_ "GenSigSendType" SG_ 1622 ELV_01_CRC 0;
BA_ "GenSigFuncType" SG_ 1622 ELV_01_CRC 2;
BA_ "GenSigSwitchedByIgnition" SG_ 1622 ELV_01_CRC 0;
BA_ "GenSigSendType" SG_ 1622 ELV_01_Sendestatus 5;
BA_ "GenSigSwitchedByIgnition" SG_ 1622 ELV_01_Sendestatus 0;
BA_ "GenSigSendType" SG_ 1622 ELV_Abbruch_Anf_Klemmenfreigabe 3;
BA_ "GenSigSwitchedByIgnition" SG_ 1622 ELV_Abbruch_Anf_Klemmenfreigabe 0;
BA_ "GenSigSendType" SG_ 1622 ELV_Anf_Klemme_15 3;
BA_ "GenSigSwitchedByIgnition" SG_ 1622 ELV_Anf_Klemme_15 0;
BA_ "GenSigSendType" SG_ 1622 ELV_Anf_Klemme_50 3;
BA_ "GenSigSwitchedByIgnition" SG_ 1622 ELV_Anf_Klemme_50 0;
BA_ "GenSigSendType" SG_ 1622 ELV_Anf_Klemme_S 3;
BA_ "GenSigSwitchedByIgnition" SG_ 1622 ELV_Anf_Klemme_S 0;
BA_ "GenSigSendType" SG_ 1622 ELV_Anlernmodus 3;
BA_ "GenSigSwitchedByIgnition" SG_ 1622 ELV_Anlernmodus 0;
BA_ "GenSigSendType" SG_ 1622 ELV_Entriegelt 3;
BA_ "GenSigSwitchedByIgnition" SG_ 1622 ELV_Entriegelt 0;
BA_ "GenSigSendType" SG_ 1622 ELV_Klemmenfreigabe 3;
BA_ "GenSigSwitchedByIgnition" SG_ 1622 ELV_Klemmenfreigabe 0;
BA_ "GenSigSendType" SG_ 1622 ELV_Lebenszustand 3;
BA_ "GenSigSwitchedByIgnition" SG_ 1622 ELV_Lebenszustand 0;
BA_ "GenSigSendType" SG_ 1622 ELV_LED_Gelb 3;
BA_ "GenSigSwitchedByIgnition" SG_ 1622 ELV_LED_Gelb 0;
BA_ "GenSigSendType" SG_ 1622 ELV_LED_Rot 3;
BA_ "GenSigSwitchedByIgnition" SG_ 1622 ELV_LED_Rot 0;
BA_ "GenSigSendType" SG_ 1622 ELV_P_verriegelt 3;
BA_ "GenSigSwitchedByIgnition" SG_ 1622 ELV_P_verriegelt 0;
BA_ "GenSigSendType" SG_ 1622 ELV_Txt_Bremse 3;
BA_ "GenSigSwitchedByIgnition" SG_ 1622 ELV_Txt_Bremse 0;
BA_ "GenSigSendType" SG_ 1622 ELV_Txt_Defekt 3;
BA_ "GenSigSwitchedByIgnition" SG_ 1622 ELV_Txt_Defekt 0;
BA_ "GenSigSendType" SG_ 1622 ELV_Txt_Kupplung 3;
BA_ "GenSigSwitchedByIgnition" SG_ 1622 ELV_Txt_Kupplung 0;
BA_ "GenSigSendType" SG_ 1622 ELV_Txt_Lkg_Bewegen 3;
BA_ "GenSigSwitchedByIgnition" SG_ 1622 ELV_Txt_Lkg_Bewegen 0;
BA_ "GenSigSendType" SG_ 1622 ELV_Txt_P_Gang 3;
BA_ "GenSigSwitchedByIgnition" SG_ 1622 ELV_Txt_P_Gang 0;
BA_ "GenSigSendType" SG_ 1622 ELV_Txt_Panikabschaltung 3;
BA_ "GenSigSwitchedByIgnition" SG_ 1622 ELV_Txt_Panikabschaltung 0;
BA_ "GenSigSendType" SG_ 1622 ELV_Txt_PN_Gang 3;
BA_ "GenSigSwitchedByIgnition" SG_ 1622 ELV_Txt_PN_Gang 0;
BA_ "GenSigSendType" SG_ 1622 ELV_Txt_Werkstatt 3;
BA_ "GenSigSwitchedByIgnition" SG_ 1622 ELV_Txt_Werkstatt 0;
BA_ "GenSigSendType" SG_ 1622 ELV_Verriegelt 3;
BA_ "GenSigSwitchedByIgnition" SG_ 1622 ELV_Verriegelt 0;
BA_ "GenSigSendType" SG_ 1622 ELV_ZAT_betaetigt 3;
BA_ "GenSigSwitchedByIgnition" SG_ 1622 ELV_ZAT_betaetigt 0;
BA_ "GenSigSendType" SG_ 1622 KST_Anf_ZV_Verriegelung 3;
BA_ "GenSigSwitchedByIgnition" SG_ 1622 KST_Anf_ZV_Verriegelung 0;
BA_ "GenSigSendType" SG_ 1622 KST_aut_Abschaltung_Zuendung 4;
BA_ "GenSigSwitchedByIgnition" SG_ 1622 KST_aut_Abschaltung_Zuendung 0;
BA_ "GenSigSendType" SG_ 1622 KST_Txt_Komfortabschaltung 3;
BA_ "GenSigSwitchedByIgnition" SG_ 1622 KST_Txt_Komfortabschaltung 0;
BA_ "GenSigSwitchedByIgnition" SG_ 26 ELV_WFS_Anfrage_CRC 0;
BA_ "GenSigSwitchedByIgnition" SG_ 26 ELV_WFS_Anfrage_Status 0;
BA_ "GenSigSwitchedByIgnition" SG_ 26 ELV_WFS_Anfrage_Typ 0;
BA_ "GenSigSendType" SG_ 184 EM1_Abregelung_Temperatur 0;
BA_ "GenSigSwitchedByIgnition" SG_ 184 EM1_Abregelung_Temperatur 0;
BA_ "GenSigSendType" SG_ 184 EM1_AnlernenElMotor_Anf 0;
BA_ "GenSigSwitchedByIgnition" SG_ 184 EM1_AnlernenElMotor_Anf 0;
BA_ "GenSigSendType" SG_ 184 EM1_AR_aktiv 0;
BA_ "GenSigSwitchedByIgnition" SG_ 184 EM1_AR_aktiv 0;
BA_ "GenSigSendType" SG_ 184 EM1_Eta_Sys 0;
BA_ "GenSigStartValue" SG_ 184 EM1_Eta_Sys 510;
BA_ "GenSigSwitchedByIgnition" SG_ 184 EM1_Eta_Sys 0;
BA_ "Fehlerwert" SG_ 184 EM1_Eta_Sys 511;
BA_ "GenSigSendType" SG_ 184 EM1_Fehler_ElAntriebFreilauf_Anf 0;
BA_ "GenSigSwitchedByIgnition" SG_ 184 EM1_Fehler_ElAntriebFreilauf_Anf 0;
BA_ "GenSigSendType" SG_ 184 EM1_Freigabe_Info_WFS 3;
BA_ "GenSigSwitchedByIgnition" SG_ 184 EM1_Freigabe_Info_WFS 0;
BA_ "GenSigSendType" SG_ 184 EM1_Freigabe_Verfallsinfo_WFS 3;
BA_ "GenSigSwitchedByIgnition" SG_ 184 EM1_Freigabe_Verfallsinfo_WFS 0;
BA_ "GenSigSendType" SG_ 184 EM1_HV_betriebsbereit 0;
BA_ "GenSigSwitchedByIgnition" SG_ 184 EM1_HV_betriebsbereit 0;
BA_ "GenSigSendType" SG_ 184 EM1_IstStrom 0;
BA_ "GenSigStartValue" SG_ 184 EM1_IstStrom 2046;
BA_ "GenSigSwitchedByIgnition" SG_ 184 EM1_IstStrom 0;
BA_ "Fehlerwert" SG_ 184 EM1_IstStrom 2047;
BA_ "GenSigSendType" SG_ 184 EM1_Moment_HVVerbraucher 0;
BA_ "GenSigStartValue" SG_ 184 EM1_Moment_HVVerbraucher 1023;
BA_ "GenSigSwitchedByIgnition" SG_ 184 EM1_Moment_HVVerbraucher 0;
BA_ "GenSigSendType" SG_ 184 EM1_Parken_WFS_Status 3;
BA_ "GenSigSwitchedByIgnition" SG_ 184 EM1_Parken_WFS_Status 0;
BA_ "GenSigSendType" SG_ 184 EM1_Sperr_Info_WFS 3;
BA_ "GenSigSwitchedByIgnition" SG_ 184 EM1_Sperr_Info_WFS 0;
BA_ "GenSigSendType" SG_ 184 LE_Kuehlmittel_Sensor 3;
BA_ "GenSigSwitchedByIgnition" SG_ 184 LE_Kuehlmittel_Sensor 0;
BA_ "GenSigSendType" SG_ 199 EM2_Abregelung_Temperatur 0;
BA_ "GenSigSwitchedByIgnition" SG_ 199 EM2_Abregelung_Temperatur 0;
BA_ "GenSigSendType" SG_ 199 EM2_AnlernenElMotor_Anf 0;
BA_ "GenSigSwitchedByIgnition" SG_ 199 EM2_AnlernenElMotor_Anf 0;
BA_ "GenSigSendType" SG_ 199 EM2_AR_aktiv 0;
BA_ "GenSigSwitchedByIgnition" SG_ 199 EM2_AR_aktiv 0;
BA_ "GenSigSendType" SG_ 199 EM2_Eta_Sys 0;
BA_ "GenSigStartValue" SG_ 199 EM2_Eta_Sys 510;
BA_ "GenSigSwitchedByIgnition" SG_ 199 EM2_Eta_Sys 0;
BA_ "Fehlerwert" SG_ 199 EM2_Eta_Sys 511;
BA_ "GenSigSendType" SG_ 199 EM2_Fehler_ElAntriebFreilauf_Anf 0;
BA_ "GenSigSwitchedByIgnition" SG_ 199 EM2_Fehler_ElAntriebFreilauf_Anf 0;
BA_ "GenSigSendType" SG_ 199 EM2_Freigabe_Info_WFS 3;
BA_ "GenSigSwitchedByIgnition" SG_ 199 EM2_Freigabe_Info_WFS 0;
BA_ "GenSigSendType" SG_ 199 EM2_Freigabe_Verfallsinfo_WFS 3;
BA_ "GenSigSwitchedByIgnition" SG_ 199 EM2_Freigabe_Verfallsinfo_WFS 0;
BA_ "GenSigSendType" SG_ 199 EM2_HV_betriebsbereit 0;
BA_ "GenSigSwitchedByIgnition" SG_ 199 EM2_HV_betriebsbereit 0;
BA_ "GenSigSendType" SG_ 199 EM2_IstStrom 0;
BA_ "GenSigStartValue" SG_ 199 EM2_IstStrom 2046;
BA_ "GenSigSwitchedByIgnition" SG_ 199 EM2_IstStrom 0;
BA_ "Fehlerwert" SG_ 199 EM2_IstStrom 2047;
BA_ "GenSigSendType" SG_ 199 EM2_Parken_WFS_Status 3;
BA_ "GenSigSwitchedByIgnition" SG_ 199 EM2_Parken_WFS_Status 0;
BA_ "GenSigSendType" SG_ 199 EM2_Sperr_Info_WFS 3;
BA_ "GenSigSwitchedByIgnition" SG_ 199 EM2_Sperr_Info_WFS 0;
BA_ "GenSigSendType" SG_ 624 EmpfEinheit_STSG_HBFS_01_BZ 0;
BA_ "GenSigFuncType" SG_ 624 EmpfEinheit_STSG_HBFS_01_BZ 1;
BA_ "GenSigSwitchedByIgnition" SG_ 624 EmpfEinheit_STSG_HBFS_01_BZ 0;
BA_ "GenSigSendType" SG_ 624 EmpfEinheit_STSG_HBFS_01_CRC 0;
BA_ "GenSigFuncType" SG_ 624 EmpfEinheit_STSG_HBFS_01_CRC 2;
BA_ "GenSigSwitchedByIgnition" SG_ 624 EmpfEinheit_STSG_HBFS_01_CRC 0;
BA_ "GenSigSendType" SG_ 624 EmpfSTSG_HBFS_DatenUeb_Fehler 3;
BA_ "GenSigSwitchedByIgnition" SG_ 624 EmpfSTSG_HBFS_DatenUeb_Fehler 0;
BA_ "Fehlerwert" SG_ 624 EmpfSTSG_HBFS_DatenUeb_Fehler 1;
BA_ "GenSigSendType" SG_ 624 EmpfSTSG_HBFS_EKS_betaetigt 4;
BA_ "GenSigSwitchedByIgnition" SG_ 624 EmpfSTSG_HBFS_EKS_betaetigt 0;
BA_ "GenSigSendType" SG_ 624 EmpfSTSG_HBFS_EKS_Fehler 4;
BA_ "GenSigSwitchedByIgnition" SG_ 624 EmpfSTSG_HBFS_EKS_Fehler 0;
BA_ "Fehlerwert" SG_ 624 EmpfSTSG_HBFS_EKS_Fehler 1;
BA_ "GenSigSendType" SG_ 624 EmpfSTSG_HBFS_FH_normiert 3;
BA_ "GenSigSwitchedByIgnition" SG_ 624 EmpfSTSG_HBFS_FH_normiert 0;
BA_ "GenSigSendType" SG_ 624 EmpfSTSG_HBFS_FH_Oeffnung 3;
BA_ "GenSigSwitchedByIgnition" SG_ 624 EmpfSTSG_HBFS_FH_Oeffnung 0;
BA_ "GenSigSendType" SG_ 624 EmpfSTSG_HBFS_KiSi_Fehler 3;
BA_ "GenSigSwitchedByIgnition" SG_ 624 EmpfSTSG_HBFS_KiSi_Fehler 0;
BA_ "Fehlerwert" SG_ 624 EmpfSTSG_HBFS_KiSi_Fehler 1;
BA_ "GenSigSendType" SG_ 624 EmpfSTSG_HBFS_SK_betaetigt 3;
BA_ "GenSigSwitchedByIgnition" SG_ 624 EmpfSTSG_HBFS_SK_betaetigt 0;
BA_ "GenSigSendType" SG_ 624 EmpfSTSG_HBFS_Status_KiSi 3;
BA_ "GenSigSwitchedByIgnition" SG_ 624 EmpfSTSG_HBFS_Status_KiSi 0;
BA_ "GenSigSendType" SG_ 624 EmpfSTSG_HBFS_TAG_betaetigt 3;
BA_ "GenSigSwitchedByIgnition" SG_ 624 EmpfSTSG_HBFS_TAG_betaetigt 0;
BA_ "GenSigSendType" SG_ 624 EmpfSTSG_HBFS_TIG_bet_oeffnen 3;
BA_ "GenSigSwitchedByIgnition" SG_ 624 EmpfSTSG_HBFS_TIG_bet_oeffnen 0;
BA_ "GenSigSendType" SG_ 624 EmpfSTSG_HBFS_TIG_bet_schliessen 3;
BA_ "GenSigSwitchedByIgnition" SG_ 624 EmpfSTSG_HBFS_TIG_bet_schliessen 0;
BA_ "GenSigSendType" SG_ 624 EmpfSTSG_HBFS_Vorraste_betaetigt 3;
BA_ "GenSigSwitchedByIgnition" SG_ 624 EmpfSTSG_HBFS_Vorraste_betaetigt 0;
BA_ "GenSigSendType" SG_ 623 EmpfEinheit_STSG_HFS_01_BZ 0;
BA_ "GenSigFuncType" SG_ 623 EmpfEinheit_STSG_HFS_01_BZ 1;
BA_ "GenSigSwitchedByIgnition" SG_ 623 EmpfEinheit_STSG_HFS_01_BZ 0;
BA_ "GenSigSendType" SG_ 623 EmpfEinheit_STSG_HFS_01_CRC 0;
BA_ "GenSigFuncType" SG_ 623 EmpfEinheit_STSG_HFS_01_CRC 2;
BA_ "GenSigSwitchedByIgnition" SG_ 623 EmpfEinheit_STSG_HFS_01_CRC 0;
BA_ "GenSigSendType" SG_ 623 EmpfSTSG_HFS_DatenUeb_Fehler 3;
BA_ "GenSigSwitchedByIgnition" SG_ 623 EmpfSTSG_HFS_DatenUeb_Fehler 0;
BA_ "Fehlerwert" SG_ 623 EmpfSTSG_HFS_DatenUeb_Fehler 1;
BA_ "GenSigSendType" SG_ 623 EmpfSTSG_HFS_EKS_betaetigt 4;
BA_ "GenSigSwitchedByIgnition" SG_ 623 EmpfSTSG_HFS_EKS_betaetigt 0;
BA_ "GenSigSendType" SG_ 623 EmpfSTSG_HFS_EKS_Fehler 4;
BA_ "GenSigSwitchedByIgnition" SG_ 623 EmpfSTSG_HFS_EKS_Fehler 0;
BA_ "Fehlerwert" SG_ 623 EmpfSTSG_HFS_EKS_Fehler 1;
BA_ "GenSigSendType" SG_ 623 EmpfSTSG_HFS_FH_normiert 3;
BA_ "GenSigSwitchedByIgnition" SG_ 623 EmpfSTSG_HFS_FH_normiert 0;
BA_ "GenSigSendType" SG_ 623 EmpfSTSG_HFS_FH_Oeffnung 3;
BA_ "GenSigSwitchedByIgnition" SG_ 623 EmpfSTSG_HFS_FH_Oeffnung 0;
BA_ "GenSigSendType" SG_ 623 EmpfSTSG_HFS_KiSi_Fehler 3;
BA_ "GenSigSwitchedByIgnition" SG_ 623 EmpfSTSG_HFS_KiSi_Fehler 0;
BA_ "Fehlerwert" SG_ 623 EmpfSTSG_HFS_KiSi_Fehler 1;
BA_ "GenSigSendType" SG_ 623 EmpfSTSG_HFS_SK_betaetigt 3;
BA_ "GenSigSwitchedByIgnition" SG_ 623 EmpfSTSG_HFS_SK_betaetigt 0;
BA_ "GenSigSendType" SG_ 623 EmpfSTSG_HFS_Status_KiSi 3;
BA_ "GenSigSwitchedByIgnition" SG_ 623 EmpfSTSG_HFS_Status_KiSi 0;
BA_ "GenSigSendType" SG_ 623 EmpfSTSG_HFS_TAG_betaetigt 3;
BA_ "GenSigSwitchedByIgnition" SG_ 623 EmpfSTSG_HFS_TAG_betaetigt 0;
BA_ "GenSigSendType" SG_ 623 EmpfSTSG_HFS_TIG_bet_oeffnen 3;
BA_ "GenSigSwitchedByIgnition" SG_ 623 EmpfSTSG_HFS_TIG_bet_oeffnen 0;
BA_ "GenSigSendType" SG_ 623 EmpfSTSG_HFS_TIG_bet_schliessen 3;
BA_ "GenSigSwitchedByIgnition" SG_ 623 EmpfSTSG_HFS_TIG_bet_schliessen 0;
BA_ "GenSigSendType" SG_ 623 EmpfSTSG_HFS_Vorraste_betaetigt 3;
BA_ "GenSigSwitchedByIgnition" SG_ 623 EmpfSTSG_HFS_Vorraste_betaetigt 0;
BA_ "GenSigSendType" SG_ 2589283970 DIST_DKmtg_Auth 0;
BA_ "GenSigSwitchedByIgnition" SG_ 2589283970 DIST_DKmtg_Auth 0;
BA_ "GenSigSendType" SG_ 2589283970 SOK_Entfernung_02_Signatur 0;
BA_ "GenSigFuncType" SG_ 2589283970 SOK_Entfernung_02_Signatur 15;
BA_ "GenSigSwitchedByIgnition" SG_ 2589283970 SOK_Entfernung_02_Signatur 0;
BA_ "GenSigSendType" SG_ 2331595989 DIST_DKmtg 0;
BA_ "GenSigSwitchedByIgnition" SG_ 2331595989 DIST_DKmtg 0;
BA_ "GenSigSendType" SG_ 2589283751 KBI_Kilometerstand_Extended 0;
BA_ "GenSigStartValue" SG_ 2589283751 KBI_Kilometerstand_Extended 16777214;
BA_ "GenSigSwitchedByIgnition" SG_ 2589283751 KBI_Kilometerstand_Extended 0;
BA_ "Fehlerwert" SG_ 2589283751 KBI_Kilometerstand_Extended 16777215;
BA_ "GenSigSendType" SG_ 2589283751 KBI_Kilometerstand_HiRes_meter 0;
BA_ "GenSigSwitchedByIgnition" SG_ 2589283751 KBI_Kilometerstand_HiRes_meter 0;
BA_ "GenSigSendType" SG_ 258 ASR_Systemstatus 0;
BA_ "GenSigStartValue" SG_ 258 ASR_Systemstatus 2;
BA_ "GenSigSwitchedByIgnition" SG_ 258 ASR_Systemstatus 0;
BA_ "GenSigSendType" SG_ 258 ECD_Bremslicht 0;
BA_ "GenSigSwitchedByIgnition" SG_ 258 ECD_Bremslicht 0;
BA_ "GenSigSendType" SG_ 258 ECD_Fehler 0;
BA_ "GenSigSwitchedByIgnition" SG_ 258 ECD_Fehler 0;
BA_ "GenSigSendType" SG_ 258 ECD_nicht_verfuegbar 0;
BA_ "GenSigStartValue" SG_ 258 ECD_nicht_verfuegbar 1;
BA_ "GenSigSwitchedByIgnition" SG_ 258 ECD_nicht_verfuegbar 0;
BA_ "GenSigSendType" SG_ 258 EPB_DAA_Randbed_erf 0;
BA_ "GenSigSwitchedByIgnition" SG_ 258 EPB_DAA_Randbed_erf 0;
BA_ "GenSigSendType" SG_ 258 EPB_Fehlerstatus_02 0;
BA_ "GenSigSwitchedByIgnition" SG_ 258 EPB_Fehlerstatus_02 0;
BA_ "GenSigSendType" SG_ 258 EPB_Freig_Verzoeg_Anf 0;
BA_ "GenSigSwitchedByIgnition" SG_ 258 EPB_Freig_Verzoeg_Anf 0;
BA_ "GenSigSendType" SG_ 258 EPB_Pedalweg_Kuppl 0;
BA_ "GenSigSwitchedByIgnition" SG_ 258 EPB_Pedalweg_Kuppl 0;
BA_ "Fehlerwert" SG_ 258 EPB_Pedalweg_Kuppl 255;
BA_ "GenSigSendType" SG_ 258 EPB_QBit_Pedalweg_Kuppl 0;
BA_ "GenSigStartValue" SG_ 258 EPB_QBit_Pedalweg_Kuppl 1;
BA_ "GenSigSwitchedByIgnition" SG_ 258 EPB_QBit_Pedalweg_Kuppl 0;
BA_ "GenSigSendType" SG_ 258 EPB_QBit_Schalterpos 0;
BA_ "GenSigStartValue" SG_ 258 EPB_QBit_Schalterpos 1;
BA_ "GenSigSwitchedByIgnition" SG_ 258 EPB_QBit_Schalterpos 0;
BA_ "GenSigSendType" SG_ 258 EPB_Schalterposition 0;
BA_ "GenSigSwitchedByIgnition" SG_ 258 EPB_Schalterposition 0;
BA_ "Fehlerwert" SG_ 258 EPB_Schalterposition 3;
BA_ "GenSigSendType" SG_ 258 EPB_Spannkraft 0;
BA_ "GenSigStartValue" SG_ 258 EPB_Spannkraft 30;
BA_ "GenSigSwitchedByIgnition" SG_ 258 EPB_Spannkraft 0;
BA_ "Fehlerwert" SG_ 258 EPB_Spannkraft 31;
BA_ "GenSigSendType" SG_ 258 EPB_Status 0;
BA_ "GenSigSwitchedByIgnition" SG_ 258 EPB_Status 0;
BA_ "GenSigSendType" SG_ 258 EPB_Status_02 0;
BA_ "GenSigStartValue" SG_ 258 EPB_Status_02 6;
BA_ "GenSigSwitchedByIgnition" SG_ 258 EPB_Status_02 0;
BA_ "GenSigSendType" SG_ 258 EPB_Verzoeg_Anf 0;
BA_ "GenSigStartValue" SG_ 258 EPB_Verzoeg_Anf 166;
BA_ "GenSigSwitchedByIgnition" SG_ 258 EPB_Verzoeg_Anf 0;
BA_ "GenSigSendType" SG_ 258 ESC_50_BZ 0;
BA_ "GenSigFuncType" SG_ 258 ESC_50_BZ 1;
BA_ "GenSigSwitchedByIgnition" SG_ 258 ESC_50_BZ 0;
BA_ "GenSigSendType" SG_ 258 ESC_50_CRC 0;
BA_ "GenSigFuncType" SG_ 258 ESC_50_CRC 2;
BA_ "GenSigSwitchedByIgnition" SG_ 258 ESC_50_CRC 0;
BA_ "GenSigSendType" SG_ 258 ESC_Bremsdruckgradient 0;
BA_ "GenSigStartValue" SG_ 258 ESC_Bremsdruckgradient 254;
BA_ "GenSigSwitchedByIgnition" SG_ 258 ESC_Bremsdruckgradient 0;
BA_ "Fehlerwert" SG_ 258 ESC_Bremsdruckgradient 255;
BA_ "GenSigSendType" SG_ 258 ESC_Fahrerbremswunsch 0;
BA_ "GenSigStartValue" SG_ 258 ESC_Fahrerbremswunsch 100;
BA_ "GenSigSwitchedByIgnition" SG_ 258 ESC_Fahrerbremswunsch 0;
BA_ "Fehlerwert" SG_ 258 ESC_Fahrerbremswunsch 1023;
BA_ "GenSigSendType" SG_ 258 ESC_Fahrerradbremswunschmoment 0;
BA_ "Fehlerwert" SG_ 258 ESC_Fahrerradbremswunschmoment 4095;
BA_ "GenSigSendType" SG_ 258 ESC_Hydr_Fkt_aktiv 0;
BA_ "GenSigSwitchedByIgnition" SG_ 258 ESC_Hydr_Fkt_aktiv 0;
BA_ "GenSigSendType" SG_ 258 ESC_Motorstartverzoegerung 0;
BA_ "GenSigSwitchedByIgnition" SG_ 258 ESC_Motorstartverzoegerung 0;
BA_ "GenSigSendType" SG_ 258 ESC_QBit_Fahrerbremswunsch 0;
BA_ "GenSigStartValue" SG_ 258 ESC_QBit_Fahrerbremswunsch 1;
BA_ "GenSigSwitchedByIgnition" SG_ 258 ESC_QBit_Fahrerbremswunsch 0;
BA_ "GenSigSendType" SG_ 258 ESC_Raddruck_max 0;
BA_ "GenSigStartValue" SG_ 258 ESC_Raddruck_max 254;
BA_ "GenSigSwitchedByIgnition" SG_ 258 ESC_Raddruck_max 0;
BA_ "Fehlerwert" SG_ 258 ESC_Raddruck_max 255;
BA_ "GenSigSendType" SG_ 258 ESC_SeitenwindAssistent_Eingriff 0;
BA_ "GenSigSwitchedByIgnition" SG_ 258 ESC_SeitenwindAssistent_Eingriff 0;
BA_ "GenSigSendType" SG_ 258 ESC_Unterdruckmangel_erkannt 0;
BA_ "GenSigSwitchedByIgnition" SG_ 258 ESC_Unterdruckmangel_erkannt 0;
BA_ "GenSigSendType" SG_ 258 ESCGeneratorSollMoment 0;
BA_ "GenSigStartValue" SG_ 258 ESCGeneratorSollMoment 4094;
BA_ "GenSigSwitchedByIgnition" SG_ 258 ESCGeneratorSollMoment 0;
BA_ "Fehlerwert" SG_ 258 ESCGeneratorSollMoment 4095;
BA_ "GenSigSendType" SG_ 258 ESP_Abrutschen_Stillstand 0;
BA_ "GenSigSwitchedByIgnition" SG_ 258 ESP_Abrutschen_Stillstand 0;
BA_ "GenSigSendType" SG_ 258 ESP_ANB_CM_Rueckk_Umsetz 0;
BA_ "GenSigSwitchedByIgnition" SG_ 258 ESP_ANB_CM_Rueckk_Umsetz 0;
BA_ "GenSigSendType" SG_ 258 ESP_Anforderung_EPB 0;
BA_ "GenSigSwitchedByIgnition" SG_ 258 ESP_Anforderung_EPB 0;
BA_ "GenSigSendType" SG_ 258 ESP_Anschleppstart_Freigabe 0;
BA_ "GenSigSwitchedByIgnition" SG_ 258 ESP_Anschleppstart_Freigabe 0;
BA_ "GenSigSendType" SG_ 258 ESP_Autohold_aktiv 0;
BA_ "GenSigSwitchedByIgnition" SG_ 258 ESP_Autohold_aktiv 0;
BA_ "GenSigSendType" SG_ 258 ESP_Autohold_Standby 0;
BA_ "GenSigSwitchedByIgnition" SG_ 258 ESP_Autohold_Standby 0;
BA_ "GenSigSendType" SG_ 258 ESP_BKV_Unterdruck 0;
BA_ "GenSigStartValue" SG_ 258 ESP_BKV_Unterdruck 254;
BA_ "GenSigSwitchedByIgnition" SG_ 258 ESP_BKV_Unterdruck 0;
BA_ "Fehlerwert" SG_ 258 ESP_BKV_Unterdruck 255;
BA_ "GenSigSendType" SG_ 258 ESP_Bremsdruck 0;
BA_ "GenSigStartValue" SG_ 258 ESP_Bremsdruck 100;
BA_ "GenSigSwitchedByIgnition" SG_ 258 ESP_Bremsdruck 0;
BA_ "Fehlerwert" SG_ 258 ESP_Bremsdruck 1023;
BA_ "GenSigSendType" SG_ 258 ESP_Bremsruck_AWV2 0;
BA_ "GenSigSwitchedByIgnition" SG_ 258 ESP_Bremsruck_AWV2 0;
BA_ "GenSigSendType" SG_ 258 ESP_Eingr_HL 0;
BA_ "GenSigSwitchedByIgnition" SG_ 258 ESP_Eingr_HL 0;
BA_ "GenSigSendType" SG_ 258 ESP_Eingr_HR 0;
BA_ "GenSigSwitchedByIgnition" SG_ 258 ESP_Eingr_HR 0;
BA_ "GenSigSendType" SG_ 258 ESP_Eingr_VL 0;
BA_ "GenSigSwitchedByIgnition" SG_ 258 ESP_Eingr_VL 0;
BA_ "GenSigSendType" SG_ 258 ESP_Eingr_VR 0;
BA_ "GenSigSwitchedByIgnition" SG_ 258 ESP_Eingr_VR 0;
BA_ "GenSigSendType" SG_ 258 ESP_Fahrer_bremst 0;
BA_ "GenSigSwitchedByIgnition" SG_ 258 ESP_Fahrer_bremst 0;
BA_ "GenSigSendType" SG_ 258 ESP_Fahrer_tritt_ZBR_Schw 0;
BA_ "GenSigSwitchedByIgnition" SG_ 258 ESP_Fahrer_tritt_ZBR_Schw 0;
BA_ "GenSigSendType" SG_ 258 ESP_FStatus_Anfahrhilfe 0;
BA_ "GenSigSwitchedByIgnition" SG_ 258 ESP_FStatus_Anfahrhilfe 0;
BA_ "Fehlerwert" SG_ 258 ESP_FStatus_Anfahrhilfe 1;
BA_ "GenSigSendType" SG_ 258 ESP_Gierrate 0;
BA_ "GenSigSwitchedByIgnition" SG_ 258 ESP_Gierrate 0;
BA_ "Fehlerwert" SG_ 258 ESP_Gierrate 16383;
BA_ "GenSigSendType" SG_ 258 ESP_HBA_aktiv 0;
BA_ "GenSigSwitchedByIgnition" SG_ 258 ESP_HBA_aktiv 0;
BA_ "GenSigSendType" SG_ 258 ESP_HBA_Empfindlichkeit 0;
BA_ "GenSigSwitchedByIgnition" SG_ 258 ESP_HBA_Empfindlichkeit 0;
BA_ "Fehlerwert" SG_ 258 ESP_HBA_Empfindlichkeit 7;
BA_ "GenSigSendType" SG_ 258 ESP_HDC_aktiv 0;
BA_ "GenSigSwitchedByIgnition" SG_ 258 ESP_HDC_aktiv 0;
BA_ "GenSigSendType" SG_ 258 ESP_HDC_Standby 0;
BA_ "GenSigSwitchedByIgnition" SG_ 258 ESP_HDC_Standby 0;
BA_ "GenSigSendType" SG_ 258 ESP_Konsistenz_ACC_Botschaft 0;
BA_ "GenSigSwitchedByIgnition" SG_ 258 ESP_Konsistenz_ACC_Botschaft 0;
BA_ "GenSigSendType" SG_ 258 ESP_Konsistenz_AWV2 0;
BA_ "GenSigSwitchedByIgnition" SG_ 258 ESP_Konsistenz_AWV2 0;
BA_ "GenSigSendType" SG_ 258 ESP_Konsistenz_TSK 0;
BA_ "GenSigSwitchedByIgnition" SG_ 258 ESP_Konsistenz_TSK 0;
BA_ "GenSigSendType" SG_ 258 ESP_Laengsbeschl 0;
BA_ "GenSigStartValue" SG_ 258 ESP_Laengsbeschl 512;
BA_ "GenSigSwitchedByIgnition" SG_ 258 ESP_Laengsbeschl 0;
BA_ "Fehlerwert" SG_ 258 ESP_Laengsbeschl 1023;
BA_ "GenSigSendType" SG_ 258 ESP_Lenkeingriff_ADS 0;
BA_ "GenSigSwitchedByIgnition" SG_ 258 ESP_Lenkeingriff_ADS 0;
BA_ "GenSigSendType" SG_ 258 ESP_Notbremsanzeige 0;
BA_ "GenSigSwitchedByIgnition" SG_ 258 ESP_Notbremsanzeige 0;
BA_ "GenSigSendType" SG_ 258 ESP_PLA_Abbruch 0;
BA_ "GenSigSwitchedByIgnition" SG_ 258 ESP_PLA_Abbruch 0;
BA_ "GenSigSendType" SG_ 258 ESP_Prefill_ausgeloest 0;
BA_ "GenSigSwitchedByIgnition" SG_ 258 ESP_Prefill_ausgeloest 0;
BA_ "GenSigSendType" SG_ 258 ESP_QBit_Bremsdruck 0;
BA_ "GenSigStartValue" SG_ 258 ESP_QBit_Bremsdruck 1;
BA_ "GenSigSwitchedByIgnition" SG_ 258 ESP_QBit_Bremsdruck 0;
BA_ "GenSigSendType" SG_ 258 ESP_QBit_Fahrer_bremst 0;
BA_ "GenSigStartValue" SG_ 258 ESP_QBit_Fahrer_bremst 1;
BA_ "GenSigSwitchedByIgnition" SG_ 258 ESP_QBit_Fahrer_bremst 0;
BA_ "GenSigSendType" SG_ 258 ESP_QBit_Gierrate 0;
BA_ "GenSigStartValue" SG_ 258 ESP_QBit_Gierrate 1;
BA_ "GenSigSwitchedByIgnition" SG_ 258 ESP_QBit_Gierrate 0;
BA_ "GenSigSendType" SG_ 258 ESP_QBit_Laengsbeschl 0;
BA_ "GenSigStartValue" SG_ 258 ESP_QBit_Laengsbeschl 1;
BA_ "GenSigSwitchedByIgnition" SG_ 258 ESP_QBit_Laengsbeschl 0;
BA_ "GenSigSendType" SG_ 258 ESP_QBit_Querb 0;
BA_ "GenSigStartValue" SG_ 258 ESP_QBit_Querb 1;
BA_ "GenSigSwitchedByIgnition" SG_ 258 ESP_QBit_Querb 0;
BA_ "GenSigSendType" SG_ 258 ESP_QBit_v_ref 0;
BA_ "GenSigStartValue" SG_ 258 ESP_QBit_v_ref 1;
BA_ "GenSigSwitchedByIgnition" SG_ 258 ESP_QBit_v_ref 0;
BA_ "GenSigSendType" SG_ 258 ESP_Querbeschleunigung 0;
BA_ "GenSigStartValue" SG_ 258 ESP_Querbeschleunigung 127;
BA_ "GenSigSwitchedByIgnition" SG_ 258 ESP_Querbeschleunigung 0;
BA_ "Fehlerwert" SG_ 258 ESP_Querbeschleunigung 255;
BA_ "GenSigSendType" SG_ 258 ESP_Rueckwaertsfahrt_erkannt 0;
BA_ "GenSigSwitchedByIgnition" SG_ 258 ESP_Rueckwaertsfahrt_erkannt 0;
BA_ "GenSigSendType" SG_ 258 ESP_Schwelle_Unterdruck 0;
BA_ "GenSigSwitchedByIgnition" SG_ 258 ESP_Schwelle_Unterdruck 0;
BA_ "GenSigSendType" SG_ 258 ESP_SpannungsAnf 0;
BA_ "GenSigSwitchedByIgnition" SG_ 258 ESP_SpannungsAnf 0;
BA_ "GenSigSendType" SG_ 258 ESP_StartStopp_Info 0;
BA_ "GenSigSwitchedByIgnition" SG_ 258 ESP_StartStopp_Info 0;
BA_ "GenSigSendType" SG_ 258 ESP_Status_Anfahrhilfe 0;
BA_ "GenSigSwitchedByIgnition" SG_ 258 ESP_Status_Anfahrhilfe 0;
BA_ "GenSigSendType" SG_ 258 ESP_Status_Bremsdruck 0;
BA_ "GenSigSwitchedByIgnition" SG_ 258 ESP_Status_Bremsdruck 0;
BA_ "GenSigSendType" SG_ 258 ESP_Status_Bremsentemp 0;
BA_ "GenSigSwitchedByIgnition" SG_ 258 ESP_Status_Bremsentemp 0;
BA_ "GenSigSendType" SG_ 258 ESP_Status_Bremsentemp_02 0;
BA_ "GenSigSwitchedByIgnition" SG_ 258 ESP_Status_Bremsentemp_02 0;
BA_ "GenSigSendType" SG_ 258 ESP_Status_ESP_PLA 0;
BA_ "GenSigSwitchedByIgnition" SG_ 258 ESP_Status_ESP_PLA 0;
BA_ "GenSigSendType" SG_ 258 ESP_Stillstandsphase_erschoepft 0;
BA_ "GenSigSwitchedByIgnition" SG_ 258 ESP_Stillstandsphase_erschoepft 0;
BA_ "GenSigSendType" SG_ 258 ESP_Systemstatus_03 0;
BA_ "GenSigStartValue" SG_ 258 ESP_Systemstatus_03 2;
BA_ "GenSigSwitchedByIgnition" SG_ 258 ESP_Systemstatus_03 0;
BA_ "Fehlerwert" SG_ 258 ESP_Systemstatus_03 3;
BA_ "GenSigSendType" SG_ 258 ESP_Tuerkontakt_Fahrertuer 0;
BA_ "GenSigSwitchedByIgnition" SG_ 258 ESP_Tuerkontakt_Fahrertuer 0;
BA_ "GenSigSendType" SG_ 258 ESP_v_ref 0;
BA_ "GenSigStartValue" SG_ 258 ESP_v_ref 4094;
BA_ "GenSigSwitchedByIgnition" SG_ 258 ESP_v_ref 0;
BA_ "Fehlerwert" SG_ 258 ESP_v_ref 4095;
BA_ "GenSigSendType" SG_ 258 ESP_v_ref_Fahrtrichtung 0;
BA_ "GenSigSwitchedByIgnition" SG_ 258 ESP_v_ref_Fahrtrichtung 0;
BA_ "GenSigSendType" SG_ 258 ESP_Verz_EPB_aktiv 0;
BA_ "GenSigSwitchedByIgnition" SG_ 258 ESP_Verz_EPB_aktiv 0;
BA_ "GenSigSendType" SG_ 258 ESP_Verz_TSK_aktiv 0;
BA_ "GenSigSwitchedByIgnition" SG_ 258 ESP_Verz_TSK_aktiv 0;
BA_ "GenSigSendType" SG_ 258 ESP_Verzoeg_EPB_verf 0;
BA_ "GenSigSwitchedByIgnition" SG_ 258 ESP_Verzoeg_EPB_verf 0;
BA_ "GenSigSendType" SG_ 258 ESP_VZ_Gierrate 0;
BA_ "GenSigSwitchedByIgnition" SG_ 258 ESP_VZ_Gierrate 0;
BA_ "GenSigSendType" SG_ 258 ESP_ZT_Rueckk_Umsetz 0;
BA_ "GenSigSwitchedByIgnition" SG_ 258 ESP_ZT_Rueckk_Umsetz 0;
BA_ "GenSigSendType" SG_ 258 SOK_ESC_50_Signatur 0;
BA_ "GenSigFuncType" SG_ 258 SOK_ESC_50_Signatur 15;
BA_ "GenSigSwitchedByIgnition" SG_ 258 SOK_ESC_50_Signatur 0;
BA_REL_ "GenSigTimeoutTime" BU_SG_REL_ BCM SG_ 496 EA_02_CRC 5000;
BA_REL_ "GenSigTimeoutTime" BU_SG_REL_ BCM SG_ 496 EA_02_BZ 5000;
BA_REL_ "GenSigTimeoutTime" BU_SG_REL_ BCM SG_ 496 EA_Fahrzeughupe_Anf 5000;
BA_REL_ "GenSigTimeoutTime" BU_SG_REL_ BCM SG_ 496 EA_Tueren_Anf 5000;
BA_REL_ "GenSigTimeoutTime" BU_SG_REL_ BCM SG_ 496 EA_Innenraumlicht_Anf 5000;
BA_REL_ "GenSigTimeoutTime" BU_SG_REL_ BCM SG_ 496 EA_Bremslichtblinken 5000;
BA_REL_ "GenSigTimeoutTime" BU_SG_REL_ BCM SG_ 496 EA_Blinken 5000;
BA_REL_ "GenSigTimeoutTime" BU_SG_REL_ BCM SG_ 1603 KBI_Einheit_Uhrzeit 5000;
BA_REL_ "GenSigTimeoutTime" BU_SG_REL_ BCM SG_ 1603 KBI_Einheit_Tacho 5000;
BA_REL_ "GenSigTimeoutTime" BU_SG_REL_ BCM SG_ 1622 ELV_01_CRC 5000;
BA_REL_ "GenSigTimeoutTime" BU_SG_REL_ BCM SG_ 1622 ELV_01_BZ 5000;
BA_REL_ "GenSigTimeoutTime" BU_SG_REL_ BCM SG_ 1622 ELV_Verriegelt 5000;
BA_REL_ "GenSigTimeoutTime" BU_SG_REL_ BCM SG_ 1622 ELV_Entriegelt 5000;
BA_REL_ "GenSigTimeoutTime" BU_SG_REL_ BCM SG_ 1622 ELV_Klemmenfreigabe 5000;
BA_REL_ "GenSigTimeoutTime" BU_SG_REL_ BCM SG_ 1622 ELV_Abbruch_Anf_Klemmenfreigabe 5000;
BA_REL_ "GenSigTimeoutTime" BU_SG_REL_ BCM SG_ 184 EM1_Sperr_Info_WFS 5000;
BA_REL_ "GenSigTimeoutTime" BU_SG_REL_ BCM SG_ 199 EM2_Sperr_Info_WFS 5000;
BA_REL_ "GenSigTimeoutTime" BU_SG_REL_ BCM SG_ 624 EmpfSTSG_HBFS_TIG_bet_oeffnen 1000;
BA_REL_ "GenSigTimeoutTime" BU_SG_REL_ BCM SG_ 623 EmpfSTSG_HFS_TIG_bet_oeffnen 1000;
BA_REL_ "GenSigTimeoutTime" BU_SG_REL_ BCM SG_ 258 ESC_50_CRC 500;
BA_REL_ "GenSigTimeoutTime" BU_SG_REL_ BCM SG_ 258 ESC_50_BZ 500;
BA_REL_ "GenSigTimeoutTime" BU_SG_REL_ BCM SG_ 258 ESP_QBit_Laengsbeschl 500;
BA_REL_ "GenSigTimeoutTime" BU_SG_REL_ BCM SG_ 258 ESP_Querbeschleunigung 500;
BA_REL_ "GenSigTimeoutTime" BU_SG_REL_ BCM SG_ 258 ESP_Laengsbeschl 500;
BA_REL_ "GenSigTimeoutTime" BU_SG_REL_ BCM SG_ 258 ESP_Notbremsanzeige 500;
BA_REL_ "GenSigTimeoutTime" BU_SG_REL_ BCM SG_ 258 ESP_QBit_Fahrer_bremst 500;
BA_REL_ "GenSigTimeoutTime" BU_SG_REL_ BCM SG_ 258 ESP_Fahrer_bremst 500;
BA_REL_ "GenSigTimeoutTime" BU_SG_REL_ BCM SG_ 258 ECD_Bremslicht 500;
BA_REL_ "GenSigTimeoutTime" BU_SG_REL_ BCM SG_ 258 EPB_Schalterposition 500;
BA_REL_ "GenSigTimeoutTime" BU_SG_REL_ BCM SG_ 258 EPB_QBit_Schalterpos 500;
BA_REL_ "GenSigTimeoutTime" BU_SG_REL_ BCM SG_ 258 EPB_Status_02 500;
BA_REL_ "GenSigTimeoutTime" BU_SG_REL_ BCM SG_ 258 EPB_Status 500;
BA_REL_ "GenSigTimeoutTime" BU_SG_REL_ Gateway_Max SG_ 2331595989 DIST_DKmtg 500;
BA_REL_ "GenSigTimeoutTime" BU_SG_REL_ Gateway_Max SG_ 2589283751 KBI_Kilometerstand_HiRes_meter 5000;
BA_REL_ "GenSigTimeoutTime" BU_SG_REL_ TSGGen3_BFS SG_ 2463978735 DoorFunctions_HBFS_01_CRC 1000;
BA_REL_ "GenSigTimeoutTime" BU_SG_REL_ TSGGen3_BFS SG_ 2463978735 DoorFunctions_HBFS_01_BZ 1000;
BA_REL_ "GenSigTimeoutTime" BU_SG_REL_ TSGGen3_BFS SG_ 2463978735 HBFS_FH_S_HFS_ManHoch 1000;
BA_REL_ "GenSigTimeoutTime" BU_SG_REL_ TSGGen3_BFS SG_ 2463978735 HBFS_FH_S_HFS_ManTief 1000;
BA_REL_ "GenSigTimeoutTime" BU_SG_REL_ TSGGen3_BFS SG_ 2463978735 HBFS_SAD_Schalter 1000;
BA_REL_ "GenSigTimeoutTime" BU_SG_REL_ TSGGen3_BFS SG_ 2463978735 HBFS_FH_Bew_hoch 1000;
BA_REL_ "GenSigTimeoutTime" BU_SG_REL_ TSGGen3_BFS SG_ 2463978735 HBFS_FH_Bew_tief 1000;
BA_REL_ "GenSigTimeoutTime" BU_SG_REL_ TSGGen3_BFS SG_ 2463978735 HBFS_Status_KiSi 1000;
BA_REL_ "GenSigTimeoutTime" BU_SG_REL_ TSGGen3_BFS SG_ 2463978735 HBFS_Oben_Block_erw 1000;
BA_REL_ "GenSigTimeoutTime" BU_SG_REL_ TSGGen3_BFS SG_ 2463978735 HBFS_Unten_Block_erw 1000;
BA_REL_ "GenSigTimeoutTime" BU_SG_REL_ TSGGen3_BFS SG_ 2463978735 HBFS_MRollo_Schalter 1000;
BA_REL_ "GenSigTimeoutTime" BU_SG_REL_ TSGGen3_BFS SG_ 2463978735 HBFS_Status_KiSi_inv 1000;
BA_REL_ "GenSigTimeoutTime" BU_SG_REL_ TSGGen3_BFS SG_ 2463978735 HBFS_TCR_Mode_aktiv 1000;
BA_REL_ "GenSigTimeoutTime" BU_SG_REL_ TSGGen3_BFS SG_ 2463978735 SSA_HBFT_ASW_Status 1000;
BA_REL_ "GenSigTimeoutTime" BU_SG_REL_ TSGGen3_BFS SG_ 2463978735 HBFS_Tuer_geoeffnet 1000;
BA_REL_ "GenSigTimeoutTime" BU_SG_REL_ TSGGen3_BFS SG_ 2463978735 HBFS_Tuerschloss_defekt 1000;
BA_REL_ "GenSigTimeoutTime" BU_SG_REL_ TSGGen3_BFS SG_ 2463978735 HBFS_FH_S_HFS_AutoHoch 1000;
BA_REL_ "GenSigTimeoutTime" BU_SG_REL_ TSGGen3_BFS SG_ 2463978735 HBFS_FH_S_HFS_AutoTief 1000;
BA_REL_ "GenSigTimeoutTime" BU_SG_REL_ TSGGen3_BFS SG_ 2463978736 DoorFunctions_HFS_01_CRC 1000;
BA_REL_ "GenSigTimeoutTime" BU_SG_REL_ TSGGen3_BFS SG_ 2463978736 DoorFunctions_HFS_01_BZ 1000;
BA_REL_ "GenSigTimeoutTime" BU_SG_REL_ TSGGen3_BFS SG_ 2463978736 HFS_FH_S_HBFS_ManHoch 1000;
BA_REL_ "GenSigTimeoutTime" BU_SG_REL_ TSGGen3_BFS SG_ 2463978736 HFS_FH_S_HBFS_ManTief 1000;
BA_REL_ "GenSigTimeoutTime" BU_SG_REL_ TSGGen3_BFS SG_ 2463978736 HFS_FH_Bew_hoch 1000;
BA_REL_ "GenSigTimeoutTime" BU_SG_REL_ TSGGen3_BFS SG_ 2463978736 HFS_FH_Bew_tief 1000;
BA_REL_ "GenSigTimeoutTime" BU_SG_REL_ TSGGen3_BFS SG_ 2463978736 HFS_FH_normiert 1000;
BA_REL_ "GenSigTimeoutTime" BU_SG_REL_ TSGGen3_BFS SG_ 2463978736 HFS_Status_KiSi 1000;
BA_REL_ "GenSigTimeoutTime" BU_SG_REL_ TSGGen3_BFS SG_ 2463978736 SSR_HFS_Pos_Unten 1000;
BA_REL_ "GenSigTimeoutTime" BU_SG_REL_ TSGGen3_BFS SG_ 2463978736 HFS_Oben_Block_erw 1000;
BA_REL_ "GenSigTimeoutTime" BU_SG_REL_ TSGGen3_BFS SG_ 2463978736 HFS_Unten_Block_erw 1000;
BA_REL_ "GenSigTimeoutTime" BU_SG_REL_ TSGGen3_BFS SG_ 2463978736 HFS_Status_eTAG 1000;
BA_REL_ "GenSigTimeoutTime" BU_SG_REL_ TSGGen3_BFS SG_ 2463978736 HFS_TCR_Mode_aktiv 1000;
BA_REL_ "GenSigTimeoutTime" BU_SG_REL_ TSGGen3_BFS SG_ 2463978736 HFS_Tuer_geoeffnet 1000;
BA_REL_ "GenSigTimeoutTime" BU_SG_REL_ TSGGen3_BFS SG_ 2463978736 HFS_gesafet 1000;
BA_REL_ "GenSigTimeoutTime" BU_SG_REL_ TSGGen3_BFS SG_ 2463978736 HFS_Tuerschloss_defekt 1000;
BA_REL_ "GenSigTimeoutTime" BU_SG_REL_ TSGGen3_BFS SG_ 2463978736 HFS_FH_S_HBFS_AutoHoch 1000;
BA_REL_ "GenSigTimeoutTime" BU_SG_REL_ TSGGen3_BFS SG_ 2463978736 HFS_FH_S_HBFS_AutoTief 1000;
BA_REL_ "GenSigTimeoutTime" BU_SG_REL_ TSGGen3_BFS SG_ 2463978736 HFS_ASW_Warnton 1000;
BA_REL_ "GenSigTimeoutTime" BU_SG_REL_ TSGGen3_BFS SG_ 624 EmpfEinheit_STSG_HBFS_01_CRC 1000;
BA_REL_ "GenSigTimeoutTime" BU_SG_REL_ TSGGen3_BFS SG_ 624 EmpfEinheit_STSG_HBFS_01_BZ 1000;
BA_REL_ "GenSigTimeoutTime" BU_SG_REL_ TSGGen3_BFS SG_ 624 EmpfSTSG_HBFS_Status_KiSi 1000;
BA_REL_ "GenSigTimeoutTime" BU_SG_REL_ TSGGen3_BFS SG_ 624 EmpfSTSG_HBFS_KiSi_Fehler 1000;
BA_REL_ "GenSigTimeoutTime" BU_SG_REL_ TSGGen3_BFS SG_ 623 EmpfEinheit_STSG_HFS_01_CRC 1000;
BA_REL_ "GenSigTimeoutTime" BU_SG_REL_ TSGGen3_BFS SG_ 623 EmpfEinheit_STSG_HFS_01_BZ 1000;
BA_REL_ "GenSigTimeoutTime" BU_SG_REL_ TSGGen3_BFS SG_ 623 EmpfSTSG_HFS_Status_KiSi 1000;
BA_REL_ "GenSigTimeoutTime" BU_SG_REL_ TSGGen3_BFS SG_ 623 EmpfSTSG_HFS_KiSi_Fehler 1000;
BA_REL_ "GenSigTimeoutTime" BU_SG_REL_ TSGGen3_BFS SG_ 258 ESP_Querbeschleunigung 500;
BA_REL_ "GenSigTimeoutTime" BU_SG_REL_ TSGGen3_BFS SG_ 258 ESP_Laengsbeschl 500;
BA_REL_ "GenSigTimeoutTime" BU_SG_REL_ TSGGen3_BFS SG_ 258 ESP_Gierrate 500;
BA_REL_ "GenSigTimeoutTime" BU_SG_REL_ TSGGen3_FS SG_ 2463978735 DoorFunctions_HBFS_01_CRC 1000;
BA_REL_ "GenSigTimeoutTime" BU_SG_REL_ TSGGen3_FS SG_ 2463978735 DoorFunctions_HBFS_01_BZ 1000;
BA_REL_ "GenSigTimeoutTime" BU_SG_REL_ TSGGen3_FS SG_ 2463978735 HBFS_FH_S_HFS_ManHoch 1000;
BA_REL_ "GenSigTimeoutTime" BU_SG_REL_ TSGGen3_FS SG_ 2463978735 HBFS_FH_S_HFS_ManTief 1000;
BA_REL_ "GenSigTimeoutTime" BU_SG_REL_ TSGGen3_FS SG_ 2463978735 HBFS_Tuer_Status 1000;
BA_REL_ "GenSigTimeoutTime" BU_SG_REL_ TSGGen3_FS SG_ 2463978735 HBFS_FH_Bew_hoch 1000;
BA_REL_ "GenSigTimeoutTime" BU_SG_REL_ TSGGen3_FS SG_ 2463978735 HBFS_FH_Bew_tief 1000;
BA_REL_ "GenSigTimeoutTime" BU_SG_REL_ TSGGen3_FS SG_ 2463978735 HBFS_FH_normiert 1000;
BA_REL_ "GenSigTimeoutTime" BU_SG_REL_ TSGGen3_FS SG_ 2463978735 HBFS_Status_KiSi 1000;
BA_REL_ "GenSigTimeoutTime" BU_SG_REL_ TSGGen3_FS SG_ 2463978735 HBFS_Oben_Block_erw 1000;
BA_REL_ "GenSigTimeoutTime" BU_SG_REL_ TSGGen3_FS SG_ 2463978735 HBFS_Unten_Block_erw 1000;
BA_REL_ "GenSigTimeoutTime" BU_SG_REL_ TSGGen3_FS SG_ 2463978735 HBFS_Status_KiSi_inv 1000;
BA_REL_ "GenSigTimeoutTime" BU_SG_REL_ TSGGen3_FS SG_ 2463978735 HBFS_Status_eTAG 1000;
BA_REL_ "GenSigTimeoutTime" BU_SG_REL_ TSGGen3_FS SG_ 2463978735 HBFS_Tuer_Status_QBit 1000;
BA_REL_ "GenSigTimeoutTime" BU_SG_REL_ TSGGen3_FS SG_ 2463978735 HBFS_KiSi_Fehler 1000;
BA_REL_ "GenSigTimeoutTime" BU_SG_REL_ TSGGen3_FS SG_ 2463978735 HBFS_TCR_Mode_aktiv 1000;
BA_REL_ "GenSigTimeoutTime" BU_SG_REL_ TSGGen3_FS SG_ 2463978735 HBFS_Tuer_geoeffnet 1000;
BA_REL_ "GenSigTimeoutTime" BU_SG_REL_ TSGGen3_FS SG_ 2463978735 HBFS_verriegelt 1000;
BA_REL_ "GenSigTimeoutTime" BU_SG_REL_ TSGGen3_FS SG_ 2463978735 HBFS_gesafet 1000;
BA_REL_ "GenSigTimeoutTime" BU_SG_REL_ TSGGen3_FS SG_ 2463978735 HBFS_Tuerschloss_defekt 1000;
BA_REL_ "GenSigTimeoutTime" BU_SG_REL_ TSGGen3_FS SG_ 2463978735 HBFS_FH_S_HFS_AutoHoch 1000;
BA_REL_ "GenSigTimeoutTime" BU_SG_REL_ TSGGen3_FS SG_ 2463978735 HBFS_FH_S_HFS_AutoTief 1000;
BA_REL_ "GenSigTimeoutTime" BU_SG_REL_ TSGGen3_FS SG_ 2463978735 SSA_HBFT_FH_Oeffnungsweite 1000;
BA_REL_ "GenSigTimeoutTime" BU_SG_REL_ TSGGen3_FS SG_ 2463978735 HBFS_ASW_HMI_defekt 1000;
BA_REL_ "GenSigTimeoutTime" BU_SG_REL_ TSGGen3_FS SG_ 2463978736 DoorFunctions_HFS_01_CRC 1000;
BA_REL_ "GenSigTimeoutTime" BU_SG_REL_ TSGGen3_FS SG_ 2463978736 DoorFunctions_HFS_01_BZ 1000;
BA_REL_ "GenSigTimeoutTime" BU_SG_REL_ TSGGen3_FS SG_ 2463978736 HFS_FH_S_HBFS_ManHoch 1000;
BA_REL_ "GenSigTimeoutTime" BU_SG_REL_ TSGGen3_FS SG_ 2463978736 HFS_FH_S_HBFS_ManTief 1000;
BA_REL_ "GenSigTimeoutTime" BU_SG_REL_ TSGGen3_FS SG_ 2463978736 HFS_Tuer_Status 1000;
BA_REL_ "GenSigTimeoutTime" BU_SG_REL_ TSGGen3_FS SG_ 2463978736 HFS_FH_Bew_hoch 1000;
BA_REL_ "GenSigTimeoutTime" BU_SG_REL_ TSGGen3_FS SG_ 2463978736 HFS_FH_Bew_tief 1000;
BA_REL_ "GenSigTimeoutTime" BU_SG_REL_ TSGGen3_FS SG_ 2463978736 HFS_FH_normiert 1000;
BA_REL_ "GenSigTimeoutTime" BU_SG_REL_ TSGGen3_FS SG_ 2463978736 HFS_Status_KiSi 1000;
BA_REL_ "GenSigTimeoutTime" BU_SG_REL_ TSGGen3_FS SG_ 2463978736 HFS_Oben_Block_erw 1000;
BA_REL_ "GenSigTimeoutTime" BU_SG_REL_ TSGGen3_FS SG_ 2463978736 HFS_Unten_Block_erw 1000;
BA_REL_ "GenSigTimeoutTime" BU_SG_REL_ TSGGen3_FS SG_ 2463978736 HFS_Tuer_Status_QBit 1000;
BA_REL_ "GenSigTimeoutTime" BU_SG_REL_ TSGGen3_FS SG_ 2463978736 HFS_TCR_Mode_aktiv 1000;
BA_REL_ "GenSigTimeoutTime" BU_SG_REL_ TSGGen3_FS SG_ 2463978736 SSA_HFT_ASW_Status 1000;
BA_REL_ "GenSigTimeoutTime" BU_SG_REL_ TSGGen3_FS SG_ 2463978736 HFS_Tuer_geoeffnet 1000;
BA_REL_ "GenSigTimeoutTime" BU_SG_REL_ TSGGen3_FS SG_ 2463978736 HFS_verriegelt 1000;
BA_REL_ "GenSigTimeoutTime" BU_SG_REL_ TSGGen3_FS SG_ 2463978736 HFS_Tuerschloss_defekt 1000;
BA_REL_ "GenSigTimeoutTime" BU_SG_REL_ TSGGen3_FS SG_ 2463978736 HFS_FH_S_HBFS_AutoHoch 1000;
BA_REL_ "GenSigTimeoutTime" BU_SG_REL_ TSGGen3_FS SG_ 2463978736 HFS_FH_S_HBFS_AutoTief 1000;
BA_REL_ "GenSigTimeoutTime" BU_SG_REL_ TSGGen3_FS SG_ 2463978736 HFS_KiSi_Fehler 1000;
BA_REL_ "GenSigTimeoutTime" BU_SG_REL_ TSGGen3_FS SG_ 2463978736 HFS_ASW_Warnton 1000;
BA_REL_ "GenSigTimeoutTime" BU_SG_REL_ TSGGen3_FS SG_ 2463978736 HFS_ASW_HMI_defekt 1000;
BA_REL_ "GenSigTimeoutTime" BU_SG_REL_ TSGGen3_FS SG_ 624 EmpfEinheit_STSG_HBFS_01_CRC 1000;
BA_REL_ "GenSigTimeoutTime" BU_SG_REL_ TSGGen3_FS SG_ 624 EmpfEinheit_STSG_HBFS_01_BZ 1000;
BA_REL_ "GenSigTimeoutTime" BU_SG_REL_ TSGGen3_FS SG_ 624 EmpfSTSG_HBFS_Status_KiSi 1000;
BA_REL_ "GenSigTimeoutTime" BU_SG_REL_ TSGGen3_FS SG_ 624 EmpfSTSG_HBFS_KiSi_Fehler 1000;
BA_REL_ "GenSigTimeoutTime" BU_SG_REL_ TSGGen3_FS SG_ 623 EmpfEinheit_STSG_HFS_01_CRC 1000;
BA_REL_ "GenSigTimeoutTime" BU_SG_REL_ TSGGen3_FS SG_ 623 EmpfEinheit_STSG_HFS_01_BZ 1000;
BA_REL_ "GenSigTimeoutTime" BU_SG_REL_ TSGGen3_FS SG_ 623 EmpfSTSG_HFS_Status_KiSi 1000;
BA_REL_ "GenSigTimeoutTime" BU_SG_REL_ TSGGen3_FS SG_ 623 EmpfSTSG_HFS_KiSi_Fehler 1000;
BA_REL_ "GenSigTimeoutTime" BU_SG_REL_ TSGGen3_FS SG_ 258 ESP_Querbeschleunigung 500;
BA_REL_ "GenSigTimeoutTime" BU_SG_REL_ TSGGen3_FS SG_ 258 ESP_Laengsbeschl 500;
BA_REL_ "GenSigTimeoutTime" BU_SG_REL_ TSGGen3_FS SG_ 258 ESP_Gierrate 500;
BA_REL_ "GenSigTimeoutTime" BU_SG_REL_ TSGGen3_HBFS SG_ 2463978736 DoorFunctions_HFS_01_CRC 1000;
BA_REL_ "GenSigTimeoutTime" BU_SG_REL_ TSGGen3_HBFS SG_ 2463978736 DoorFunctions_HFS_01_BZ 1000;
BA_REL_ "GenSigTimeoutTime" BU_SG_REL_ TSGGen3_HBFS SG_ 2463978736 HFS_FH_S_HBFS_ManHoch 1000;
BA_REL_ "GenSigTimeoutTime" BU_SG_REL_ TSGGen3_HBFS SG_ 2463978736 HFS_FH_S_HBFS_ManTief 1000;
BA_REL_ "GenSigTimeoutTime" BU_SG_REL_ TSGGen3_HBFS SG_ 2463978736 HFS_FH_Bew_hoch 1000;
BA_REL_ "GenSigTimeoutTime" BU_SG_REL_ TSGGen3_HBFS SG_ 2463978736 HFS_FH_Bew_tief 1000;
BA_REL_ "GenSigTimeoutTime" BU_SG_REL_ TSGGen3_HBFS SG_ 2463978736 HFS_FH_normiert 1000;
BA_REL_ "GenSigTimeoutTime" BU_SG_REL_ TSGGen3_HBFS SG_ 2463978736 HFS_Status_KiSi 1000;
BA_REL_ "GenSigTimeoutTime" BU_SG_REL_ TSGGen3_HBFS SG_ 2463978736 SSR_HFS_Pos_Unten 1000;
BA_REL_ "GenSigTimeoutTime" BU_SG_REL_ TSGGen3_HBFS SG_ 2463978736 HFS_Oben_Block_erw 1000;
BA_REL_ "GenSigTimeoutTime" BU_SG_REL_ TSGGen3_HBFS SG_ 2463978736 HFS_Unten_Block_erw 1000;
BA_REL_ "GenSigTimeoutTime" BU_SG_REL_ TSGGen3_HBFS SG_ 2463978736 HFS_Status_eTAG 1000;
BA_REL_ "GenSigTimeoutTime" BU_SG_REL_ TSGGen3_HBFS SG_ 2463978736 HFS_TCR_Mode_aktiv 1000;
BA_REL_ "GenSigTimeoutTime" BU_SG_REL_ TSGGen3_HBFS SG_ 2463978736 HFS_Tuer_geoeffnet 1000;
BA_REL_ "GenSigTimeoutTime" BU_SG_REL_ TSGGen3_HBFS SG_ 2463978736 HFS_gesafet 1000;
BA_REL_ "GenSigTimeoutTime" BU_SG_REL_ TSGGen3_HBFS SG_ 2463978736 HFS_Tuerschloss_defekt 1000;
BA_REL_ "GenSigTimeoutTime" BU_SG_REL_ TSGGen3_HBFS SG_ 2463978736 HFS_FH_S_HBFS_AutoHoch 1000;
BA_REL_ "GenSigTimeoutTime" BU_SG_REL_ TSGGen3_HBFS SG_ 2463978736 HFS_FH_S_HBFS_AutoTief 1000;
BA_REL_ "GenSigTimeoutTime" BU_SG_REL_ TSGGen3_HBFS SG_ 258 ESP_Querbeschleunigung 500;
BA_REL_ "GenSigTimeoutTime" BU_SG_REL_ TSGGen3_HBFS SG_ 258 ESP_Laengsbeschl 500;
BA_REL_ "GenSigTimeoutTime" BU_SG_REL_ TSGGen3_HBFS SG_ 258 ESP_Gierrate 500;
BA_REL_ "GenSigTimeoutTime" BU_SG_REL_ TSGGen3_HFS SG_ 2463978735 DoorFunctions_HBFS_01_CRC 1000;
BA_REL_ "GenSigTimeoutTime" BU_SG_REL_ TSGGen3_HFS SG_ 2463978735 DoorFunctions_HBFS_01_BZ 1000;
BA_REL_ "GenSigTimeoutTime" BU_SG_REL_ TSGGen3_HFS SG_ 2463978735 HBFS_FH_S_HFS_ManHoch 1000;
BA_REL_ "GenSigTimeoutTime" BU_SG_REL_ TSGGen3_HFS SG_ 2463978735 HBFS_FH_S_HFS_ManTief 1000;
BA_REL_ "GenSigTimeoutTime" BU_SG_REL_ TSGGen3_HFS SG_ 2463978735 HBFS_FH_S_AutoHoch 1000;
BA_REL_ "GenSigTimeoutTime" BU_SG_REL_ TSGGen3_HFS SG_ 2463978735 HBFS_Oben_Block_erw 1000;
BA_REL_ "GenSigTimeoutTime" BU_SG_REL_ TSGGen3_HFS SG_ 2463978735 HBFS_Unten_Block_erw 1000;
BA_REL_ "GenSigTimeoutTime" BU_SG_REL_ TSGGen3_HFS SG_ 2463978735 HBFS_TCR_Mode_aktiv 1000;
BA_REL_ "GenSigTimeoutTime" BU_SG_REL_ TSGGen3_HFS SG_ 2463978735 HBFS_Tuer_geoeffnet 1000;
BA_REL_ "GenSigTimeoutTime" BU_SG_REL_ TSGGen3_HFS SG_ 2463978735 HBFS_Tuerschloss_defekt 1000;
BA_REL_ "GenSigTimeoutTime" BU_SG_REL_ TSGGen3_HFS SG_ 2463978735 HBFS_FH_S_HFS_AutoHoch 1000;
BA_REL_ "GenSigTimeoutTime" BU_SG_REL_ TSGGen3_HFS SG_ 2463978735 HBFS_FH_S_HFS_AutoTief 1000;
BA_REL_ "GenSigTimeoutTime" BU_SG_REL_ TSGGen3_HFS SG_ 2463978735 SSA_HBFT_FH_Oeffnungsweite 1000;
BA_REL_ "GenSigTimeoutTime" BU_SG_REL_ TSGGen3_HFS SG_ 258 ESP_Querbeschleunigung 500;
BA_REL_ "GenSigTimeoutTime" BU_SG_REL_ TSGGen3_HFS SG_ 258 ESP_Laengsbeschl 500;
BA_REL_ "GenSigTimeoutTime" BU_SG_REL_ TSGGen3_HFS SG_ 258 ESP_Gierrate 500;
VAL_ 2463978735 HBFS_FH_S_HFS_ManHoch 0 "keine_Bedienung" 1 "Manueller_Lauf_Angefordert" ;
VAL_ 2463978735 HBFS_FH_S_HFS_ManTief 0 "keine_Bedienung" 1 "Manueller_Lauf_Angefordert" ;
VAL_ 2463978735 HBFS_Tuer_Status 0 "Init" 1 "Tuer_geschlossen" 2 "Tuer_offen" 3 "Fehler" ;
VAL_ 2463978735 HBFS_SAD_Schalter 0 "nicht_betaetigt" 5 "AUF_manuell" 6 "AUF_automatik" 7 "ZU_manuell" 8 "ZU_automatik" 13 "nicht_verfuegbar" 14 "Init" 15 "Fehler" ;
VAL_ 2463978735 HBFS_FH_S_ManHoch 0 "nicht_betaetigt" 1 "betaetigt" ;
VAL_ 2463978735 HBFS_FH_S_AutoHoch 0 "nicht_betaetigt" 1 "betaetigt" ;
VAL_ 2463978735 HBFS_FH_S_ManTief 0 "nicht_betaetigt" 1 "betaetigt" ;
VAL_ 2463978735 HBFS_FH_S_AutoTief 0 "nicht_betaetigt" 1 "betaetigt" ;
VAL_ 2463978735 HBFS_FH_Bew_hoch 0 "inaktiv" 1 "aktiv" ;
VAL_ 2463978735 HBFS_FH_Bew_tief 0 "inaktiv" 1 "aktiv" ;
VAL_ 2463978735 HBFS_FH_Fang 0 "ausserhalb_Fangbereich" 1 "innerhalb_Fangbereich" ;
VAL_ 2463978735 HBFS_FH_Block 0 "inaktiv" 1 "aktiv" ;
VAL_ 2463978735 HBFS_FH_Thermo 0 "inaktiv" 1 "aktiv" ;
VAL_ 2463978735 HBFS_UEKB_aktiviert 0 "inaktiv" 1 "aktiv" ;
VAL_ 2463978735 HBFS_Tueroeffnen_Warnung 0 "Tuerwarnung_nicht_aktiv" 1 "Tuerwarnung_aktiv" ;
VAL_ 2463978735 HBFS_FH_normiert 0 "inaktiv" 1 "aktiv" ;
VAL_ 2463978735 ASW_Warnung_aktiv_HBFS 0 "nicht_angefordert" 1 "angefordert" ;
VAL_ 2463978735 HBFS_Zuziehhilfe_aktiv 0 "Init" 1 "Zuziehhilfe_aktiv" ;
VAL_ 2463978735 HBFS_Seitenrollo_hoch 1 "Seitenrollo_in_Bewegung_hoch" ;
VAL_ 2463978735 HBFS_Seitenrollo_tief 0 "Init" 1 "Seitenrollo_in_Bewegung_tief" ;
VAL_ 2463978735 HBFS_Status_KiSi 0 "inaktiv" 1 "aktiv" ;
VAL_ 2463978735 SSR_HBFS_Pos_Unten 0 "SSR_Oben" 1 "SSR_Unten" ;
VAL_ 2463978735 HBFS_Oben_Block_erw 0 "Fensterheber_nicht_in_Blockerwar" 1 "Fensterheber_in_Blockerwartung_o" ;
VAL_ 2463978735 HBFS_Unten_Block_erw 0 "Fensterheber_nicht_in_Blockerwar" 1 "Fensterheber_in_Blockerwartung_u" ;
VAL_ 2463978735 MTHBFS_M_Taste 0 "nicht_betaetigt" 1 "betaetigt" ;
VAL_ 2463978735 MTHBFS_Pos1 0 "nicht_betaetigt" 1 "betaetigt" ;
VAL_ 2463978735 MTHBFS_Pos2 0 "nicht_betaetigt" 1 "betaetigt" ;
VAL_ 2463978735 MTHBFS_Pos3 0 "nicht_betaetigt" 1 "betaetigt" ;
VAL_ 2463978735 HBFS_MRollo_Schalter 0 "nicht_betaetigt" 1 "ZU_manuell" 2 "ZU_automatik" 3 "AUF_manuell" 4 "AUF_automatik" 5 "nicht_verfuegbar" 6 "Init" 7 "Fehler" ;
VAL_ 2463978735 HBFS_Lock_Taster_inv 0 "Lock Taster betätgit" 1 "Lock Taster nicht betätigt" ;
VAL_ 2463978735 HBFS_Status_KiSi_inv 0 "aktiv" 1 "inaktiv" ;
VAL_ 2463978735 HBFS_Status_eTAG 0 "Init" 1 "Griff_ausgefahren" 2 "Griff_eingefahren" 3 "Fehler" ;
VAL_ 2463978735 HBFS_Tuer_Status_QBit 0 "Status_Tuerkontakt_sicher" 1 "Status_Tuerkontakt_unsicher" ;
VAL_ 2463978735 HBFS_TIG_betaetigt_schliessen 0 "nicht_betaetigt" 1 "betaetigt" ;
VAL_ 2463978735 HBFS_TIG_betaetigt_oeffnen 0 "nicht_betaetigt" 1 "betaetigt" ;
VAL_ 2463978735 HBFS_Vorraste_betaetigt 0 "nicht_in_Vorraste" 1 "in_Vorraste" ;
VAL_ 2463978735 HBFS_SK_betaetigt 0 "ausgehoben" 1 "eingefallen" ;
VAL_ 2463978735 HBFS_KiSi_Fehler 0 "kein_Fehler" 1 "Fehler_liegt_an" ;
VAL_ 2463978735 HBFS_TCR_Mode_aktiv 0 "TCR_Mode_deaktiv" 1 "TCR_Mode_aktiv" ;
VAL_ 2463978735 SSA_HBFT_FH_Thermoschutz 0 "Thermoschutz_deaktiv" 1 "Thermoschutz_aktiv" ;
VAL_ 2463978735 SSA_HBFT_ZZH_Status 0 "Init" 1 "Zuziehvorgang_aktiv" ;
VAL_ 2463978735 SSA_HBFT_SSR_Status 0 "Init" 1 "oben" 2 "unten" ;
VAL_ 2463978735 SSA_HBFT_ASW_Status 0 "Init" 1 "InfoStufe_aktiv" 2 "Warnstufe_aktiv" ;
VAL_ 2463978735 TSG_FlHz_HBFS_NTC_A 125 "Fehler_NTC_OpenLoad__KS_Plus" 126 "Fehler_NTC_Overload__KS_Minus" 127 "Init" ;
VAL_ 2463978735 TSG_FlHz_HBFS_FnAbbruchHzKreis_A 0 "OK" 1 "FunktionsAbbruch" ;
VAL_ 2463978735 TSG_FlHz_HBFS_NTC_B 125 "Fehler_NTC_OpenLoad__KS_Plus" 126 "Fehler_NTC_Overload__KS_Minus" 127 "Init" ;
VAL_ 2463978735 TSG_FlHz_HBFS_FnAbbruchHzKreis_B 0 "OK" 1 "FunktionsAbbruch" ;
VAL_ 2463978735 SSA_HBFT_Tuerverschluss_Status 0 "Init" 1 "Tuer_geschlossen" 2 "Tuer_offen" ;
VAL_ 2463978735 SSA_HBFT_el_Tuerantrieb_Status 0 "Init" 1 "offen" 2 "geschlossen" ;
VAL_ 2463978735 SSA_HBFT_Amb_Bel_Status 0 "Init" 1 "an" 2 "aus" ;
VAL_ 2463978735 SSA_HBFT_FH_Bewegungsrichutng 0 "Stillstand" 1 "FH_in_Bewegung_Schliessen" 2 "FH_in_Bewegung_Oeffnen" ;
VAL_ 2463978735 BFS_Lehnenkopf_vor 0 "Taste_nicht_gedrueckt" 1 "Lehnenkopf_vor" ;
VAL_ 2463978735 BFS_Lehnenkopf_zurueck 0 "Taste_nicht_gedrueckt" 1 "Lehnenkopf_zurueck" ;
VAL_ 2463978735 BFS_Lehnenneigung_vor 0 "Taste_nicht_gedrueckt" 1 "Lehnenneigung vor (Wird bei Rechtslenker vom TSG HL gesendet)" ;
VAL_ 2463978735 BFS_Lehnenneigung_zurueck 0 "Taste_nicht_gedrueckt" 1 "Lehnenneigung_zurueck" ;
VAL_ 2463978735 BFS_Sitzhoehe_hoch 0 "aus" 1 "hoch" ;
VAL_ 2463978735 BFS_Sitzhoehe_runter 0 "aus" 1 "runter" ;
VAL_ 2463978735 BFS_Kopfstuetzen_hoch 0 "Taste_nicht_gedrueckt" 1 "Kopfstuetzen_hoch" ;
VAL_ 2463978735 BFS_Kopfstuetzen_runter 0 "Taste_nicht_gedrueckt" 1 "Kopfstuetzen_runter" ;
VAL_ 2463978735 BFS_Laengsverst_vor 0 "Taste_nicht_gedrueckt" 1 "Laengsverstellung_vor" ;
VAL_ 2463978735 BFS_Laengsverst_zurueck 0 "Taste_nicht_gedrueckt" 1 "Längsverstellung zurück (Wird bei Rechtslenker vom TSG HL gesendet)" ;
VAL_ 2463978735 MTHBF_ein 0 "aus" 1 "ein" ;
VAL_ 2463978735 SSA_HBFS_eKisi_Status 0 "Init" 1 "inaktiv" 2 "aktiv" ;
VAL_ 2463978735 SSA_HBFT_Tuerverschluss_Fehler 0 "in_Ordnung" 1 "nicht_verbaut" 2 "Unterspannung" 3 "Ueberspannung" 4 "elektrischer_Fehler" 5 "Bedingung_nicht_erfuellt" ;
VAL_ 2463978735 SSA_HBFT_FH_Fehler 0 "iO" 1 "nicht_verbaut" 2 "Unterspannung" 3 "Ueberspannung" 4 "el_Fehler" 5 "Bedingung_nicht_erfuellt" ;
VAL_ 2463978735 SSA_HBFS_eKisi_Fehler 0 "iO" 1 "nicht_verbaut" 2 "Unterspannung" 3 "Ueberspannung" 4 "el_Fehler" 5 "Bedingung_nicht_erfuellt" ;
VAL_ 2463978735 SSA_HBFT_Amb_Bel_Fehler 0 "in_Ordnung" 1 "nicht_verbaut" 2 "Unterspannung" 3 "Ueberspannung" 4 "elektrischer_Fehler" 5 "Bedingung_nicht_erfuellt" ;
VAL_ 2463978735 SSA_HBFT_FH_Normierung 0 "nicht_normiert" 1 "normiert" ;
VAL_ 2463978735 SSA_HBFT_el_Tuerantrieb_Fehler 0 "iO" 1 "nicht_verbaut" 2 "Unterspannung" 3 "Ueberspannung" 4 "el_Fehler" 5 "Bedingung_nicht_erfuellt" ;
VAL_ 2463978735 SSA_HBFT_ZZH_Fehler 0 "in_Ordnung" 1 "nicht_verbaut" 2 "Unterspannung" 3 "Ueberspannung" 4 "elektrischer_Fehler" 5 "Bedingung_nicht_erfuellt" ;
VAL_ 2463978735 SSA_HBFT_ZV_Fehler 0 "in_Ordnung" 1 "nicht_verbaut" 2 "Unterspannung" 3 "Ueberspannung" 4 "elektrischer_Fehler" 5 "Bedingung_nicht_erfuellt" ;
VAL_ 2463978735 SSA_HBFT_ASW_Fehler 0 "iO" 1 "nicht_verbaut" 2 "Unterspannung" 3 "Ueberspannung" 4 "el_Fehler" 5 "Bedingung_nicht_erfuellt" ;
VAL_ 2463978735 SSA_HBFT_SSR_Fehler 0 "in_Ordnung" 1 "nicht_verbaut" 2 "Unterspannung" 3 "Ueberspannung" 4 "elektrischer_Fehler" 5 "Bedingung_nicht_erfuellt" ;
VAL_ 2463978735 eTAB_HBFS_Oeffnen_Annaeh 0 "Init_keine_Annaeherung" 1 "Annaeherung_Oeffnen_erkannt" ;
VAL_ 2463978735 eTAB_HBFS_Oeffnen_Betaet 0 "Init_keine_Annaeherung" 1 "Betaetigung_Oeffnen_erkannt" ;
VAL_ 2463978735 eTAB_HBFS_Schliessen_Annaeh 0 "Init_keine_Annaeherung" 1 "Annaeherung_Schliessen_erkannt" ;
VAL_ 2463978735 HBFS_ASW_Warnung_Aussenlicht 0 "kein_licht" 1 "licht_links" 2 "licht_rechts" 3 "Fehler" ;
VAL_ 2463978735 HBFS_ASW_Warnton 0 "kein_warnton" 1 "warnton_links" 2 "warnton_rechts" 3 "Fehler" ;
VAL_ 2463978735 HBFS_Tuer_geoeffnet 0 "geschlossen" 1 "offen" ;
VAL_ 2463978735 HBFS_verriegelt 0 "nicht_verriegelt" 1 "verriegelt" ;
VAL_ 2463978735 HBFS_gesafet 0 "nicht_gesafet" 1 "gesafet" ;
VAL_ 2463978735 HBFS_Heckrollotaster_betaetigt 0 "keine_Verfahranweisung_in_Richtung_Hoch" 1 "In_Richtung_Hoch_Verfahren" ;
VAL_ 2463978735 HBFS_Tuerschloss_defekt 0 "Tuerschloss_funktionsfaehig" 1 "Tuerschloss_defekt" ;
VAL_ 2463978735 HBFS_Unlock_Taster 0 "nicht_betaetigt" 1 "betaetigt" ;
VAL_ 2463978735 HBFS_Lock_Taster 0 "nicht_betaetigt" 1 "betaetigt" ;
VAL_ 2463978735 HBFS_Sperrklinke 0 "Schloss_in_Vorraste_und_Hauptraste" 1 "Tuer_auf_oder_Tuer_Position_zwischen_Vor_und_Hauptraste" ;
VAL_ 2463978735 HBFS_TAG_betaetigt 0 "nicht_betaetigt" 1 "betaetigt" ;
VAL_ 2463978735 HBFS_TIG_betaetigt 0 "nicht_betaetigt" 1 "betaetigt" ;
VAL_ 2463978735 HBFS_FH_S_HFS_AutoHoch 0 "keine_Bedienung" 1 "Automatiklauf_Angefordert" ;
VAL_ 2463978735 HBFS_FH_S_HFS_AutoTief 0 "keine_Bedienung" 1 "Automatiklauf_Angefordert" ;
VAL_ 2463978735 TSG_FlHz_HBFS_Unterbrech_HzK_A 0 "keine_Unterbrechung" 1 "Unterbrechung" ;
VAL_ 2463978735 TSG_FlHz_HBFS_Unterbrech_HzK_B 0 "keine_Unterbrechung" 1 "Unterbrechung" ;
VAL_ 2463978735 HBFS_ASW_HMI_defekt 0 "ASW_kein_Fehler" 1 "ASW_Fehler" ;
VAL_ 2463978735 eTAB_HBFS_Schliessen_Betaet 0 "Init_keine_Annaeherung" 1 "Betaetigung_Schliessen_erkannt" ;
VAL_ 2463978735 HBFS_Push_Tuergriff 0 "nicht_erkannt" 1 "erkannt" ;
VAL_ 2463978735 HBFS_Status_eTAG_ext 0 "Griff_eingefahren" 1 "Griff_ausgefahren" 2 "Griff_verfaehrt" 3 "init" 4 "Fehler" ;
VAL_ 2463978735 HBFS_Schloss_Status_OeH_Motor 0 "Init" 1 "OeH_Motor_Grundstellung" 2 "OeH_Motor_perm_offen" 3 "Fehler" ;
VAL_ 2463978735 HBFS_Schloss_oeffnen_Ansteuerung 0 "Init" 1 "deaktiv_nicht_ansteuern" 2 "aktiv_oeffnen_ansteuern" 3 "Fehler" ;
VAL_ 2463978736 HFS_FH_S_HBFS_ManHoch 0 "keine_Bedienung" 1 "Manueller_Lauf_Angefordert" ;
VAL_ 2463978736 HFS_FH_S_HBFS_ManTief 0 "keine_Bedienung" 1 "Manueller_Lauf_Angefordert" ;
VAL_ 2463978736 HFS_Tuer_Status 0 "Init" 1 "Tuer_geschlossen" 2 "Tuer_offen" 3 "Fehler" ;
VAL_ 2463978736 HFS_SAD_Schalter 0 "nicht_betaetigt" 5 "AUF_manuell" 6 "AUF_automatik" 7 "ZU_manuell" 8 "ZU_automatik" 13 "nicht_verfuegbar" 14 "Init" 15 "Fehler" ;
VAL_ 2463978736 HFS_FH_S_ManHoch 0 "nicht_betaetigt" 1 "betaetigt" ;
VAL_ 2463978736 HFS_FH_S_AutoHoch 0 "nicht_betaetigt" 1 "betaetigt" ;
VAL_ 2463978736 HFS_FH_S_ManTief 0 "nicht_betaetigt" 1 "betaetigt" ;
VAL_ 2463978736 HFS_FH_S_AutoTief 0 "nicht_betaetigt" 1 "betaetigt" ;
VAL_ 2463978736 HFS_FH_Bew_hoch 0 "inaktiv" 1 "aktiv" ;
VAL_ 2463978736 HFS_FH_Bew_tief 0 "inaktiv" 1 "aktiv" ;
VAL_ 2463978736 HFS_FH_Fang 0 "ausserhalb_Fangbereich" 1 "innerhalb_Fangbereich" ;
VAL_ 2463978736 HFS_FH_Block 0 "inaktiv" 1 "aktiv" ;
VAL_ 2463978736 HFS_FH_Thermo 0 "inaktiv" 1 "aktiv" ;
VAL_ 2463978736 HFS_UEKB_aktiviert 0 "inaktiv" 1 "aktiv" ;
VAL_ 2463978736 HFS_Tueroeffnen_Warnung 0 "Tuerwarnung_nicht_aktiv" 1 "Tuerwarnung_aktiv" ;
VAL_ 2463978736 HFS_FH_normiert 0 "inaktiv" 1 "aktiv" ;
VAL_ 2463978736 ASW_Warnung_aktiv_HFS 0 "nicht_angefordert" 1 "angefordert" ;
VAL_ 2463978736 HFS_Zuziehhilfe_aktiv 0 "Init" 1 "Zuziehhilfe_aktiv" ;
VAL_ 2463978736 HFS_Seitenrollo_hoch 0 "Init" 1 "Seitenrollo_in_Bewegung_hoch" ;
VAL_ 2463978736 HFS_Seitenrollo_tief 0 "Init" 1 "Seitenrollo_in_Bewegung_tief" ;
VAL_ 2463978736 HFS_Status_KiSi 0 "inaktiv" 1 "aktiv" ;
VAL_ 2463978736 SSR_HFS_Pos_Unten 0 "SSR_Oben" 1 "SSR_Unten" ;
VAL_ 2463978736 HFS_Oben_Block_erw 0 "Fensterheber_nicht_in_Blockerwar" 1 "Fensterheber_in_Blockerwartung_o" ;
VAL_ 2463978736 HFS_Unten_Block_erw 0 "Fensterheber_nicht_in_Blockerwar" 1 "Fensterheber_in_Blockerwartung_u" ;
VAL_ 2463978736 MTHFS_M_Taste 0 "nicht_betaetigt" 1 "betaetigt" ;
VAL_ 2463978736 MTHFS_Pos1 0 "nicht_betaetigt" 1 "betaetigt" ;
VAL_ 2463978736 MTHFS_Pos2 0 "nicht_betaetigt" 1 "betaetigt" ;
VAL_ 2463978736 MTHFS_Pos3 0 "nicht_betaetigt" 1 "betaetigt" ;
VAL_ 2463978736 HFS_MRollo_Schalter 0 "nicht_betaetigt" 1 "ZU_manuell" 2 "ZU_automatik" 3 "AUF_manuell" 4 "AUF_automatik" 5 "nicht_verfuegbar" 6 "Init" 7 "Fehler" ;
VAL_ 2463978736 HFS_Lock_Taster_inv 0 "Lock Taster betätgit" 1 "Lock Taster nicht betätigt" ;
VAL_ 2463978736 HFS_Status_eTAG 0 "Init" 1 "Griff_ausgefahren" 2 "Griff_eingefahren" 3 "Fehler" ;
VAL_ 2463978736 HFS_Tuer_Status_QBit 0 "Status_Tuerkontakt_sicher" 1 "Status_Tuerkontakt_unsicher" ;
VAL_ 2463978736 HFS_TCR_Mode_aktiv 0 "TCR_Mode_deaktiv" 1 "TCR_Mode_aktiv" ;
VAL_ 2463978736 HFS_TIG_betaetigt_schliessen 0 "nicht_betaetigt" 1 "betaetigt" ;
VAL_ 2463978736 HFS_TIG_betaetigt_oeffnen 0 "nicht_betaetigt" 1 "betaetigt" ;
VAL_ 2463978736 HFS_Vorraste_betaetigt 0 "nicht_in_Vorraste" 1 "in_Vorraste" ;
VAL_ 2463978736 HFS_SK_betaetigt 0 "ausgehoben" 1 "eingefallen" ;
VAL_ 2463978736 TSG_FlHz_HFS_NTC_A 125 "Fehler_NTC_OpenLoad__KS_Plus" 126 "Fehler_NTC_Overload__KS_Minus" 127 "Init" ;
VAL_ 2463978736 TSG_FlHz_HFS_FnAbbruchHzKreis_A 0 "OK" 1 "FunktionsAbbruch" ;
VAL_ 2463978736 TSG_FlHz_HFS_NTC_B 125 "Fehler_NTC_OpenLoad__KS_Plus" 126 "Fehler_NTC_Overload__KS_Minus" 127 "Init" ;
VAL_ 2463978736 TSG_FlHz_HFS_FnAbbruchHzKreis_B 0 "OK" 1 "FunktionsAbbruch" ;
VAL_ 2463978736 SSA_HFT_Tuerverschluss_Status 0 "Init" 1 "Tuer_geschlossen" 2 "Tuer_offen" ;
VAL_ 2463978736 SSA_HFT_el_Tuerantrieb_Status 0 "Init" 1 "offen" 2 "geschlossen" ;
VAL_ 2463978736 SSA_HFT_ZV_Status 0 "Init" 1 "entriegelt_entsafet" 2 "verriegelt_entsafet" 3 "verriegelt_gesafet" 15 "Fehler" ;
VAL_ 2463978736 eTAB_HFS_Oeffnen_Annaeh 0 "Init_keine_Annaeherung" 1 "Annaeherung_Oeffnen_erkannt" ;
VAL_ 2463978736 eTAB_HFS_Oeffnen_Betaet 0 "Init_keine_Annaeherung" 1 "Betaetigung_Oeffnen_erkannt" ;
VAL_ 2463978736 eTAB_HFS_Schliessen_Annaeh 0 "Init_keine_Annaeherung" 1 "Annaeherung_Schliessen_erkannt" ;
VAL_ 2463978736 eTAB_HFS_Schliessen_Betaet 0 "Init_keine_Annaeherung" 1 "Betaetigung_Schliessen_erkannt" ;
VAL_ 2463978736 SSA_HFT_Amb_Bel_Status 0 "Init" 1 "an" 2 "aus" ;
VAL_ 2463978736 SSA_HFT_FH_Bewegungsrichutng 0 "Stillstand" 1 "FH_in_Bewegung_Schliessen" 2 "FH_in_Bewegung_Oeffnen" ;
VAL_ 2463978736 SSA_HFT_SSR_Status 0 "Init" 1 "oben" 2 "unten" ;
VAL_ 2463978736 SSA_HFS_eKisi_Status 0 "Init" 1 "inaktiv" 2 "aktiv" ;
VAL_ 2463978736 SSA_HFT_ZZH_Status 0 "Init" 1 "Zuziehvorgang_aktiv" ;
VAL_ 2463978736 SSA_HFT_ASW_Status 0 "Init" 1 "InfoStufe_aktiv" 2 "Warnstufe_aktiv" ;
VAL_ 2463978736 SSA_HFT_ZV_Ansteuern 0 "Init" 1 "entriegelnentsafen" 2 "verriegelnentsafen" 3 "verriegelnsafen" 255 "Fehler" ;
VAL_ 2463978736 SSA_HFT_FH_Thermoschutz 0 "Thermoschutz_deaktiv" 1 "Thermoschutz_aktiv" ;
VAL_ 2463978736 SSA_HFT_Tuerverschluss_Fehler 0 "In_Ordnung" 1 "nicht_verbaut" 2 "Unterspannung" 3 "Ueberspannung" 4 "elektrischer_Fehler" 5 "Bedingung_nicht_erfuellt" ;
VAL_ 2463978736 SSA_HFT_SSR_Fehler 0 "in_Ordnung" 1 "nicht_verbaut" 2 "Unterspannung" 3 "Ueberspannung" 4 "elektrischer_Fehler" 5 "Bedingung_nicht_erfuellt" ;
VAL_ 2463978736 SSA_HFT_Amb_Bel_Fehler 0 "iO" 1 "nicht_verbaut" 2 "Unterspannung" 3 "Ueberspannung" 4 "el_Fehler" 5 "Bedingung_nicht_erfuellt" ;
VAL_ 2463978736 SSA_HFT_FH_Fehler 0 "iO" 1 "nicht_verbaut" 2 "Unterspannung" 3 "Ueberspannung" 4 "el_Fehler" 5 "Bedingung_nicht_erfuellt" ;
VAL_ 2463978736 SSA_HFS_eKisi_Fehler 0 "iO" 1 "nicht_verbaut" 2 "Unterspannung" 3 "Ueberspannung" 4 "el_Fehler" 5 "Bedingung_nicht_erfuellt" ;
VAL_ 2463978736 SSA_HFT_ZZH_Fehler 0 "in_Ordnung" 1 "nicht_verbaut" 2 "Unterspannung" 3 "Ueberspannung" 4 "elektrischer_Fehler" 5 "Bedingung_nicht_erfuellt" ;
VAL_ 2463978736 SSA_HFT_ZV_Fehler 0 "in_Ordnung" 1 "nicht_verbaut" 2 "Unterspannung" 3 "Ueberspannung" 4 "elektrischer_Fehler" 5 "Bedingung_nicht_erfuellt" ;
VAL_ 2463978736 SSA_HFT_el_Tuerantrieb_Fehler 0 "iO" 1 "nicht_verbaut" 2 "Unterspannung" 3 "Ueberspannung" 4 "el_Fehler" 5 "Bedingung_nicht_erfuellt" ;
VAL_ 2463978736 SSA_HFT_ASW_Fehler 0 "iO" 1 "nicht_verbaut" 2 "Unterspannung" 3 "Ueberspannung" 4 "el_Fehler" 5 "Bedingung_nicht_erfuellt" ;
VAL_ 2463978736 SSA_HFT_FH_Normierung 0 "nicht_normiert" 1 "normiert" ;
VAL_ 2463978736 HFS_Schloss_Status_OeH_Motor 0 "Init" 1 "OeH_Motor_Grundstellung" 2 "OeH_Motor_perm_offen" 3 "Fehler" ;
VAL_ 2463978736 HFS_Tuer_geoeffnet 0 "geschlossen" 1 "offen" ;
VAL_ 2463978736 HFS_verriegelt 0 "nicht_verriegelt" 1 "verriegelt" ;
VAL_ 2463978736 HFS_gesafet 0 "nicht_gesafet" 1 "gesafet" ;
VAL_ 2463978736 HFS_Heckrollotaster_betaetigt 0 "keine_Verfahranweisung_in_Richtung_Hoch" 1 "In_Richtung_Hoch_Verfahren" ;
VAL_ 2463978736 HFS_Tuerschloss_defekt 0 "Tuerschloss_funktionsfaehig" 1 "Tuerschloss_defekt" ;
VAL_ 2463978736 HFS_Unlock_Taster 0 "nicht_betaetigt" 1 "betaetigt" ;
VAL_ 2463978736 HFS_Lock_Taster 0 "nicht_betaetigt" 1 "betaetigt" ;
VAL_ 2463978736 HFS_Sperrklinke 0 "Schloss_in_Vorraste_und_Hauptraste" 1 "Tuer_auf_oder_Tuer_Position_zwischen_Vor_und_Hauptraste" ;
VAL_ 2463978736 HFS_TAG_betaetigt 0 "nicht_betaetigt" 1 "betaetigt" ;
VAL_ 2463978736 HFS_TIG_betaetigt 0 "nicht_betaetigt" 1 "betaetigt" ;
VAL_ 2463978736 HFS_FH_S_HBFS_AutoHoch 0 "keine_Bedienung" 1 "Automatiklauf_Angefordert" ;
VAL_ 2463978736 HFS_FH_S_HBFS_AutoTief 0 "keine_Bedienung" 1 "Automatiklauf_Angefordert" ;
VAL_ 2463978736 TSG_FlHz_HFS_Unterbrech_HzK_A 0 "keine_Unterbrechung" 1 "Unterbrechung" ;
VAL_ 2463978736 HFS_Push_Tuergriff 0 "nicht_erkannt" 1 "erkannt" ;
VAL_ 2463978736 HFS_Status_eTAG_ext 0 "Griff_eingefahren" 1 "Griff_ausgefahren" 2 "Griff_verfaehrt" 3 "init" 4 "Fehler" ;
VAL_ 2463978736 HFS_KiSi_Fehler 0 "kein_Fehler" 1 "Fehler_liegt_an" ;
VAL_ 2463978736 HFS_ASW_Warnton 0 "kein_warnton" 1 "warnton_links" 2 "warnton_rechts" 3 "Fehler" ;
VAL_ 2463978736 HFS_Schloss_oeffnen_Ansteuerung 0 "Init" 1 "deaktiv_nicht_ansteuern" 2 "aktiv_oeffnen_ansteuern" 3 "Fehler" ;
VAL_ 2463978736 HFS_ASW_HMI_defekt 0 "ASW_kein_Fehler" 1 "ASW_Fehler" ;
VAL_ 2463978736 HFS_ASW_Warnung_Aussenlicht 0 "kein_licht" 1 "licht_links" 2 "licht_rechts" 3 "Fehler" ;
VAL_ 496 EA_Texte 0 "keine_Anzeige" 1 "Nothalteassistent_fehlende_Fahreraktivitaet" 2 "Nothalteassistent_aktiv_Fahrzeugfuehrung_uebernehmen" 3 "Nothalteassistent_automatischer_Nothalt_wird_durchgefuehrt" 4 "Nothalteassistent_automatischer_Nothalt_durchgefuehrt" 5 "Nothalteassistent_Verbindung_zum_Notruf_wird_aufgebaut" 6 "Nothalteassistent_deaktiviert" 7 "Nothalteassistent_Eingriff_abgebrochen" 8 "Nothalteassistent_fehlende_Fahreraktivitaet_2" 9 "Sekundenschlaf_erkannt" 10 "LaneAssist_Lenkung_uebernehmen" 11 "ACA_Fahrzeugfuehrung_uebernehmen" 12 "EA_Fahr_Standstreifenwechsel" 14 "Nothalteassistent_nicht_verfuegbar_reversibel" 15 "Nothalteassistent_Stoerung_irreversibel" ;
VAL_ 496 ACF_Lampe_Hands_Off 0 "keine_Anzeige" 1 "Hands_Off_erkannt" ;
VAL_ 496 EA_Fahrzeughupe_Anf 0 "keine_Anforderung" 1 "Anforderung_Fahrzeughupe" ;
VAL_ 496 EA_eCall_Anf 0 "Keine_Anforderung" 1 "Ausloesen_eCall" ;
VAL_ 496 EA_Infotainment_Anf 0 "Init" 1 "Keine_Absenkung" 2 "Absenkung" 3 "Mute" ;
VAL_ 496 EA_Tueren_Anf 0 "Keine_Anforderung" 1 "Tueren_entriegeln" ;
VAL_ 496 EA_Innenraumlicht_Anf 0 "Innenraumbeleuchtung_ausschalten" 1 "Innenraumbeleuchtung_einschalten" ;
VAL_ 496 zFAS_Warnblinken 0 "Aus" 1 "Statisch" 2 "Taster" 3 "Statisch_ohne_WBT" ;
VAL_ 496 STP_Primaeranz 0 "keine_Anzeige" 1 "Verfuegbar" 2 "Aktiv" 3 "Uebernahme" 4 "Aktiv_Warnung" 5 "Nicht_Verfuegbar" ;
VAL_ 496 EA_Bremslichtblinken 0 "kein_Blinken" 1 "Anforderung_Bremslichtblinken" ;
VAL_ 496 EA_Blinken 0 "Kein_Blinken" 1 "Wechselblinken_links" 2 "Wechselblinken_rechts" 3 "Warnblinken" 4 "Warnblinken_Taster" 5 "Richtungsblinken_links" 6 "Richtungsblinken_rechts" ;
VAL_ 496 EA_Status_HMI 0 "Keine_Anzeige" 1 "Aktiv_quer_laengs" 2 "Aktiv_laengs" ;
VAL_ 496 EA_Warnlevel 0 "keine_Gefaehrdung" 63 "max_Gefaehrdung" ;
VAL_ 1603 KBI_Einheit_Datum 0 "Tag/Monat/Jahr" 1 "Monat/Tag/Jahr" 2 "Jahr/Monat/Tag" 3 "reserviert" ;
VAL_ 1603 KBI_Einheit_Druck 0 "Druckangabe in bar" 1 "Druckangabe in psi" 2 "Druckangabe in kPa" 3 "tbd." ;
VAL_ 1603 KBI_Einheit_Streckenanz 0 "Kilometer" 1 "Meilen" ;
VAL_ 1603 KBI_MFA_v_Einheit_02 0 "kmh" 1 "mph" ;
VAL_ 1603 KBI_Einheit_Temp 0 "Grad Celsius °C" 1 "Grad Fahrenheit °F" ;
VAL_ 1603 KBI_Einheit_Uhrzeit 0 "24h" 1 " 12h AM/PM" ;
VAL_ 1603 KBI_Einheit_Verbrauch 0 "mpg UK" 1 "mpg USA" 2 "Liter/100km" 3 "km/Liter" ;
VAL_ 1603 KBI_Einheit_Volumen 0 "Liter" 1 "Gallonen UK" 2 "Gallonen USA" 3 "reserviert" ;
VAL_ 1603 KBI_Einheit_Verbrauch_elektr 0 "kWh_pro_100km" 1 "km_pro_kWh" 2 "kWh_pro_100mls" 3 "mls_pro_kWh" 4 "MPGe" ;
VAL_ 1603 KBI_Einheit_Tacho 0 "km/h" 1 "mph" ;
VAL_ 1603 KBI_Einheit_Verbrauch_Gas 0 "kg_per_100km" 1 "km_per_kg" 2 "m3_per_100km" 3 "km_per_m3" 4 "miles_per_lbs" 5 "miles_per_yard3" 6 "miles_per_kg" 7 "miles_per_m3" 8 "miles_per_gallon_equivalent_US" ;
VAL_ 1603 KBI_Einheit_Masse 0 "kg" 1 "lbs" 2 "reserviert" ;
VAL_ 1622 ELV_Anf_Klemme_S 0 "Aus" 1 "Ein" ;
VAL_ 1622 ELV_Anf_Klemme_15 0 "Aus" 1 "Ein" ;
VAL_ 1622 ELV_Anf_Klemme_50 0 "Aus" 1 "Ein" ;
VAL_ 1622 ELV_01_Sendestatus 0 "ELV_sendet_mit_1000ms" 1 "ELV_sendet_mit_50ms" ;
VAL_ 1622 ELV_Verriegelt 0 "nicht_verriegelt" 1 "verriegelt" ;
VAL_ 1622 ELV_Entriegelt 0 "ELV_nicht_entriegelt" 1 "ELV_entriegelt" ;
VAL_ 1622 ELV_ZAT_betaetigt 0 "nicht_betaetigt" 1 "betaetigt" ;
VAL_ 1622 ELV_Lebenszustand 0 "Lebenszustand_0" 1 "Lebenszustand_4" ;
VAL_ 1622 ELV_Anlernmodus 0 "Normalbetrieb" 1 "Anlernmodus" ;
VAL_ 1622 KST_aut_Abschaltung_Zuendung 0 "Zuendung_wird_bei_Verl_nicht_deaktiviert" 1 "Zuendung_wird_bei_Verl_deaktiviert" ;
VAL_ 1622 ELV_Klemmenfreigabe 0 "keine_Freigabe" 1 "Freigabe" ;
VAL_ 1622 ELV_Abbruch_Anf_Klemmenfreigabe 0 "kein_Abbruch" 1 "Abbruch" ;
VAL_ 1622 ELV_LED_Rot 0 "Aus" 1 "Ein" ;
VAL_ 1622 ELV_LED_Gelb 0 "Aus" 1 "Ein" ;
VAL_ 1622 ELV_Txt_Panikabschaltung 0 "Aus" 1 "Ein" ;
VAL_ 1622 ELV_Txt_Lkg_Bewegen 0 "Aus" 1 "Ein" ;
VAL_ 1622 ELV_Txt_Werkstatt 0 "Aus" 1 "Ein" ;
VAL_ 1622 ELV_Txt_Defekt 0 "Aus" 1 "Ein" ;
VAL_ 1622 ELV_Txt_P_Gang 0 "Aus" 1 "Ein" ;
VAL_ 1622 ELV_Txt_PN_Gang 0 "Aus" 1 "Ein" ;
VAL_ 1622 ELV_Txt_Kupplung 0 "Aus" 1 "Ein" ;
VAL_ 1622 ELV_Txt_Bremse 0 "Aus" 1 "Ein" ;
VAL_ 1622 ELV_P_verriegelt 0 "nicht_verriegelt" 1 "verriegelt" ;
VAL_ 1622 KST_Txt_Komfortabschaltung 0 "inaktiv" 1 "aktiv" ;
VAL_ 1622 KST_Anf_ZV_Verriegelung 0 "inaktiv" 1 "aktiv" ;
VAL_ 26 ELV_WFS_Anfrage_Typ 0 "Init" ;
VAL_ 26 ELV_WFS_Anfrage_CRC 0 "Init" ;
VAL_ 26 ELV_WFS_Anfrage_Status 0 "Init" ;
VAL_ 184 EM1_Freigabe_Info_WFS 0 "ungueltig" 1 "gueltig" ;
VAL_ 184 EM1_Sperr_Info_WFS 0 "nicht_gesperrt" 1 "gesperrt" ;
VAL_ 184 EM1_AR_aktiv 0 "Init" 1 "Ruckeldaempfer_aktiv" ;
VAL_ 184 EM1_Eta_Sys 510 "Init" 511 "Fehler" ;
VAL_ 184 EM1_IstStrom 2046 "Init" 2047 "Fehler" ;
VAL_ 184 EM1_Fehler_ElAntriebFreilauf_Anf 0 "Init" 1 "Fehler_EM_im_Freilauf" ;
VAL_ 184 EM1_Abregelung_Temperatur 0 "Init" 1 "Abregelung_Temperatur" ;
VAL_ 184 EM1_AnlernenElMotor_Anf 0 "kein_Diagnose_Request" 1 "Diagnose_Request" ;
VAL_ 184 EM1_Moment_HVVerbraucher 1023 "Init" ;
VAL_ 184 LE_Kuehlmittel_Sensor 0 "OK" 1 "Kuehlmittel_unter_min" ;
VAL_ 184 EM1_Freigabe_Verfallsinfo_WFS 0 "Aus" 1 "Ein" ;
VAL_ 184 EM1_Parken_WFS_Status 0 "Limitierung_Inaktiv" 1 "Limitierung_Aktiv" 2 "Abbruch" ;
VAL_ 184 EM1_HV_betriebsbereit 0 "Init" 1 "Ready_HV" ;
VAL_ 199 EM2_Freigabe_Info_WFS 0 "ungueltig" 1 "gueltig" ;
VAL_ 199 EM2_Sperr_Info_WFS 0 "nicht_gesperrt" 1 "gesperrt" ;
VAL_ 199 EM2_AR_aktiv 0 "Init" 1 "Ruckeldaempfer_aktiv" ;
VAL_ 199 EM2_Eta_Sys 510 "Init" 511 "Fehler" ;
VAL_ 199 EM2_IstStrom 2046 "Init" 2047 "Fehler" ;
VAL_ 199 EM2_Fehler_ElAntriebFreilauf_Anf 0 "Init" 1 "Fehler_EM_im_Freilauf" ;
VAL_ 199 EM2_Abregelung_Temperatur 0 "Init" 1 "Abregelung_Temperatur" ;
VAL_ 199 EM2_AnlernenElMotor_Anf 0 "kein_Diagnose_Request" 1 "Diagnose_Request" ;
VAL_ 199 EM2_Freigabe_Verfallsinfo_WFS 0 "Aus" 1 "Ein" ;
VAL_ 199 EM2_Parken_WFS_Status 0 "Limitierung_Inaktiv" 1 "Limitierung_Aktiv" 2 "Abbruch" ;
VAL_ 199 EM2_HV_betriebsbereit 0 "Init" 1 "Ready_HV" ;
VAL_ 624 EmpfSTSG_HBFS_Status_KiSi 0 "inaktiv" 1 "aktiv" ;
VAL_ 624 EmpfSTSG_HBFS_KiSi_Fehler 0 "kein_Fehler" 1 "Fehler" ;
VAL_ 624 EmpfSTSG_HBFS_FH_normiert 0 "inaktiv" 1 "aktiv" ;
VAL_ 624 EmpfSTSG_HBFS_TAG_betaetigt 0 "nicht_betaetigt" 1 "betaetigt" ;
VAL_ 624 EmpfSTSG_HBFS_Vorraste_betaetigt 0 "nicht_in_Vorraste" 1 "in_Vorraste" ;
VAL_ 624 EmpfSTSG_HBFS_TIG_bet_schliessen 0 "nicht_betaetigt" 1 "betaetigt" ;
VAL_ 624 EmpfSTSG_HBFS_TIG_bet_oeffnen 0 "nicht_betaetigt" 1 "betaetigt" ;
VAL_ 624 EmpfSTSG_HBFS_SK_betaetigt 0 "ausgehoben" 1 "eingefallen" ;
VAL_ 624 EmpfSTSG_HBFS_EKS_Fehler 0 "kein_Fehler" 1 "Fehler" ;
VAL_ 624 EmpfSTSG_HBFS_EKS_betaetigt 0 "nicht_betaetigt" 1 "betaetigt" ;
VAL_ 624 EmpfSTSG_HBFS_DatenUeb_Fehler 0 "kein_Fehler" 1 "Fehler" ;
VAL_ 623 EmpfSTSG_HFS_Status_KiSi 0 "inaktiv" 1 "aktiv" ;
VAL_ 623 EmpfSTSG_HFS_KiSi_Fehler 0 "kein_Fehler" 1 "Fehler" ;
VAL_ 623 EmpfSTSG_HFS_FH_normiert 0 "inaktiv" 1 "aktiv" ;
VAL_ 623 EmpfSTSG_HFS_TAG_betaetigt 0 "nicht_betaetigt" 1 "betaetigt" ;
VAL_ 623 EmpfSTSG_HFS_Vorraste_betaetigt 0 "nicht_in_Vorraste" 1 "in_Vorraste" ;
VAL_ 623 EmpfSTSG_HFS_TIG_bet_schliessen 0 "nicht_betaetigt" 1 "betaetigt" ;
VAL_ 623 EmpfSTSG_HFS_TIG_bet_oeffnen 0 "nicht_betaetigt" 1 "betaetigt" ;
VAL_ 623 EmpfSTSG_HFS_SK_betaetigt 0 "ausgehoben" 1 "eingefallen" ;
VAL_ 623 EmpfSTSG_HFS_EKS_Fehler 0 "kein_Fehler" 1 "Fehler" ;
VAL_ 623 EmpfSTSG_HFS_EKS_betaetigt 0 "nicht_betaetigt" 1 "betaetigt" ;
VAL_ 623 EmpfSTSG_HFS_DatenUeb_Fehler 0 "kein_Fehler" 1 "Fehler" ;
VAL_ 2589283970 DIST_DKmtg_Auth 0 "Init" 0 "Fehler" ;
VAL_ 2331595989 DIST_DKmtg 0 "Init" 0 "Fehler" ;
VAL_ 2589283751 KBI_Kilometerstand_Extended 16777214 "Init" 16777215 "Fehler" ;
VAL_ 258 ESP_QBit_Gierrate 0 "gueltiger_Wert" 1 "Ersatz_Init_oder_Fehlerwert" ;
VAL_ 258 ESP_QBit_Laengsbeschl 0 "gueltiger_Wert" 1 "Ersatz_Init_oder_Fehlerwert" ;
VAL_ 258 ESP_QBit_Querb 0 "gueltiger_Wert" 1 "Ersatz_Init_oder_Fehlerwert" ;
VAL_ 258 ESP_Querbeschleunigung 255 "Fehler" ;
VAL_ 258 ESP_Laengsbeschl 1022 "Signal_nicht_vorhanden" 1023 "Fehler" ;
VAL_ 258 ESC_Motorstartverzoegerung 0 "Startfreigabe" 1 "Anforderung_Startverzoegerung" ;
VAL_ 258 ESC_SeitenwindAssistent_Eingriff 0 "Kein_SWA_Eingriff_und_Init" 1 "SWA_Eingriff_aktiv" ;
VAL_ 258 ESP_Anschleppstart_Freigabe 0 "kein_Schleppstart_oder_NotSchleppstart_erlaubt" 1 "NotSchleppstart_erlaubt" 2 "Schleppstart_und_NotSchleppStart_erlaubt" ;
VAL_ 258 ESC_Unterdruckmangel_erkannt 0 "kein_Unterdruckmangel_erkannt" 1 "Unterdruckmangel_erkannt" ;
VAL_ 258 ESP_Gierrate 16383 "Fehler" ;
VAL_ 258 ESP_VZ_Gierrate 0 "positiv" 1 "negativ" ;
VAL_ 258 ESP_Notbremsanzeige 0 "keine_Notbremsung_erkannt" 1 "Notbremsung_erkannt" ;
VAL_ 258 ESP_SpannungsAnf 0 "keine_Anforderung" 1 "Anforderung_Spannungswert_1" ;
VAL_ 258 ESP_PLA_Abbruch 0 "Init" 1 "Geschwindigkeitsueberschreitung" 2 "Falscher_PLA_Status" 3 "Deaktivierung_durch_Abbruch_Lenkung" 4 "PLA_Bremsanforderung_nach_Stillstand" 5 "Abbruch_durch_Kl15_aus" 6 "Abbruch_durch_FT_offen" ;
VAL_ 258 ESP_Status_ESP_PLA 0 "ESP_PLA_deaktiv" 1 "ESP_PLA_Init" 2 "ESP_PLA_Fehler" 4 "ESP_PLA_aktivierbar" 6 "ESP_PLA_Bremse_aktiv" 8 "ESP_PLA_funktionsbereit" 9 "ESP_PLA_Neustart" 10 "ESP_PLA_Abbruch" ;
VAL_ 258 ESP_QBit_Bremsdruck 0 "gueltiger_Wert" 1 "Ersatz_Init_oder_Fehlerwert" ;
VAL_ 258 ESP_QBit_Fahrer_bremst 0 "gueltiger_Wert" 1 "Ersatz_Init_oder_Fehlerwert" ;
VAL_ 258 ESP_Schwelle_Unterdruck 0 "kein_Signal" 1 "Unterdruck_kleiner_gleich_450_mbar" 2 "Unterdruck_groesser_450_mbar" 3 "Fehler_Unterdrucksensor" ;
VAL_ 258 ESP_Bremsdruck 1023 "Fehler" ;
VAL_ 258 ESP_Fahrer_bremst 0 "Bremsdruckschwelle_nicht_ueberschritten" 1 "Bremsdruckschwelle_ueberschritten" ;
VAL_ 258 ESP_Verz_TSK_aktiv 0 "TSK_Verzoegerung_inaktiv" 1 "TSK_Verzoegerung_aktiv" ;
VAL_ 258 ESP_Lenkeingriff_ADS 0 "kein_Lenkeingriff" 1 "stabilisierender_Lenkeingriff" ;
VAL_ 258 ESP_Konsistenz_TSK 0 "Botschaft_fuer_Verzoegerungsanforderung_konsistent" 1 "Botschaft_fuer_Verzoegerungsanforderung_nicht_konsistent" ;
VAL_ 258 ESP_Bremsruck_AWV2 0 "kein_Bremsruck_ausgefuehrt" 1 "Bremsruck_ausgefuehrt" ;
VAL_ 258 ESP_Konsistenz_AWV2 0 "Botschaft_fuer_AWV2_konsistent" 1 "Botschaft_fuer_AWV2_nicht_konsistent" ;
VAL_ 258 ECD_Fehler 0 "ECD_iO" 1 "ECD_Fehler" ;
VAL_ 258 ECD_nicht_verfuegbar 0 "ECD_Funktion_verfuegbar" 1 "ECD_Funktion_nicht_verfuegbar" ;
VAL_ 258 ESP_Status_Bremsentemp 0 "Bremse_nicht_ueberhitzt" 1 "Bremse_ueberhitzt" ;
VAL_ 258 ESP_Autohold_Standby 0 "Autohold_nicht_im_Standby" 1 "Autohold_im_Standby" ;
VAL_ 258 ESP_HDC_Standby 0 "HDC_Funktion_nicht_im_Standby" 1 "HDC_Funktion_im_Standby" ;
VAL_ 258 ESP_HBA_aktiv 0 "HBA_nicht_aktiv" 1 "HBA_aktiv" ;
VAL_ 258 ESP_Prefill_ausgeloest 0 "nicht_ausgeloest" 1 "Prefill_ausgeloest" ;
VAL_ 258 ESP_Rueckwaertsfahrt_erkannt 0 "keine_Rueckwaetsfahrt" 1 "Rueckwaertsfahrt_sicher_erkannt" ;
VAL_ 258 ESP_Status_Anfahrhilfe 0 "Aus" 1 "Ein" ;
VAL_ 258 ESP_HDC_aktiv 0 "inaktiv" 1 "aktiv" ;
VAL_ 258 ESP_StartStopp_Info 0 "Motorlauf_nicht_notwendig_(Stoppfreigabe)" 1 "Motoranlauf_nicht_zwingend_notwendig_(Stoppverbot,keine_Startanforderung)" 2 "Motoranlauf_zwingend_notwendig_(Startanforderung)" 3 "Systemfehler" ;
VAL_ 258 ESP_Eingr_HL 0 "kein_Eingriff" 1 "ESP_Eingriff_HL" ;
VAL_ 258 ESP_Eingr_HR 0 "kein_Eingriff" 1 "ESP_Eingriff_HR" ;
VAL_ 258 ESP_Eingr_VL 0 "kein_Eingriff" 1 "ESP_Eingriff_VL" ;
VAL_ 258 ESP_Eingr_VR 0 "kein_Eingriff" 1 "ESP_Eingriff_VR" ;
VAL_ 258 ESP_BKV_Unterdruck 0 "nicht_verbaut_oder_nicht_kodiert" 254 "Init" 255 "Fehler" ;
VAL_ 258 ESP_Autohold_aktiv 0 "Autohold_inaktiv" 1 "Autohold_aktiv" ;
VAL_ 258 ESP_FStatus_Anfahrhilfe 0 "kein_Fehler" 1 "Fehler" ;
VAL_ 258 ESP_Verz_EPB_aktiv 0 "nicht_aktiviert" 1 "aktiviert" ;
VAL_ 258 ECD_Bremslicht 0 "Aus" 1 "Ein" ;
VAL_ 258 ESP_Verzoeg_EPB_verf 0 "nicht_verfuegbar" 1 "System_verfuegbar" ;
VAL_ 258 ESP_Status_Bremsdruck 0 "Bremse_drucklos" 1 "mit_Bremsdruck" ;
VAL_ 258 ESP_Anforderung_EPB 0 "keine_Anforderung" 1 "Anforderung_Oeffnen" 2 "Anforderung_Schliessen" 3 "reserviert" ;
VAL_ 258 ESC_Fahrerradbremswunschmoment 4094 "Init" 4095 "Fehler" ;
VAL_ 258 ESP_ANB_CM_Rueckk_Umsetz 0 "keine_Ausfuehrung" 1 "Ausfuehrung" ;
VAL_ 258 ESP_Konsistenz_ACC_Botschaft 0 "Botschaft_fuer_ACC_konsistent" 1 "Botschaft_fuer_ACC_nicht_konsistent" ;
VAL_ 258 ESP_Stillstandsphase_erschoepft 0 "sicheres_Halten_moeglich" 1 "kein_sicheres_Halten_moeglich" ;
VAL_ 258 ESP_ZT_Rueckk_Umsetz 0 "keine_Ausfuehrung" 1 "Ausfuehrung" ;
VAL_ 258 ESP_Tuerkontakt_Fahrertuer 0 "Schalter_geschlossen" 1 "Schalter_offen" ;
VAL_ 258 ESP_Abrutschen_Stillstand 0 "kein_Abrutschen_erkannt" 1 "Abrutschen_erkannt" ;
VAL_ 258 ESP_Fahrer_tritt_ZBR_Schw 0 "Fahrer_uebertritt_ZBR_Schwelle_nicht" 1 "Fahrer_uebertritt_ZBR_Schwelle" ;
VAL_ 258 ESP_Systemstatus_03 0 "ESC_passiv_getastet" 1 "ESC_Schwellen_geaendert" 2 "ESC_aktiviert" 3 "Fehler" ;
VAL_ 258 ASR_Systemstatus 0 "ASR_passiv_getastet" 1 "ASR_Schwellen_geaendert" 2 "ASR_aktiviert" 3 "ASR_Stoerung" ;
VAL_ 258 ESP_QBit_v_ref 0 "gueltiger_Wert" 1 "Ersatz_Init_oder_Fehlerwert" ;
VAL_ 258 ESP_v_ref_Fahrtrichtung 0 "Fahrtrichtung_nicht_definiert" 1 "Vorwaerts" 2 "Rueckwaerts" 3 "Stillstand" ;
VAL_ 258 ESC_Bremsdruckgradient 251 "groesser_2500_bar_per_sec" 254 "Init" 255 "Fehler" ;
VAL_ 258 ESP_v_ref 4093 "Unterspannung" 4094 "Init" 4095 "Fehler" ;
VAL_ 258 ESP_HBA_Empfindlichkeit 0 "Init" 1 "unempfindlich" 2 "normal" 3 "empfindlich" 4 "sehr_empfindlich" 5 "reserviert" 6 "reserviert" 7 "Fehler" ;
VAL_ 258 ESC_Hydr_Fkt_aktiv 0 "keine_Aktivitaet" 1 "ESC_Druckaufbau_HBx_HFC_aktiv" 2 "Warnrucklevel_Summand_1" 3 "Warnrucklevel_Summand_3" ;
VAL_ 258 ESC_QBit_Fahrerbremswunsch 0 "gueltiger_Wert" 1 "Ersatz_Init_oder_Fehlerwert" ;
VAL_ 258 ESC_Fahrerbremswunsch 1023 "Fehler" ;
VAL_ 258 ESCGeneratorSollMoment 4094 "Init" 4095 "Fehler" ;
VAL_ 258 ESC_Raddruck_max 254 "Init" 255 "Fehler" ;
VAL_ 258 EPB_QBit_Pedalweg_Kuppl 0 "gültiger Wert" 1 "Ersatz-, Init- oder Fehlerwert" ;
VAL_ 258 EPB_Freig_Verzoeg_Anf 0 "nicht freigegeben" 1 "freigegeben" ;
VAL_ 258 EPB_Pedalweg_Kuppl 0 "Init" 255 "Fehler" ;
VAL_ 258 EPB_DAA_Randbed_erf 0 "Randbed_nicht_erfuellt" 1 "Randbed_erfuellt" ;
VAL_ 258 EPB_Fehlerstatus_02 0 "kein_Fehler" 1 "Fehler_ausserhalb_apply_release" 2 "Fehler_einseitig_apply_release" 3 "Fehler_beidseitig_apply_release" ;
VAL_ 258 EPB_Schalterposition 0 "keine Fahreranforderung" 1 "Fahreranforderung Öffnen" 2 "Fahreranforderung Schließen" 3 "Fehler" ;
VAL_ 258 EPB_QBit_Schalterpos 0 "gültiger Wert (volle Funktion)" 1 " Ersatz-, Init- oder Fehlerwert (Schalter ausser Funktion)" ;
VAL_ 258 EPB_Spannkraft 30 "Init" 31 "Fehler" ;
VAL_ 258 EPB_Status_02 0 "offen" 1 "geschlossen_Parken" 2 "teilgespannt_Halten" 3 "im_Lauf_oeffnen" 4 "im_Lauf_schliessen" 5 "tbd" 6 "Init" 7 "unbekannt" ;
VAL_ 258 EPB_Status 0 "offen" 1 "Bremse_geschl_(Spannkraft_voll/reduziert)" 2 "Aktuator_im_Lauf" 3 "Fehler_oder_unbekannt" ;
VAL_ 258 ESP_Status_Bremsentemp_02 0 "nicht_erhoeht" 1 "Schwelle_1" 2 "Schwelle_2" ;
